VERSION ""

NS_ :

BS_:

BU_: AGSM ECM EVCU2 MCPA MCPB SGCP TCM

BO_ 125 GLIWA_SGCP_TX: 8 SGCP
 SG_ N_PDU_7D : 7|64@0+ (1,0) [0|0] ""  EVCU2

BO_ 129 GLIWA_SGCP_RX: 8 EVCU2
 SG_ N_PDU_81 : 7|64@0+ (1,0) [0|0] ""  SGCP

BO_ 126 GLIWA_MCPA_RX: 8 EVCU2
 SG_ N_PDU_7E : 7|64@0+ (1,0) [0|0] ""  MCPA

BO_ 123 GLIWA_MCPA_TX: 8 MCPA
 SG_ N_PDU_7B : 7|64@0+ (1,0) [0|0] ""  EVCU2

BO_ 127 GLIWA_MCPB_RX: 8 EVCU2
 SG_ N_PDU_7F : 7|64@0+ (1,0) [0|0] ""  MCPB

BO_ 124 GLIWA_MCPB_TX: 8 MCPB
 SG_ N_PDU_7C : 7|64@0+ (1,0) [0|0] ""  EVCU2

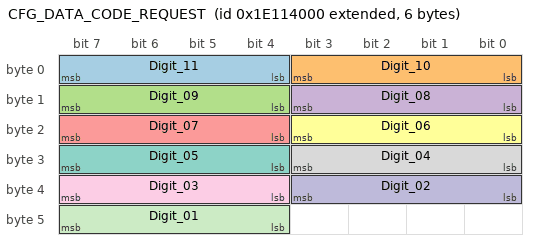
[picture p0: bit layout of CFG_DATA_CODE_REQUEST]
BO_ 2651930624 CFG_DATA_CODE_REQUEST: 6 EVCU2
 SG_ Digit_11 : 7|4@0+ (1,0) [0|15] ""  SGCP,MCPB,MCPA
 SG_ Digit_10 : 3|4@0+ (1,0) [0|15] ""  SGCP,MCPB,MCPA
 SG_ Digit_09 : 15|4@0+ (1,0) [0|15] ""  SGCP,MCPB,MCPA
 SG_ Digit_08 : 11|4@0+ (1,0) [0|15] ""  SGCP,MCPB,MCPA
 SG_ Digit_07 : 23|4@0+ (1,0) [0|15] ""  SGCP,MCPB,MCPA
 SG_ Digit_06 : 19|4@0+ (1,0) [0|15] ""  SGCP,MCPB,MCPA
 SG_ Digit_05 : 31|4@0+ (1,0) [0|15] ""  SGCP,MCPB,MCPA
 SG_ Digit_04 : 27|4@0+ (1,0) [0|15] ""  SGCP,MCPB,MCPA
 SG_ Digit_03 : 39|4@0+ (1,0) [0|15] ""  SGCP,MCPB,MCPA
 SG_ Digit_02 : 35|4@0+ (1,0) [0|15] ""  SGCP,MCPB,MCPA
 SG_ Digit_01 : 47|4@0+ (1,0) [0|15] ""  SGCP,MCPB,MCPA

BO_ 2564502513 DIAGNOSTIC_REQUEST_FUNC_OBD: 8 EVCU2
 SG_ N_PDU_18DB33F1 : 7|64@0+ (1,0) [0|0] ""  SGCP,MCPB,MCPA

BO_ 1450 TRANSM_FD_4: 32 TCM
 SG_ TxDisengaged : 126|1@0+ (1,0) [0|1] "-"  ECM
 SG_ TransmissionFailSts : 87|1@0+ (1,0) [0|1] "-"  AGSM
 SG_ ShiftLeverPosition : 111|4@0+ (1,0) [0|15] "-"  AGSM,ECM
 SG_ ShiftLeverLockReq : 101|1@0+ (1,0) [0|1] "-"  AGSM
 SG_ ShiftInProgress : 114|1@0+ (1,0) [0|1] "-"  ECM
 SG_ MIReq : 127|1@0+ (1,0) [0|1] "-"  ECM
 SG_ LimpHomeSts : 112|1@0+ (1,0) [0|1] "-"  ECM
 SG_ GearIndicationSts : 95|1@0+ (1,0) [0|1] "-"  AGSM
 SG_ GearEngaged : 107|4@0+ (1,0) [0|15] "-"  ECM
 SG_ CrankEnable : 113|1@0+ (1,0) [0|1] "-" Vector__XXX
 SG_ ShiftMapNotAchieved : 121|1@0+ (1,0) [0|1] "-" Vector__XXX
 SG_ R_SHFT_LOCK : 116|1@0+ (1,0) [0|1] "-"  AGSM
 SG_ MessageCounter_TRANSM4 : 179|4@0+ (1,0) [0|15] "-"  AGSM,ECM
 SG_ CRC_TRANSM4 : 191|8@0+ (1,0) [0|255] "-"  AGSM,ECM
 SG_ DriveModeSts : 83|4@0+ (1,0) [0|15] "-"  ECM
 SG_ TxDisengaged_Fault : 118|1@0+ (1,0) [0|1] "-"  ECM
 SG_ Lowmode_Indication_Sts : 183|2@0+ (1,0) [0|3] ""  AGSM
 SG_ Low_Mode_Sts : 181|2@0+ (1,0) [0|3] ""  AGSM

BO_ 520 TRANSM_FD_2: 32 TCM
 SG_ TurbineSpeed : 111|16@0+ (1,0) [0|65534] "RPM"  ECM
 SG_ TRNS_StpSt_FLT : 125|1@0+ (1,0) [0|1] "-"  ECM
 SG_ Trns_EMCC_Achvd : 96|1@0+ (1,0) [0|1] "-"  ECM
 SG_ TransReadyForESS : 124|1@0+ (1,0) [0|1] "-"  ECM
 SG_ TransmissionTemperature : 103|6@0+ (3,-40) [-40|149] "°C"  ECM
 SG_ OUTPUT_SPEED : 87|16@0+ (1,0) [0|65534] "RPM"  ECM
 SG_ APCM_Rq : 135|2@0+ (1,0) [0|2] "-"  AGSM,ECM
 SG_ MessageCounter_TRANSM2 : 179|4@0+ (1,0) [0|15] "-"  AGSM,ECM
 SG_ EngShutOffRq_TCM : 123|1@0+ (1,0) [0|1] "-"  ECM
 SG_ CRC_TRANSM2 : 191|8@0+ (1,0) [0|255] "-"  AGSM,ECM
 SG_ Trans_ESS_Inhibit : 2|1@0+ (1,0) [0|1] "-"  ECM
 SG_ OutputSpdPolarity : 1|2@0+ (1,0) [0|2] "-" Vector__XXX
 SG_ GearEngagedForDisplay : 15|5@0+ (1,0) [0|30] "-"  AGSM,ECM
 SG_ AirFlowRequest_TCM : 22|7@0+ (1,0) [0|100] "%"  ECM
 SG_ TrqCtrlModeReq_Prdtd : 129|2@0+ (1,0) [0|3] "-"  ECM
 SG_ TCM_TrqGradLimActive : 161|1@0+ (1,0) [0|1] "-"  ECM
 SG_ TCM_TrqGradLim_Up : 151|8@0+ (49.8,-6325) [-6325|6374] "Nm/s"  ECM
 SG_ TCM_TrqGradLim_Lo : 159|8@0+ (49.8,-6325) [-6325|6374] "Nm/s"  ECM
 SG_ TCM_EngFSO_Rq : 120|1@0+ (1,0) [0|1] "-"  ECM
 SG_ TCM_EngFSO_Allw : 62|1@0+ (1,0) [0|1] "-"  ECM
 SG_ TCC_TR : 143|8@0+ (0.125,0) [0|31.875] "Nm" Vector__XXX
 SG_ TransInputSpeedMaxReq : 57|10@0+ (16,0) [0|16368] "rpm"  ECM

BO_ 156 TELEMATIC_FD_1: 32 EVCU2
 SG_ GPS_UTC_Second : 151|16@0+ (0.01,0) [0|59.99] "s"  MCPB,MCPA
 SG_ GPS_UTC_Minute : 47|8@0+ (1,0) [0|59] "min"  MCPB,MCPA
 SG_ GPS_UTC_Hour : 55|8@0+ (1,0) [0|23] "h"  MCPB,MCPA
 SG_ GPS_Date_Year : 167|16@0+ (1,0) [0|65534] "Years"  MCPB,MCPA
 SG_ GPS_Date_Month : 71|8@0+ (1,0) [1|12] "Months"  MCPB,MCPA
 SG_ GPS_Date_Day : 63|8@0+ (1,0) [1|31] "Days"  MCPB,MCPA

BO_ 1058 OBD_CONTENT_FRAME: 32 ECM
 SG_ LoadOBD : 87|8@0+ (0.3922,0) [0|100] "%"  TCM
 SG_ InputsGDFail : 94|1@0+ (1,0) [0|1] "-"  TCM
 SG_ Inp_ICC_Fail : 117|1@0+ (1,0) [0|1] "-"  TCM
 SG_ IgnCntrTrue : 118|1@0+ (1,0) [0|1] "-"  TCM
 SG_ GenDenominator : 95|1@0+ (1,0) [0|1] "-"  TCM
 SG_ EngineOFFTime : 89|10@0+ (1,0) [0|1022] "min"  TCM
 SG_ CldStrtDenominator : 116|1@0+ (1,0) [0|1] "-" Vector__XXX
 SG_ CarbWarmUp : 93|1@0+ (1,0) [0|1] "-"  TCM
 SG_ CARB_PERM : 119|1@0+ (1,0) [0|1] "-"  TCM
 SG_ AccelPdlPosn_OBD : 111|8@0+ (0.3922,0) [0|100] "%"  TCM
 SG_ OAT_PT_EstV : 60|1@0+ (1,0) [0|0] "-"  EVCU2
 SG_ OAT_PT_Est : 55|8@0+ (1,-64) [-64|191] "°C"  EVCU2
 SG_ EngOffTmPTV : 5|1@0+ (1,0) [0|0] "-"  EVCU2
 SG_ EngOffTmPT : 3|12@0+ (0.5,0) [0.5|2047.5] "min"  EVCU2
 SG_ MessageCounter_OBDCONTENTFRAME : 179|4@0+ (1,0) [0|15] "-"  EVCU2,TCM
 SG_ CRC_OBDCONTENTFRAME : 191|8@0+ (1,0) [0|255] "-"  EVCU2,TCM

BO_ 1626 IMPACT_INFO: 32 EVCU2
 SG_ IMPACTConfirm : 81|1@0+ (1,0) [0|1] "-"  MCPB,MCPA
 SG_ IMPACTCommand : 80|1@0+ (1,0) [0|1] "-"  MCPB,MCPA

BO_ 1055 ENGINE_FD_8: 32 ECM
 SG_ MdsAct : 25|1@0+ (1,0) [0|1] "-"  TCM
 SG_ MessageCounter_ENGINE8 : 179|4@0+ (1,0) [0|15] "-"  TCM
 SG_ CRC_ENGINE8 : 191|8@0+ (1,0) [0|255] "-"  TCM

BO_ 1448 ENGINE_FD_7: 32 ECM
 SG_ CompressorSts : 85|2@0+ (1,0) [0|3] "-"  TCM
 SG_ SpStSwStat : 55|2@0+ (1,0) [0|3] "-" Vector__XXX
 SG_ SpStDispstat : 53|6@0+ (1,0) [0|63] "-"  TCM
 SG_ MessageCounter_ENGINE7 : 179|4@0+ (1,0) [0|15] "-"  TCM
 SG_ CRC_ENGINE7 : 191|8@0+ (1,0) [0|255] "-"  TCM

BO_ 751 ENGINE_FD_6: 32 ECM
 SG_ StartRelayECMFeedbackFault : 163|1@0+ (1,0) [0|1] "-" Vector__XXX
 SG_ EngineWaterTemp : 95|8@0+ (1,-40) [-40|215] "°C"  TCM
 SG_ TerrainModeStat_ECM : 61|5@0+ (1,0) [0|30] ""  TCM
 SG_ MessageCounter_ENGINE6 : 179|4@0+ (1,0) [0|15] "-"  TCM
 SG_ CRC_ENGINE6 : 191|8@0+ (1,0) [0|255] "-"  TCM
 SG_ Trns_DrvMdReq_ECM : 77|5@0+ (1,0) [0|30] "-"  TCM

BO_ 518 ENGINE_FD_5: 32 ECM
 SG_ RPMOverRev_W : 115|1@0+ (1,0) [0|1] "-"  EVCU2
 SG_ MessageCounter_ENGINE5 : 179|4@0+ (1,0) [0|15] "-"  EVCU2,TCM
 SG_ GrMin_Rq_ECM_W : 139|4@0+ (1,0) [0|15] "-"  TCM
 SG_ GrMax_Rq_ECM_W : 135|4@0+ (1,0) [0|15] "-"  TCM
 SG_ EngTrqMaxCorrFctr_W : 127|8@0+ (0.0078,0) [0|1.98] "Nm"  TCM
 SG_ EngineReadyForESS_W : 116|1@0+ (1,0) [0|1] "-"  TCM
 SG_ ECM_READINESS_RESET_W : 140|1@0+ (1,0) [0|0] "0"  TCM
 SG_ ECM_CODE_CLR_W : 141|1@0+ (1,0) [0|0] "0"  TCM
 SG_ CRC_ENGINE5 : 191|8@0+ (1,0) [0|255] "-"  EVCU2,TCM

BO_ 1054 ENGINE_FD_1: 32 ECM
 SG_ VehicleSetSpeed_W : 151|8@0+ (1,0) [0|250] "km/h(mph)"  TCM
 SG_ TransWarmUpReq : 3|1@0+ (1,0) [0|1] "-"  TCM
 SG_ TransWarmUpMin_RPM : 159|8@0+ (25,0) [0|6375] "rpm"  TCM
 SG_ ThermalManagementActive_W : 1|1@0+ (1,0) [0|1] "-"  EVCU2,TCM
 SG_ MessageCounter_ENGINE1 : 179|4@0+ (1,0) [0|15] "-"  EVCU2,TCM
 SG_ EngMaxRPM_W : 127|8@0+ (50,0) [0|10000] "-"  TCM
 SG_ CRC_ENGINE1 : 191|8@0+ (1,0) [0|255] "-"  EVCU2,TCM
 SG_ AtmosphericPressureFailSts_W : 0|1@0+ (1,0) [0|1] "-"  TCM
 SG_ AtmosphericPressure_W : 143|8@0+ (3.6,300) [300|1214.4] "mbar"  TCM

BO_ 2654817816 ECU_APPL_FD_TCM: 64 TCM
 SG_ ECU_APPL_FD_TCM : 455|64@0+ (1,0) [0|0] "" Vector__XXX

BO_ 2564554482 DIAGNOSTIC_REQUEST_FD_FUNCTIONAL: 64 EVCU2
 SG_ N_PDU_18DBFEF2 : 7|64@0+ (1,0) [0|0] ""  SGCP,MCPB,MCPA

BO_ 1155 BRAKE_FD_5: 32 EVCU2
 SG_ ESCFailSts : 83|1@0+ (1,0) [0|1] "-"  MCPB
 SG_ ABSFailSts : 87|1@0+ (1,0) [0|1] "-"  MCPB

BO_ 609 BRAKE_FD_4: 32 EVCU2
 SG_ EPBSts : 115|4@0+ (1,0) [0|14] "-"  SGCP,MCPB,MCPA

BO_ 1066 BCM_FD_9: 32 EVCU2
 SG_ ExternalTemperature : 0|9@0+ (0.5,-85) [-85|170] "°C"  SGCP,MCPB,MCPA

BO_ 1153 BCM_FD_10: 32 EVCU2
 SG_ CmdIgnSts : 138|3@0+ (1,0) [0|7] ""  MCPB,MCPA,AGSM
 SG_ MessageCounter_BCM10 : 179|4@0+ (1,0) [0|15] "-"  MCPB
 SG_ CRC_BCM10 : 191|8@0+ (1,0) [0|255] "-"  MCPB

BO_ 255 PT_TORQUE_FD_1: 48 ECM
 SG_ SumTorqueTgt_SEM : 130|11@0+ (1,-500) [-500|1546] "Nm"  TCM
 SG_ SumTorqueStatic_SEM : 114|11@0+ (1,-500) [-500|1546] "Nm"  TCM
 SG_ SumTorqueStatic : 98|11@0+ (1,-500) [-500|1546] "Nm"  TCM
 SG_ SumTorqueSel_D_TTC : 82|11@0+ (1,-500) [-500|1546] "Nm"  TCM
 SG_ SumTorqueMin : 66|11@0+ (1,-500) [-500|1546] "Nm"  TCM
 SG_ SumTorqueMax : 50|11@0+ (1,-500) [-500|1546] "Nm"  TCM
 SG_ SumTorque_DrvReqMod : 20|13@0+ (0.25,-500) [-500|1547.5] "Nm"  TCM
 SG_ MessageCounter_PT_TORQUE_FD_1 : 307|4@0+ (1,0) [0|15] "-"  TCM
 SG_ CRC_PT_TORQUE_FD_1 : 319|8@0+ (1,0) [0|255] "-"  TCM
 SG_ Accel_Pedal_Override : 37|1@0+ (1,0) [0|1] "-" Vector__XXX

BO_ 1032 HYBRID_THERMAL_COMMAND: 32 EVCU2
 SG_ MessageCounter_HYBRID_THERMAL_CO : 179|4@0+ (1,0) [0|15] "-"  SGCP,MCPB,MCPA,ECM
 SG_ CRC_HYBRID_THERMAL_COMMAND : 191|8@0+ (1,0) [0|255] "-"  SGCP,MCPB,MCPA,ECM
 SG_ SGCP_OIL_TEMP : 175|8@0+ (1,-50) [-50|205] "°C"  SGCP
 SG_ SGCP_OIL_FlwRate : 135|8@0+ (0.1,0) [0|25.4] "LPM"  SGCP
 SG_ EOPB_OIL_TEMP : 151|8@0+ (1,-50) [-50|205] "°C"  MCPB
 SG_ EOPB_OIL_FlwRate : 167|8@0+ (0.1,0) [0|25.4] "LPM"  MCPB
 SG_ EOPA_OIL_TEMP : 143|8@0+ (1,-50) [-50|205] "°C"  MCPA
 SG_ EOPA_OIL_FlwRate : 159|8@0+ (0.1,0) [0|25.4] "LPM"  MCPA

BO_ 267 HYBRID_SYSTEM_EPT1: 32 EVCU2
 SG_ WU_Timer_Value : 23|16@0+ (1,0) [0|65535] "min"  MCPB,MCPA
 SG_ PerWakeUp_Diag : 33|10@0+ (1,0) [0|1023] "-"  MCPB,MCPA

BO_ 1033 HYBRID_POWERTRAIN5: 32 EVCU2
 SG_ IdleCLoopTrq : 33|10@0+ (0.32,-163.52) [-163.52|163.52] "Nm"  ECM
 SG_ HEV_HybPwrtrnRdcdPerfCmnd : 22|1@0+ (1,0) [0|0] "-"  ECM
 SG_ HCPMaxEngRPM : 63|8@0+ (32,0) [0|8128] "rpm"  ECM
 SG_ CRC_HYBRID_POWERTRAIN5 : 191|8@0+ (1,0) [0|255] "-"  ECM
 SG_ MessageCounter_HYBRID_POWERTRAIN : 179|4@0+ (1,0) [0|15] "-"  ECM
 SG_ HCP_HoodAjar : 35|2@0+ (1,0) [0|2] ""  ECM

BO_ 1328 ENGINE_HYBD_FD_4: 32 ECM
 SG_ EngTorqCapbltyMinTorq : 51|12@0+ (0.32,-300.16) [-300.16|1008] "Nm"  EVCU2
 SG_ EngTorqCapbltyMaxTorq : 19|12@0+ (0.32,-300.16) [-300.16|1008] "Nm"  EVCU2
 SG_ EngTorqCapbltyMaxOffTorq : 3|12@0+ (0.32,-300.16) [-300.16|1008] "Nm"  EVCU2
 SG_ EngTorqCapbltyRefEngSpd : 71|8@0+ (32,0) [0|8160] "rpm"  EVCU2
 SG_ EngTorqCapbltyMinRunTorq : 35|12@0+ (0.32,-300.16) [-300.16|1008] "Nm"  EVCU2
 SG_ EngTorqCapbltyFrmCntr : 7|4@0+ (1,0) [0|15] "-"  EVCU2
 SG_ EngTorqCapbltyEngOpMd : 21|1@0+ (1,0) [0|0] "-"  EVCU2
 SG_ EngTorqACCCapability : 79|8@0+ (0.32,0) [0|81.28] "Nm"  EVCU2
 SG_ MessageCounter_ENGINE_HYBD_FD_4 : 179|4@0+ (1,0) [0|15] "-"  EVCU2
 SG_ CRC_ENGINE_HYBD_FD_4 : 191|8@0+ (1,0) [0|255] "-"  EVCU2

BO_ 1035 ENGINE_HYBD_FD_3: 32 ECM
 SG_ MaxEngSpdCap : 52|13@0+ (1,0) [0|8160] "rpm"  EVCU2
 SG_ ServiceHybSys : 55|1@0+ (1,0) [0|0] "-"  EVCU2
 SG_ MinEngSpdCap : 68|13@0+ (1,0) [0|8160] "rpm"  EVCU2
 SG_ EngSpd : 7|16@0+ (0.125,0) [0|8160] "rpm"  EVCU2
 SG_ EngCltTmpV : 69|1@0+ (1,0) [0|1] ""  EVCU2
 SG_ EngCltTmp : 167|8@0+ (1,-40) [-40|214] "°C"  EVCU2
 SG_ MessageCounter_ENGINE_HYBD_FD_3 : 179|4@0+ (1,0) [0|15] "-"  EVCU2
 SG_ CRC_ENGINE_HYBD_FD_3 : 191|8@0+ (1,0) [0|255] "-"  EVCU2

BO_ 1036 ENGINE_FD_3: 32 ECM
 SG_ CruiseControlSts : 162|1@0+ (1,0) [0|1] "-"  TCM
 SG_ CruiseControlLampSts : 164|1@0+ (1,0) [0|1] "-"  TCM
 SG_ MessageCounter_ENGINE3 : 179|4@0+ (1,0) [0|15] "-"  TCM
 SG_ CRC_ENGINE3 : 191|8@0+ (1,0) [0|255] "-"  TCM
 SG_ EngineOilTemperature : 103|8@0+ (1,-40) [-40|214] "°C"  TCM

BO_ 278 TRANSM_FD_1: 64 TCM
 SG_ TransmissionSailingSts : 119|4@0+ (1,0) [0|15] "-" Vector__XXX
 SG_ TransLosses : 241|10@0+ (1,-500) [-500|522] "Nm"  ECM
 SG_ TorqueConverterSts : 55|2@0+ (1,0) [0|3] "-"  ECM
 SG_ TorqueConverterSTO : 195|1@0+ (1,0) [0|1] "-"  ECM
 SG_ TargetGear : 151|4@0+ (1,0) [0|15] "-"  ECM
 SG_ MaxTrqDes : 162|11@0+ (1,-500) [-500|1546] "Nm"  ECM
 SG_ EngTrq_Rq_TCM : 178|11@0+ (1,-500) [-500|1546] "Nm"  ECM
 SG_ CRC_TRANSM1 : 447|8@0+ (1,0) [0|255] "-"  ECM
 SG_ REPRGD_PFC_CLR_TCM : 275|1@0+ (1,0) [0|0] "-"  ECM
 SG_ PaddleShiftRequest : 399|3@0+ (1,0) [0|6] "-"  ECM
 SG_ MessageCounter_TRANSM1 : 435|4@0+ (1,0) [0|15] "-"  ECM
 SG_ DriveLineRatio : 405|14@0+ (0.01,0) [0|163.83] "-"  ECM
 SG_ CODE_CLR_TCM : 258|1@0+ (1,0) [0|0] "-"  ECM
 SG_ TxIdleRq : 351|8@0+ (8,0) [0|2032] "rpm"  ECM
 SG_ TCASERANGESTATUS_TCM : 407|2@0+ (1,0) [0|2] "-"  ECM
 SG_ Trans_Adapt_Status : 423|4@0+ (1,0) [0|15] "-"  ECM
 SG_ TorqueAmpTransmission : 330|11@0+ (0.01,0) [0|20.46] "-"  ECM
 SG_ TrqCtrlModeReq : 23|2@0+ (1,0) [0|2] "-"  ECM
 SG_ TransIntakeTorq : 210|11@0+ (1.2,-1200) [-1200|1255.2] "Nm"  ECM
 SG_ CrankEnable_Fast : 211|1@0+ (1,0) [0|1] "-"  ECM
 SG_ EngTrq_Rq_TCM_Prdtd : 194|11@0+ (1,-500) [-500|1547] "Nm"  ECM
 SG_ PumpTrqOnImpShaft : 305|10@0+ (0.2,-102.4) [-102.4|102.2] "Nm"  ECM

BO_ 269 HYBRID_POWERTRAIN2: 64 EVCU2
 SG_ IdleSpeedActiveSts : 302|1@0+ (1,0) [0|0] "-"  ECM
 SG_ CRC_HYBRID_POWERTRAIN2 : 447|8@0+ (1,0) [0|255] "-"  ECM
 SG_ PropulsionMode : 39|3@0+ (1,0) [0|6] "-"  ECM
 SG_ HybridEngineMaxTorqAllowed : 115|12@0+ (0.32,-300.16) [-300.16|1008] "Nm"  ECM
 SG_ MessageCounter_HYBRID_POWER_0000 : 435|4@0+ (1,0) [0|15] "-"  ECM

BO_ 276 HYBRID_POWERTRAIN1: 64 EVCU2
 SG_ TransInpSpdPrfl : 68|13@0+ (1,0) [0|8191] "rpm"  ECM
 SG_ InputSpdRaw : 179|12@0+ (1,-2048) [-2048|2046] "rpm"  ECM
 SG_ Hybrid_Remedial_Stop : 290|1@0+ (1,0) [0|0] "-"  ECM
 SG_ HybFeedback_Engine : 294|1@0+ (1,0) [0|0] "-"  ECM
 SG_ HybEstEngTorqV : 280|1@0+ (1,0) [0|0] "-"  ECM
 SG_ HybEstEngTorq : 163|12@0+ (0.32,-300.16) [-300.16|1008] "Nm"  ECM
 SG_ HybCrnkAbrted : 282|1@0+ (1,0) [0|0] "-"  ECM
 SG_ HybCmndEngTorqRespTyp : 277|2@0+ (1,0) [0|0] "-"  ECM
 SG_ HybCmndEngTorqPrdtd : 147|12@0+ (0.32,-300.16) [-300.16|1008] "Nm"  ECM
 SG_ HybCmndEngTorqImmed : 131|12@0+ (0.32,-300.16) [-300.16|1008] "Nm"  ECM
 SG_ EngTrqReserveCmd : 263|8@0+ (0.32,0) [0|81.28] "Nm"  ECM
 SG_ EngCntrlMode : 283|1@0+ (1,0) [0|0] "-"  ECM
 SG_ ECMPrepIdleRes : 295|1@0+ (1,0) [0|0] "-"  ECM
 SG_ CRC_HYBRID_POWERTRAIN1 : 447|8@0+ (1,0) [0|255] "-"  ECM
 SG_ PropulsionSystemActive : 408|1@0+ (1,0) [0|1] "-"  ECM
 SG_ MessageCounter_HYBRID_POWER_0001 : 435|4@0+ (1,0) [0|15] "-"  ECM

BO_ 271 ENGINE_HYBD_FD_1: 64 ECM
 SG_ Sum_FW_ID_Slw : 327|5@0+ (1,0) [0|30] "-"  EVCU2
 SG_ Sum_FW_ID_Fst : 367|5@0+ (1,0) [0|30] "-"  EVCU2
 SG_ MinPrdtdEngRunTorqCapV : 213|1@0+ (1,0) [0|0] "-"  EVCU2
 SG_ MinPrdtdEngRunTorqCap : 243|12@0+ (0.32,-300.16) [-300.16|1008] "Nm"  EVCU2
 SG_ MinImmedEngTorqCapV : 215|1@0+ (1,0) [0|0] "-"  EVCU2,TCM
 SG_ MinImmedEngTorqCap : 227|12@0+ (0.32,-300.16) [-300.16|1008] "Nm"  EVCU2,TCM
 SG_ MinEngTorqCapV : 196|1@0+ (1,0) [0|0] "-"  EVCU2
 SG_ MinEngTorqCap : 211|12@0+ (0.32,-300.16) [-300.16|1008] "Nm"  EVCU2
 SG_ MinAirFlowMinSparkTorqCapV : 197|1@0+ (1,0) [0|0] "-"  EVCU2,TCM
 SG_ MinAirFlowMinSparkTorqCap : 195|12@0+ (0.32,-300.16) [-300.16|1008] "Nm"  EVCU2,TCM
 SG_ MessageCounter_ENGINE_HYBD_FD_1 : 435|4@0+ (1,0) [0|15] "-"  EVCU2,TCM
 SG_ MaxPrdtdEngTorqCapV : 198|1@0+ (1,0) [0|0] "-"  EVCU2,TCM
 SG_ MaxPrdtdEngTorqCap : 179|12@0+ (0.32,-300.16) [-300.16|1008] "Nm"  EVCU2,TCM
 SG_ MaxOffEngTorqCap : 163|12@0+ (0.32,-300.16) [-300.16|1008] "Nm"  EVCU2
 SG_ HybActEngTorqRespTyp : 149|2@0+ (1,0) [0|0] "-"  EVCU2
 SG_ Feedback_HCP : 293|1@0+ (1,0) [0|0] "-"  EVCU2
 SG_ ETRQ_Mode : 362|3@0+ (1,0) [0|5] "-"  EVCU2
 SG_ EngTrqReserveReq : 351|8@0+ (0.32,0) [0|81.28] "Nm"  EVCU2
 SG_ EngRunCrnkAct : 295|1@0+ (1,0) [0|0] "-"  EVCU2
 SG_ EngAirFlwStdyStTorqV : 262|1@0+ (1,0) [0|0] "-"  EVCU2,TCM
 SG_ EngAirFlwStdyStTorq : 275|12@0+ (0.32,-300.16) [-300.16|1008] "Nm"  EVCU2,TCM
 SG_ EngActuatorsStat : 133|2@0+ (1,0) [0|0] "-"  EVCU2
 SG_ EngActStdyStTorqV : 263|1@0+ (1,0) [0|0] "-"  EVCU2
 SG_ EngActStdyStTorq : 259|12@0+ (0.32,-300.16) [-300.16|1008] "Nm"  EVCU2
 SG_ CRC_ENGINE_HYBD_FD_1 : 447|8@0+ (1,0) [0|255] "-"  EVCU2,TCM
 SG_ MAP_4_BAR_PHEV : 392|9@0+ (0.8,0) [0|408] "kPa"  EVCU2
 SG_ RedSpkAuthorityAvbl : 308|1@0+ (1,0) [0|1] ""  EVCU2
 SG_ EngMinSparkNomCurrAirTorqCap : 82|11@0+ (1,-500) [-500|1547] "Nm"  EVCU2
 SG_ EngTrqFSO_CurrAir : 391|12@0+ (0.32,-300.16) [-300.16|1008] "Nm"  TCM

CM_ "Project_WS25_ProjectStandard_FD-CAN16 [CS00155_FD]";
CM_ SG_ 2564502513 N_PDU_18DB33F1 "This signal is used for diagnostic purposes";
CM_ SG_ 1450 TxDisengaged "Transmission is disengaged";
CM_ SG_ 1450 TransmissionFailSts "This signal indicates if the TCM currently detects the failure or not (for TCM)";
CM_ SG_ 1450 ShiftLeverPosition "This signal indicates the executed shift lever position.";
CM_ SG_ 1450 ShiftLeverLockReq "-";
CM_ SG_ 1450 ShiftInProgress "Transmission shift in progress";
CM_ SG_ 1450 MIReq "This signal indicates that the gearbox has any EOBD errors.";
CM_ SG_ 1450 LimpHomeSts "This signal is used in case of those gearbox faults that limit the higher usable gear.";
CM_ SG_ 1450 GearIndicationSts "-";
CM_ SG_ 1450 GearEngaged "Current engaged gear.";
CM_ SG_ 1450 CrankEnable "This signal is used to enable the cranking in safety condition";
CM_ SG_ 1450 ShiftMapNotAchieved "Transmission shift in progress";
CM_ SG_ 1450 R_SHFT_LOCK "Shiftlock for reverse; locked = [1]";
CM_ SG_ 1450 MessageCounter_TRANSM4 "This signal is a counter used for safety checks strategies. This counter is incremented of 1 (one) unit at each frame transmission.";
CM_ SG_ 1450 CRC_TRANSM4 "CRC according to SAE J1850 standard at each frame transmission.";
CM_ SG_ 1450 DriveModeSts "-";
CM_ SG_ 1450 TxDisengaged_Fault "Transmission is disengaged";
CM_ SG_ 1450 Lowmode_Indication_Sts "Signal Indicating L Mode Indication Status";
CM_ SG_ 1450 Low_Mode_Sts "Signal Indicating L Mode Status";
CM_ SG_ 520 TurbineSpeed "-";
CM_ SG_ 520 TRNS_StpSt_FLT "-";
CM_ SG_ 520 Trns_EMCC_Achvd "-";
CM_ SG_ 520 TransReadyForESS "-";
CM_ SG_ 520 TransmissionTemperature "-";
CM_ SG_ 520 OUTPUT_SPEED "Activation request flag for P2 speed  profile";
CM_ SG_ 520 APCM_Rq "Auto position correction mode request";
CM_ SG_ 520 MessageCounter_TRANSM2 "This signal is a counter used for safety checks strategies. This counter is incremented of 1 (one) unit at each frame transmission.";
CM_ SG_ 520 EngShutOffRq_TCM "TCM request engine shut off";
CM_ SG_ 520 CRC_TRANSM2 "CRC according to SAE J1850 standard at each frame transmission.";
CM_ SG_ 520 Trans_ESS_Inhibit "ESS inhibit flag from transmission related to temperature warnings.";
CM_ SG_ 520 OutputSpdPolarity "Output shaft speed polarity";
CM_ SG_ 520 GearEngagedForDisplay "Transmission Gear engaged signal for Display on cluster.";
CM_ SG_ 520 AirFlowRequest_TCM "Request from TCM to activate AGS,Rad Fan";
CM_ SG_ 520 TrqCtrlModeReq_Prdtd "Predicted Torque Control Mode";
CM_ SG_ 520 TCM_TrqGradLimActive "Trans input torque gradient limit is active";
CM_ SG_ 520 TCM_TrqGradLim_Up "Trans input torque gradient upper limit";
CM_ SG_ 520 TCM_TrqGradLim_Lo "Trans input torque gradient lower limit";
CM_ SG_ 520 TCM_EngFSO_Rq "Fuel Shutoff request by ransmission";
CM_ SG_ 520 TCM_EngFSO_Allw "Signal indicating fuel shutoff allowed for transmission torque request.";
CM_ SG_ 520 TCC_TR "TCC torque multiplication ratio which is a function of current speed ratio across the TCC";
CM_ SG_ 520 TransInputSpeedMaxReq "Transmission request for maximum input speed limit";
CM_ SG_ 156 GPS_UTC_Second "GPS UTC second";
CM_ SG_ 156 GPS_UTC_Minute "GPS UTC minute";
CM_ SG_ 156 GPS_UTC_Hour "GPS UTC hour";
CM_ SG_ 156 GPS_Date_Year "GPS date year";
CM_ SG_ 156 GPS_Date_Month "GPS date month";
CM_ SG_ 156 GPS_Date_Day "GPS date day";
CM_ SG_ 1058 LoadOBD "Engine calculated load value in percentage of load.";
CM_ SG_ 1058 InputsGDFail "General Denominator Requirements Achieved Validity. The engine controller sets this bit when any of the inputs to the General Denominator are in a pending or MIL fault.";
CM_ SG_ 1058 Inp_ICC_Fail "Inputs to the Ign Cycle Cntr are in a Pend or MIL cond.";
CM_ SG_ 1058 IgnCntrTrue "Ignition cycle counter is true [1]";
CM_ SG_ 1058 GenDenominator "General denominator conditions are met.  The engine controller will set this bit when the conditions for setting the General Denominator are met for rate based diagnostics.";
CM_ SG_ 1058 EngineOFFTime "The number of minutes the engine was off.";
CM_ SG_ 1058 CldStrtDenominator "Cold start denominator conditions are met [1]";
CM_ SG_ 1058 CarbWarmUp "CARB warmup criteria true.  The engine controller will set this bit when the engine coolant temp achieves the CARB warm-up criteria.";
CM_ SG_ 1058 CARB_PERM "Fault code for diagnostics.";
CM_ SG_ 1058 AccelPdlPosn_OBD "Pedal value for OBD (ISO 15031-5.4 PID 49)";
CM_ SG_ 1058 OAT_PT_EstV "Outside air temperature powertrain estimated validity; Invalid = [1]";
CM_ SG_ 1058 OAT_PT_Est "Outside air temperature powertrain estimated";
CM_ SG_ 1058 EngOffTmPTV "Engine off time powertrain validity (1=invalid)";
CM_ SG_ 1058 EngOffTmPT "Engine off time powertrain";
CM_ SG_ 1058 MessageCounter_OBDCONTENTFRAME "This signal is a counter used for safety checks strategies. This counter is incremented of 1 (one) unit at each frame transmission.";
CM_ SG_ 1058 CRC_OBDCONTENTFRAME "CRC according to SAE J1850 standard at each frame transmission.";
CM_ SG_ 1626 IMPACTConfirm "This signal is used to confirm that a crash happened";
CM_ SG_ 1626 IMPACTCommand "This signal is used to indicate that a crash happened";
CM_ SG_ 1055 MdsAct "MDS Active";
CM_ SG_ 1055 MessageCounter_ENGINE8 "This signal is a counter used for safety checks strategies. This counter is incremented of 1 (one) unit at each frame transmission.";
CM_ SG_ 1055 CRC_ENGINE8 "CRC according to SAE J1850 standard at each frame transmission.";
CM_ SG_ 1448 CompressorSts "This signal gives information about the present status of A/C external request and actual A/C activation by ECM.";
CM_ SG_ 1448 SpStSwStat "Stop start switch status";
CM_ SG_ 1448 SpStDispstat "Stop start display status";
CM_ SG_ 1448 MessageCounter_ENGINE7 "This signal is a counter used for safety checks strategies. This counter is incremented of 1 (one) unit at each frame transmission.";
CM_ SG_ 1448 CRC_ENGINE7 "CRC according to SAE J1850 standard at each frame transmission.";
CM_ SG_ 751 StartRelayECMFeedbackFault "-";
CM_ SG_ 751 EngineWaterTemp "-";
CM_ SG_ 751 TerrainModeStat_ECM "Used to require a vehicle modality";
CM_ SG_ 751 MessageCounter_ENGINE6 "This signal is a counter used for safety checks strategies. This counter is incremented of 1 (one) unit at each frame transmission.";
CM_ SG_ 751 CRC_ENGINE6 "CRC according to SAE J1850 standard at each frame transmission.";
CM_ SG_ 751 Trns_DrvMdReq_ECM "The requested state of the drive mode feature";
CM_ SG_ 518 RPMOverRev_W "-";
CM_ SG_ 518 MessageCounter_ENGINE5 "This signal is a counter used for safety checks strategies. This counter is incremented of 1 (one) unit at each frame transmission.";
CM_ SG_ 518 GrMin_Rq_ECM_W "Target gear lower limit (ECM requested limit)";
CM_ SG_ 518 GrMax_Rq_ECM_W "Target gear upper limit (ECM requested limit)";
CM_ SG_ 518 EngTrqMaxCorrFctr_W "Factor of reduction from max torque based on ambient conditions";
CM_ SG_ 518 EngineReadyForESS_W "ESS request HIS charget (1=do charge)";
CM_ SG_ 518 ECM_READINESS_RESET_W "Handshake for not to send";
CM_ SG_ 518 ECM_CODE_CLR_W "Handshake for not to send";
CM_ SG_ 518 CRC_ENGINE5 "CRC according to SAE J1850 standard at each frame transmission.";
CM_ SG_ 1054 VehicleSetSpeed_W "-";
CM_ SG_ 1054 TransWarmUpReq "ECM enable flag for transmission warm-up strategy.";
CM_ SG_ 1054 TransWarmUpMin_RPM "Minimum engine speed for transmission warm-up strategy.";
CM_ SG_ 1054 ThermalManagementActive_W "-";
CM_ SG_ 1054 MessageCounter_ENGINE1 "This signal is a counter used for safety checks strategies. This counter is incremented of 1 (one) unit at each frame transmission.";
CM_ SG_ 1054 EngMaxRPM_W "-";
CM_ SG_ 1054 CRC_ENGINE1 "CRC according to SAE J1850 standard at each frame transmission.";
CM_ SG_ 1054 AtmosphericPressureFailSts_W "-";
CM_ SG_ 1054 AtmosphericPressure_W "-";
CM_ SG_ 2654817816 ECU_APPL_FD_TCM "ECU to external application";
CM_ SG_ 2564554482 N_PDU_18DBFEF2 "This signal is used for diagnostic purposes";
CM_ SG_ 1155 ESCFailSts "0";
CM_ SG_ 1155 ABSFailSts "0";
CM_ SG_ 609 EPBSts "0";
CM_ SG_ 1153 CmdIgnSts "Used to give information about the key selector position";
CM_ SG_ 1153 MessageCounter_BCM10 "This signal is a counter used for safety checks strategies. This counter is incremented of 1 (one) unit at each frame transmission.";
CM_ SG_ 1153 CRC_BCM10 "CRC according to SAE J1850 standard at each frame transmission.";
CM_ SG_ 255 SumTorqueTgt_SEM "Target torque (transmission torque request)";
CM_ SG_ 255 SumTorqueStatic_SEM "Static sum torque (transmission torque request)";
CM_ SG_ 255 SumTorqueStatic "Static sum torque (effective sum torque)";
CM_ SG_ 255 SumTorqueSel_D_TTC "Corrected (substitute) driver torque demand";
CM_ SG_ 255 SumTorqueMin "Minimum sum torque";
CM_ SG_ 255 SumTorqueMax "Maximum sum torque";
CM_ SG_ 255 SumTorque_DrvReqMod "Driver requested sum torque modified";
CM_ SG_ 255 MessageCounter_PT_TORQUE_FD_1 "This signal is a counter used for safety checks strategies. This counter is incremented of 1 (one) unit at each frame transmission.";
CM_ SG_ 255 CRC_PT_TORQUE_FD_1 "CRC according to SAE J1850 standard at each frame transmission.";
CM_ SG_ 255 Accel_Pedal_Override "Driver Accelerator Pedal Override. True =[1]";
CM_ SG_ 1032 MessageCounter_HYBRID_THERMAL_CO "This signal is a counter used for safety checks strategies. This counter is incremented of 1 (one) unit at each frame transmission.";
CM_ SG_ 1032 CRC_HYBRID_THERMAL_COMMAND "CRC according to SAE J1850 standard at each frame transmission.";
CM_ SG_ 1032 SGCP_OIL_TEMP "SGCP Oil Temperature in generator";
CM_ SG_ 1032 SGCP_OIL_FlwRate "SGCP Oil Flow Rate through generator";
CM_ SG_ 1032 EOPB_OIL_TEMP "EOPB Oil Temperature in EDM B";
CM_ SG_ 1032 EOPB_OIL_FlwRate "EOPB Oil Flow Rate through EDM B";
CM_ SG_ 1032 EOPA_OIL_TEMP "EOPA Oil Temperature in EDM A";
CM_ SG_ 1032 EOPA_OIL_FlwRate "EOPA Oil Flow Rate through EDM A";
CM_ SG_ 267 WU_Timer_Value "HCP wake-up timer value";
CM_ SG_ 267 PerWakeUp_Diag "Periodic wakeup diagnostics";
CM_ SG_ 1033 IdleCLoopTrq "Electric motor PID torque to maintain idle speed.";
CM_ SG_ 1033 HEV_HybPwrtrnRdcdPerfCmnd "Driver torque request modifier due to system remedial acion";
CM_ SG_ 1033 HCPMaxEngRPM "Engine rev limit due to HCP/MGU limits";
CM_ SG_ 1033 CRC_HYBRID_POWERTRAIN5 "CRC according to SAE J1850 standard at each frame transmission.";
CM_ SG_ 1033 MessageCounter_HYBRID_POWERTRAIN "This signal is a counter used for safety checks strategies. This counter is incremented of 1 (one) unit at each frame transmission.";
CM_ SG_ 1033 HCP_HoodAjar "Diagnosed hood status for HVIL";
CM_ SG_ 1328 EngTorqCapbltyMinTorq "Engine torque capability: minimum torque (fuel off)";
CM_ SG_ 1328 EngTorqCapbltyMaxTorq "Engine torque capability: maximum torque";
CM_ SG_ 1328 EngTorqCapbltyMaxOffTorq "Capability Max-off";
CM_ SG_ 1328 EngTorqCapbltyRefEngSpd "Engine torque capability: reference engine speed";
CM_ SG_ 1328 EngTorqCapbltyMinRunTorq "Engine torque capability: minimum run torque (fuel on)";
CM_ SG_ 1328 EngTorqCapbltyFrmCntr "Engine Torque Capability: Frame Counter (4 bit)";
CM_ SG_ 1328 EngTorqCapbltyEngOpMd "Engine operating mode [0] = non-MDS, [1] = MDS";
CM_ SG_ 1328 EngTorqACCCapability "Eng Trq to be subtracted from the entire capability curve on the HCP side";
CM_ SG_ 1328 MessageCounter_ENGINE_HYBD_FD_4 "This signal is a counter used for safety checks strategies. This counter is incremented of 1 (one) unit at each frame transmission.";
CM_ SG_ 1328 CRC_ENGINE_HYBD_FD_4 "CRC according to SAE J1850 standard at each frame transmission.";
CM_ SG_ 1035 MaxEngSpdCap "Maximum Engine Speed Capacity";
CM_ SG_ 1035 ServiceHybSys "Service Hybrid system; True = [1]";
CM_ SG_ 1035 MinEngSpdCap "Minimum Engine Speed Capacity";
CM_ SG_ 1035 EngSpd "Engine speed";
CM_ SG_ 1035 EngCltTmpV "Engine Coolant Temperature Validity";
CM_ SG_ 1035 EngCltTmp "Engine Coolant Temp";
CM_ SG_ 1035 MessageCounter_ENGINE_HYBD_FD_3 "This signal is a counter used for safety checks strategies. This counter is incremented of 1 (one) unit at each frame transmission.";
CM_ SG_ 1035 CRC_ENGINE_HYBD_FD_3 "CRC according to SAE J1850 standard at each frame transmission.";
CM_ SG_ 1036 CruiseControlSts "It gives information  on C-CAN network about the actual status of cruise control function.";
CM_ SG_ 1036 CruiseControlLampSts "It is the cruise control light command";
CM_ SG_ 1036 MessageCounter_ENGINE3 "This signal is a counter used for safety checks strategies. This counter is incremented of 1 (one) unit at each frame transmission.";
CM_ SG_ 1036 CRC_ENGINE3 "CRC according to SAE J1850 standard at each frame transmission.";
CM_ SG_ 1036 EngineOilTemperature "Engine Oil Temperature";
CM_ SG_ 278 TransmissionSailingSts "This signal indicates the status of the Sailing functionality";
CM_ SG_ 278 TransLosses "Transmission drag torques";
CM_ SG_ 278 TorqueConverterSts "This signal indicates the control phase of lockup clutch.";
CM_ SG_ 278 TorqueConverterSTO "Conf. (torque converter lock-up) Starts to open";
CM_ SG_ 278 TargetGear "Tells of the intended target gear that the transmission will be shifting to. Also includes an cancel shift that the DASM uses for better control.";
CM_ SG_ 278 MaxTrqDes "Maximum engine torque desired";
CM_ SG_ 278 EngTrq_Rq_TCM "Requested engine torque";
CM_ SG_ 278 CRC_TRANSM1 "CRC according to SAE J1850 standard at each frame transmission.";
CM_ SG_ 278 REPRGD_PFC_CLR_TCM "Set readiness to incomplete";
CM_ SG_ 278 PaddleShiftRequest "Paddle shifter request by driver";
CM_ SG_ 278 MessageCounter_TRANSM1 "This signal is a counter used for safety checks strategies. This counter is incremented of 1 (one) unit at each frame transmission.";
CM_ SG_ 278 DriveLineRatio "Drive Line Ratio";
CM_ SG_ 278 CODE_CLR_TCM "Clear emission related faults";
CM_ SG_ 278 TxIdleRq "-";
CM_ SG_ 278 TCASERANGESTATUS_TCM "Transfer case Range status from Transmission";
CM_ SG_ 278 Trans_Adapt_Status "Transmission clutch adaptation status";
CM_ SG_ 278 TorqueAmpTransmission "It is the torque transmission ratio from gearbox primary to wheels, calculated by gearbox . It is only used in Automatic Transmission application";
CM_ SG_ 278 TrqCtrlModeReq "Torque control mode request";
CM_ SG_ 278 TransIntakeTorq "Transmission intake torque";
CM_ SG_ 278 CrankEnable_Fast "This signal is used to enable the cranking in safety condition";
CM_ SG_ 278 EngTrq_Rq_TCM_Prdtd "Predicted Transmission Torque Request";
CM_ SG_ 278 PumpTrqOnImpShaft "Torque on Impeller shaft for transmission pump";
CM_ SG_ 269 IdleSpeedActiveSts "Flag to indicate idle speed target [1] = TRUE";
CM_ SG_ 269 CRC_HYBRID_POWERTRAIN2 "CRC according to SAE J1850 standard at each frame transmission.";
CM_ SG_ 269 PropulsionMode "Propulsion mode of the vehicle";
CM_ SG_ 269 HybridEngineMaxTorqAllowed "HCP maximum torque limit";
CM_ SG_ 269 MessageCounter_HYBRID_POWER_0000 "This signal is a counter used for safety checks strategies. This counter is incremented of 1 (one) unit at each frame transmission.";
CM_ SG_ 276 TransInpSpdPrfl "Transmission Input Speed Profile";
CM_ SG_ 276 InputSpdRaw "Trans input speed from HCP.";
CM_ SG_ 276 Hybrid_Remedial_Stop "Engine Start Allowed.0 = ENG_ON_ALLOWED, 1 = ENG_ON_NOT_ALLOW";
CM_ SG_ 276 HybFeedback_Engine "Indication that the HCP is receiving valid data from the ECM. 0 - False; 1 - True.";
CM_ SG_ 276 HybEstEngTorqV "Hybrid estimated engine torque validity. 0 = Valid, 1 = Invalid";
CM_ SG_ 276 HybEstEngTorq "Hybrid estimated engine torque";
CM_ SG_ 276 HybCrnkAbrted "Hybrid Crank Aborted";
CM_ SG_ 276 HybCmndEngTorqRespTyp "Hybrid Commanded Engine Torque Response Type";
CM_ SG_ 276 HybCmndEngTorqPrdtd "Hybrid commanded engine torque predicted torque (slow path).";
CM_ SG_ 276 HybCmndEngTorqImmed "Hybrid commanded engine torque immediate torque (fast path)";
CM_ SG_ 276 EngTrqReserveCmd "Engine torque reserve command";
CM_ SG_ 276 EngCntrlMode "EngCntrlMode, [0] = Torque Mode, [1] = Speed Mode";
CM_ SG_ 276 ECMPrepIdleRes "ECM to prep for rolling idle reserve";
CM_ SG_ 276 CRC_HYBRID_POWERTRAIN1 "CRC according to SAE J1850 standard at each frame transmission.";
CM_ SG_ 276 PropulsionSystemActive "Propulsion system active, [1] = active";
CM_ SG_ 276 MessageCounter_HYBRID_POWER_0001 "This signal is a counter used for safety checks strategies. This counter is incremented of 1 (one) unit at each frame transmission.";
CM_ SG_ 271 Sum_FW_ID_Slw "Enumeration of system controlling combustion slow path";
CM_ SG_ 271 Sum_FW_ID_Fst "Enumeration of system controlling combustion fast path";
CM_ SG_ 271 MinPrdtdEngRunTorqCapV "Minimum predicted engine run torque capacity validity; Invalid = [1]";
CM_ SG_ 271 MinPrdtdEngRunTorqCap "Minimum predicted engine run torque capacity (minimum air flow, MBT spark)";
CM_ SG_ 271 MinImmedEngTorqCapV "Minimum immediate engine torque capacity validity; Invalid = [1]";
CM_ SG_ 271 MinImmedEngTorqCap "Minimum immediate engine torque capacity (current air flow, minimum spark)";
CM_ SG_ 271 MinEngTorqCapV "Minimum engine torque capacity validity; Invalid = [1]";
CM_ SG_ 271 MinEngTorqCap "Minimum engine torque capacity (min air flow, fuel off)";
CM_ SG_ 271 MinAirFlowMinSparkTorqCapV "Engine Torque capacity at minimum air flow and  minimum spark validity; Invalid = [1]";
CM_ SG_ 271 MinAirFlowMinSparkTorqCap "Engine Torque capacity at minimum air flow and  minimum spark";
CM_ SG_ 271 MessageCounter_ENGINE_HYBD_FD_1 "This signal is a counter used for safety checks strategies. This counter is incremented of 1 (one) unit at each frame transmission.";
CM_ SG_ 271 MaxPrdtdEngTorqCapV "Maximum predicted engine torque capacity validity; Invalid = [1]";
CM_ SG_ 271 MaxPrdtdEngTorqCap "Maximum predicted engine torque capacity";
CM_ SG_ 271 MaxOffEngTorqCap "Capacity Max-off";
CM_ SG_ 271 HybActEngTorqRespTyp "Hybrid Actual Engine Torque Response Type";
CM_ SG_ 271 Feedback_HCP "Indication that the ECM is receiving valid data from the HCP. 0 - False; 1 - True.";
CM_ SG_ 271 ETRQ_Mode "Enumeration of combustion torque mode";
CM_ SG_ 271 EngTrqReserveReq "Engine Torque Reserve Request";
CM_ SG_ 271 EngRunCrnkAct "ECM run crank terminal status, 1=active";
CM_ SG_ 271 EngAirFlwStdyStTorqV "Engine airflow steady state torque validity; Invalid = [1]";
CM_ SG_ 271 EngAirFlwStdyStTorq "Engine airflow steady state torque (potential)";
CM_ SG_ 271 EngActuatorsStat "Engine Actuator Status for Autostop";
CM_ SG_ 271 EngActStdyStTorqV "Engine actual steady state torque validity; Invalid = [1]";
CM_ SG_ 271 EngActStdyStTorq "Engine actual steady state torque (current conditions)";
CM_ SG_ 271 CRC_ENGINE_HYBD_FD_1 "CRC according to SAE J1850 standard at each frame transmission.";
CM_ SG_ 271 MAP_4_BAR_PHEV "Engine manifold pressure (4 bar range) 10ms cyclic";
CM_ SG_ 271 RedSpkAuthorityAvbl "Reduced Spark Availability Warning";
CM_ SG_ 271 EngMinSparkNomCurrAirTorqCap "Engine Torque capacity at current airflow  min and  nominal spark advance.";
CM_ SG_ 271 EngTrqFSO_CurrAir "Engine torque at current air at with all cylinders in fuel shut off";
BA_DEF_ BU_  "NwmNodeType" ENUM  "+15_NotWakeable","+30_Wakeable","+30_NotWakeable","kMaster","kSlave15","kSlave30","none";
BA_DEF_ BU_  "NmNodeType" ENUM  "+15_NotWakeable","+30_Wakeable","+30_NotWakeable","kMaster","kSlave15","kSlave30","none";
BA_DEF_ BU_  "NmAsrCanMsgReducedTime" INT 1 65535;
BA_DEF_ BU_  "NmAsrNodeIdentifier" HEX 0 255;
BA_DEF_ BU_  "NmAsrNode" ENUM  "No","Yes";
BA_DEF_ BU_  "NmNode" ENUM  "No","Yes";
BA_DEF_ BU_  "NmStationAddress" HEX 0 255;
BA_DEF_ BU_  "Description" STRING ;
BA_DEF_  "VersionYear" INT 0 99;
BA_DEF_  "VersionWeek" INT 0 53;
BA_DEF_  "Version" HEX 0 255;
BA_DEF_  "NmAsrCanMsgCycleTime" INT 1 65535;
BA_DEF_  "NmAsrBaseAddress" HEX 235487232 2147483647;
BA_DEF_  "NmAsrMessageCount" INT 1 256;
BA_DEF_  "NmAsrRepeatMessageTime" INT 1 65535;
BA_DEF_  "NmAsrWaitBusSleepTime" INT 1 65535;
BA_DEF_  "NmAsrTimeoutTime" INT 1 65535;
BA_DEF_  "DBName" STRING ;
BA_DEF_  "Baudrate" INT 0 1000000;
BA_DEF_  "BusType" STRING ;
BA_DEF_  "NmType" STRING ;
BA_DEF_  "Manufacturer" ENUM  "DBAG","VAG","BWVAG","PAG","GM";
BA_DEF_ BO_  "CANFD_BRS" ENUM  "0","1";
BA_DEF_ BO_  "VFrameFormat" ENUM  "StandardCAN","ExtendedCAN","reserved","reserved","reserved","reserved","reserved","reserved","reserved","reserved","reserved","reserved","reserved","reserved","StandardCAN_FD","ExtendedCAN_FD";
BA_DEF_ BO_  "DiagConnection" HEX 0 65535;
BA_DEF_ BO_  "DiagState" ENUM  "No","Yes";
BA_DEF_ BO_  "NmAsrMessage" ENUM  "No","Yes";
BA_DEF_ BO_  "GenMsgDelayTime" INT 0 65535;
BA_DEF_ BO_  "GenMsgCycleTime" INT 0 65535;
BA_DEF_ BO_  "GenMsgCycleTimeFast" INT 0 65535;
BA_DEF_ BO_  "GenMsgStartDelayTime" INT 0 65535;
BA_DEF_ BO_  "GenMsgILSupport" ENUM  "No","Yes";
BA_DEF_ BO_  "GenMsgNrOfRepetition" INT 0 255;
BA_DEF_ BO_  "GenMsgSendType" ENUM  "Cyclic","NotUsed","NotUsed","NotUsed","NotUsed","NotUsed","NotUsed","NotUsed","NoMsgSendType";
BA_DEF_ BO_  "NmMessage" ENUM  "No","Yes";
BA_DEF_ BO_  "DiagResponse" ENUM  "No","Yes";
BA_DEF_ BO_  "Type" ENUM  "P","C","PE","COC","PE_Cntrl","E","E_Cntrl","OC","S","BAF","DC","EM","MM","ISO-TP","-";
BA_DEF_ BO_  "DiagRequest" ENUM  "No","Yes";
BA_DEF_ SG_  "GenSigTimeoutTime_TCM" INT 0 65535;
BA_DEF_ SG_  "GenSigTimeoutTime_SGCP" INT 0 65535;
BA_DEF_ SG_  "GenSigTimeoutTime_MCPB" INT 0 65535;
BA_DEF_ SG_  "GenSigTimeoutTime_MCPA" INT 0 65535;
BA_DEF_ SG_  "GenSigTimeoutTime_EVCU2" INT 0 65535;
BA_DEF_ SG_  "GenSigTimeoutTime_ECM" INT 0 65535;
BA_DEF_ SG_  "GenSigTimeoutTime_AGSM" INT 0 65535;
BA_DEF_ SG_  "GenSigSendType" ENUM  "NotUsed","OnWrite","OnWriteWithRepetition","OnChange","OnChangeWithRepetition","IfActive","IfActiveWithRepetition","NoSigSendType";
BA_DEF_ SG_  "GenSigInactiveValue" INT 0 2147483647;
BA_DEF_ SG_  "GenSigStartValue" INT 0 2147483647;
BA_DEF_ SG_  "SystemSignalLongSymbol" STRING ;
BA_DEF_DEF_  "NwmNodeType" "none";
BA_DEF_DEF_  "NmNodeType" "none";
BA_DEF_DEF_  "NmAsrCanMsgReducedTime" 100;
BA_DEF_DEF_  "NmAsrNodeIdentifier" 0;
BA_DEF_DEF_  "NmAsrNode" "Yes";
BA_DEF_DEF_  "NmNode" "Yes";
BA_DEF_DEF_  "NmStationAddress" 0;
BA_DEF_DEF_  "Description" "";
BA_DEF_DEF_  "VersionYear" 23;
BA_DEF_DEF_  "VersionWeek" 17;
BA_DEF_DEF_  "Version" 160;
BA_DEF_DEF_  "NmAsrCanMsgCycleTime" 200;
BA_DEF_DEF_  "NmAsrBaseAddress" 506724352;
BA_DEF_DEF_  "NmAsrMessageCount" 256;
BA_DEF_DEF_  "NmAsrRepeatMessageTime" 800;
BA_DEF_DEF_  "NmAsrWaitBusSleepTime" 750;
BA_DEF_DEF_  "NmAsrTimeoutTime" 1000;
BA_DEF_DEF_  "DBName" "CAN";
BA_DEF_DEF_  "Baudrate" 500000;
BA_DEF_DEF_  "BusType" "CAN";
BA_DEF_DEF_  "NmType" "";
BA_DEF_DEF_  "Manufacturer" "DBAG";
BA_DEF_DEF_  "CANFD_BRS" "0";
BA_DEF_DEF_  "VFrameFormat" "StandardCAN_FD";
BA_DEF_DEF_  "DiagConnection" 0;
BA_DEF_DEF_  "DiagState" "No";
BA_DEF_DEF_  "NmAsrMessage" "No";
BA_DEF_DEF_  "GenMsgDelayTime" 0;
BA_DEF_DEF_  "GenMsgCycleTime" 0;
BA_DEF_DEF_  "GenMsgCycleTimeFast" 0;
BA_DEF_DEF_  "GenMsgStartDelayTime" 0;
BA_DEF_DEF_  "GenMsgILSupport" "No";
BA_DEF_DEF_  "GenMsgNrOfRepetition" 0;
BA_DEF_DEF_  "GenMsgSendType" "NoMsgSendType";
BA_DEF_DEF_  "NmMessage" "No";
BA_DEF_DEF_  "DiagResponse" "No";
BA_DEF_DEF_  "Type" "-";
BA_DEF_DEF_  "DiagRequest" "No";
BA_DEF_DEF_  "GenSigTimeoutTime_TCM" 2500;
BA_DEF_DEF_  "GenSigTimeoutTime_SGCP" 2500;
BA_DEF_DEF_  "GenSigTimeoutTime_MCPB" 2500;
BA_DEF_DEF_  "GenSigTimeoutTime_MCPA" 2500;
BA_DEF_DEF_  "GenSigTimeoutTime_EVCU2" 2500;
BA_DEF_DEF_  "GenSigTimeoutTime_ECM" 2500;
BA_DEF_DEF_  "GenSigTimeoutTime_AGSM" 2500;
BA_DEF_DEF_  "GenSigSendType" "NoSigSendType";
BA_DEF_DEF_  "GenSigInactiveValue" 0;
BA_DEF_DEF_  "GenSigStartValue" 0;
BA_DEF_DEF_  "SystemSignalLongSymbol" "";
BA_ "NmType" "NmAsr";
BA_ "NmAsrTimeoutTime" 8000;
BA_ "NmAsrWaitBusSleepTime" 1000;
BA_ "NmAsrRepeatMessageTime" 5000;
BA_ "NmAsrBaseAddress" 507002880;
BA_ "NmAsrCanMsgCycleTime" 1000;
BA_ "BusType" "CAN FD";
BA_ "DBName" "FDCAN16";
BA_ "Description" BU_ AGSM "Automatic Gearbox Shifter Module";
BA_ "NmStationAddress" BU_ AGSM 22;
BA_ "NmNode" BU_ AGSM 0;
BA_ "NmAsrNode" BU_ AGSM 0;
BA_ "NmAsrNodeIdentifier" BU_ AGSM 22;
BA_ "NmNodeType" BU_ AGSM 0;
BA_ "NwmNodeType" BU_ AGSM 0;
BA_ "Description" BU_ ECM "Engine Control Module";
BA_ "NmStationAddress" BU_ ECM 1;
BA_ "NmNode" BU_ ECM 0;
BA_ "NmAsrNode" BU_ ECM 0;
BA_ "NmAsrNodeIdentifier" BU_ ECM 1;
BA_ "NmNodeType" BU_ ECM 0;
BA_ "NwmNodeType" BU_ ECM 0;
BA_ "Description" BU_ EVCU2 "Electric Vehicle Control Unit 2";
BA_ "NmStationAddress" BU_ EVCU2 64;
BA_ "NmAsrNodeIdentifier" BU_ EVCU2 64;
BA_ "NmAsrCanMsgReducedTime" BU_ EVCU2 950;
BA_ "NmNodeType" BU_ EVCU2 1;
BA_ "NwmNodeType" BU_ EVCU2 1;
BA_ "Description" BU_ MCPA "Motor Control Processor A";
BA_ "NmStationAddress" BU_ MCPA 88;
BA_ "NmAsrNodeIdentifier" BU_ MCPA 88;
BA_ "NmAsrCanMsgReducedTime" BU_ MCPA 625;
BA_ "NmNodeType" BU_ MCPA 1;
BA_ "NwmNodeType" BU_ MCPA 1;
BA_ "Description" BU_ MCPB "Motor Control Processor B";
BA_ "NmStationAddress" BU_ MCPB 89;
BA_ "NmAsrNodeIdentifier" BU_ MCPB 89;
BA_ "NmAsrCanMsgReducedTime" BU_ MCPB 650;
BA_ "NmNodeType" BU_ MCPB 1;
BA_ "NwmNodeType" BU_ MCPB 1;
BA_ "Description" BU_ SGCP "Starter Generator Control Processor";
BA_ "NmStationAddress" BU_ SGCP 201;
BA_ "NmAsrNodeIdentifier" BU_ SGCP 201;
BA_ "NmAsrCanMsgReducedTime" BU_ SGCP 675;
BA_ "NmNodeType" BU_ SGCP 1;
BA_ "NwmNodeType" BU_ SGCP 1;
BA_ "Description" BU_ TCM "Transmission Control Module";
BA_ "NmStationAddress" BU_ TCM 11;
BA_ "NmNode" BU_ TCM 0;
BA_ "NmAsrNode" BU_ TCM 0;
BA_ "NmAsrNodeIdentifier" BU_ TCM 11;
BA_ "NmNodeType" BU_ TCM 0;
BA_ "NwmNodeType" BU_ TCM 0;
BA_ "GenMsgCycleTime" BO_ 125 100;
BA_ "VFrameFormat" BO_ 125 0;
BA_ "GenMsgCycleTime" BO_ 129 100;
BA_ "VFrameFormat" BO_ 129 0;
BA_ "GenMsgCycleTime" BO_ 126 100;
BA_ "VFrameFormat" BO_ 126 0;
BA_ "GenMsgCycleTime" BO_ 123 100;
BA_ "VFrameFormat" BO_ 123 0;
BA_ "GenMsgCycleTime" BO_ 127 100;
BA_ "VFrameFormat" BO_ 127 0;
BA_ "GenMsgCycleTime" BO_ 124 100;
BA_ "Type" BO_ 2651930624 8;
BA_ "GenMsgILSupport" BO_ 2651930624 1;
BA_ "GenMsgDelayTime" BO_ 2651930624 10;
BA_ "CANFD_BRS" BO_ 2651930624 1;
BA_ "VFrameFormat" BO_ 2651930624 15;
BA_ "Type" BO_ 2564502513 8;
BA_ "DiagState" BO_ 2564502513 1;
BA_ "DiagConnection" BO_ 2564502513 61747;
BA_ "VFrameFormat" BO_ 2564502513 1;
BA_ "Type" BO_ 1450 3;
BA_ "GenMsgSendType" BO_ 1450 0;
BA_ "GenMsgNrOfRepetition" BO_ 1450 2;
BA_ "GenMsgILSupport" BO_ 1450 1;
BA_ "GenMsgCycleTimeFast" BO_ 1450 20;
BA_ "GenMsgCycleTime" BO_ 1450 1000;
BA_ "GenMsgDelayTime" BO_ 1450 20;
BA_ "CANFD_BRS" BO_ 1450 1;
BA_ "Type" BO_ 520 1;
BA_ "GenMsgSendType" BO_ 520 0;
BA_ "GenMsgILSupport" BO_ 520 1;
BA_ "GenMsgCycleTime" BO_ 520 20;
BA_ "CANFD_BRS" BO_ 520 1;
BA_ "Type" BO_ 156 8;
BA_ "GenMsgILSupport" BO_ 156 1;
BA_ "CANFD_BRS" BO_ 156 1;
BA_ "Type" BO_ 1058 1;
BA_ "GenMsgSendType" BO_ 1058 0;
BA_ "GenMsgILSupport" BO_ 1058 1;
BA_ "GenMsgCycleTime" BO_ 1058 100;
BA_ "CANFD_BRS" BO_ 1058 1;
BA_ "Type" BO_ 1626 10;
BA_ "GenMsgSendType" BO_ 1626 0;
BA_ "GenMsgILSupport" BO_ 1626 1;
BA_ "GenMsgCycleTimeFast" BO_ 1626 10;
BA_ "GenMsgCycleTime" BO_ 1626 500;
BA_ "CANFD_BRS" BO_ 1626 1;
BA_ "Type" BO_ 1055 1;
BA_ "GenMsgSendType" BO_ 1055 0;
BA_ "GenMsgILSupport" BO_ 1055 1;
BA_ "GenMsgCycleTime" BO_ 1055 100;
BA_ "CANFD_BRS" BO_ 1055 1;
BA_ "Type" BO_ 1448 3;
BA_ "GenMsgSendType" BO_ 1448 0;
BA_ "GenMsgNrOfRepetition" BO_ 1448 2;
BA_ "GenMsgILSupport" BO_ 1448 1;
BA_ "GenMsgCycleTimeFast" BO_ 1448 20;
BA_ "GenMsgCycleTime" BO_ 1448 1000;
BA_ "GenMsgDelayTime" BO_ 1448 20;
BA_ "CANFD_BRS" BO_ 1448 1;
BA_ "Type" BO_ 751 1;
BA_ "GenMsgSendType" BO_ 751 0;
BA_ "GenMsgILSupport" BO_ 751 1;
BA_ "GenMsgCycleTime" BO_ 751 50;
BA_ "CANFD_BRS" BO_ 751 1;
BA_ "Type" BO_ 518 1;
BA_ "GenMsgSendType" BO_ 518 0;
BA_ "GenMsgILSupport" BO_ 518 1;
BA_ "GenMsgCycleTime" BO_ 518 20;
BA_ "CANFD_BRS" BO_ 518 1;
BA_ "Type" BO_ 1054 1;
BA_ "GenMsgSendType" BO_ 1054 0;
BA_ "GenMsgILSupport" BO_ 1054 1;
BA_ "GenMsgCycleTime" BO_ 1054 100;
BA_ "CANFD_BRS" BO_ 1054 1;
BA_ "Type" BO_ 2654817816 8;
BA_ "CANFD_BRS" BO_ 2654817816 1;
BA_ "VFrameFormat" BO_ 2654817816 15;
BA_ "Type" BO_ 2564554482 8;
BA_ "DiagState" BO_ 2564554482 1;
BA_ "DiagConnection" BO_ 2564554482 62206;
BA_ "CANFD_BRS" BO_ 2564554482 1;
BA_ "VFrameFormat" BO_ 2564554482 15;
BA_ "Type" BO_ 1155 3;
BA_ "GenMsgSendType" BO_ 1155 0;
BA_ "GenMsgNrOfRepetition" BO_ 1155 2;
BA_ "GenMsgILSupport" BO_ 1155 1;
BA_ "GenMsgCycleTimeFast" BO_ 1155 20;
BA_ "GenMsgCycleTime" BO_ 1155 500;
BA_ "GenMsgDelayTime" BO_ 1155 20;
BA_ "CANFD_BRS" BO_ 1155 1;
BA_ "Type" BO_ 609 3;
BA_ "GenMsgSendType" BO_ 609 0;
BA_ "GenMsgNrOfRepetition" BO_ 609 2;
BA_ "GenMsgILSupport" BO_ 609 1;
BA_ "GenMsgStartDelayTime" BO_ 609 50;
BA_ "GenMsgCycleTimeFast" BO_ 609 20;
BA_ "GenMsgCycleTime" BO_ 609 100;
BA_ "CANFD_BRS" BO_ 609 1;
BA_ "Type" BO_ 1066 3;
BA_ "GenMsgSendType" BO_ 1066 0;
BA_ "GenMsgNrOfRepetition" BO_ 1066 2;
BA_ "GenMsgILSupport" BO_ 1066 1;
BA_ "GenMsgCycleTimeFast" BO_ 1066 20;
BA_ "GenMsgCycleTime" BO_ 1066 250;
BA_ "GenMsgDelayTime" BO_ 1066 20;
BA_ "CANFD_BRS" BO_ 1066 1;
BA_ "Type" BO_ 1153 3;
BA_ "GenMsgSendType" BO_ 1153 0;
BA_ "GenMsgNrOfRepetition" BO_ 1153 2;
BA_ "GenMsgILSupport" BO_ 1153 1;
BA_ "GenMsgCycleTimeFast" BO_ 1153 20;
BA_ "GenMsgCycleTime" BO_ 1153 500;
BA_ "GenMsgDelayTime" BO_ 1153 20;
BA_ "CANFD_BRS" BO_ 1153 1;
BA_ "Type" BO_ 255 1;
BA_ "GenMsgSendType" BO_ 255 0;
BA_ "GenMsgILSupport" BO_ 255 1;
BA_ "GenMsgCycleTime" BO_ 255 10;
BA_ "CANFD_BRS" BO_ 255 1;
BA_ "Type" BO_ 1032 1;
BA_ "GenMsgSendType" BO_ 1032 0;
BA_ "GenMsgILSupport" BO_ 1032 1;
BA_ "GenMsgCycleTime" BO_ 1032 100;
BA_ "CANFD_BRS" BO_ 1032 1;
BA_ "Type" BO_ 267 1;
BA_ "GenMsgSendType" BO_ 267 0;
BA_ "GenMsgILSupport" BO_ 267 1;
BA_ "GenMsgCycleTime" BO_ 267 10;
BA_ "CANFD_BRS" BO_ 267 1;
BA_ "Type" BO_ 1033 1;
BA_ "GenMsgSendType" BO_ 1033 0;
BA_ "GenMsgILSupport" BO_ 1033 1;
BA_ "GenMsgCycleTime" BO_ 1033 100;
BA_ "CANFD_BRS" BO_ 1033 1;
BA_ "Type" BO_ 1328 1;
BA_ "GenMsgSendType" BO_ 1328 0;
BA_ "GenMsgILSupport" BO_ 1328 1;
BA_ "GenMsgCycleTime" BO_ 1328 200;
BA_ "CANFD_BRS" BO_ 1328 1;
BA_ "Type" BO_ 1035 1;
BA_ "GenMsgSendType" BO_ 1035 0;
BA_ "GenMsgILSupport" BO_ 1035 1;
BA_ "GenMsgCycleTime" BO_ 1035 100;
BA_ "CANFD_BRS" BO_ 1035 1;
BA_ "Type" BO_ 1036 3;
BA_ "GenMsgSendType" BO_ 1036 0;
BA_ "GenMsgNrOfRepetition" BO_ 1036 2;
BA_ "GenMsgILSupport" BO_ 1036 1;
BA_ "GenMsgCycleTimeFast" BO_ 1036 20;
BA_ "GenMsgCycleTime" BO_ 1036 100;
BA_ "GenMsgDelayTime" BO_ 1036 20;
BA_ "CANFD_BRS" BO_ 1036 1;
BA_ "Type" BO_ 278 1;
BA_ "GenMsgSendType" BO_ 278 0;
BA_ "GenMsgILSupport" BO_ 278 1;
BA_ "GenMsgCycleTime" BO_ 278 10;
BA_ "CANFD_BRS" BO_ 278 1;
BA_ "Type" BO_ 269 1;
BA_ "GenMsgSendType" BO_ 269 0;
BA_ "GenMsgILSupport" BO_ 269 1;
BA_ "GenMsgCycleTime" BO_ 269 10;
BA_ "CANFD_BRS" BO_ 269 1;
BA_ "Type" BO_ 276 1;
BA_ "GenMsgSendType" BO_ 276 0;
BA_ "GenMsgILSupport" BO_ 276 1;
BA_ "GenMsgCycleTime" BO_ 276 10;
BA_ "CANFD_BRS" BO_ 276 1;
BA_ "Type" BO_ 271 1;
BA_ "GenMsgSendType" BO_ 271 0;
BA_ "GenMsgILSupport" BO_ 271 1;
BA_ "GenMsgCycleTime" BO_ 271 10;
BA_ "CANFD_BRS" BO_ 271 1;
BA_ "GenSigTimeoutTime_AGSM" SG_ 2651930624 Digit_11 0;
BA_ "GenSigTimeoutTime_ECM" SG_ 2651930624 Digit_11 0;
BA_ "GenSigTimeoutTime_EVCU2" SG_ 2651930624 Digit_11 0;
BA_ "GenSigTimeoutTime_TCM" SG_ 2651930624 Digit_11 0;
BA_ "GenSigTimeoutTime_AGSM" SG_ 2651930624 Digit_10 0;
BA_ "GenSigTimeoutTime_ECM" SG_ 2651930624 Digit_10 0;
BA_ "GenSigTimeoutTime_EVCU2" SG_ 2651930624 Digit_10 0;
BA_ "GenSigTimeoutTime_TCM" SG_ 2651930624 Digit_10 0;
BA_ "GenSigTimeoutTime_AGSM" SG_ 2651930624 Digit_09 0;
BA_ "GenSigTimeoutTime_ECM" SG_ 2651930624 Digit_09 0;
BA_ "GenSigTimeoutTime_EVCU2" SG_ 2651930624 Digit_09 0;
BA_ "GenSigTimeoutTime_TCM" SG_ 2651930624 Digit_09 0;
BA_ "GenSigTimeoutTime_AGSM" SG_ 2651930624 Digit_08 0;
BA_ "GenSigTimeoutTime_ECM" SG_ 2651930624 Digit_08 0;
BA_ "GenSigTimeoutTime_EVCU2" SG_ 2651930624 Digit_08 0;
BA_ "GenSigTimeoutTime_TCM" SG_ 2651930624 Digit_08 0;
BA_ "GenSigTimeoutTime_AGSM" SG_ 2651930624 Digit_07 0;
BA_ "GenSigTimeoutTime_ECM" SG_ 2651930624 Digit_07 0;
BA_ "GenSigTimeoutTime_EVCU2" SG_ 2651930624 Digit_07 0;
BA_ "GenSigTimeoutTime_TCM" SG_ 2651930624 Digit_07 0;
BA_ "GenSigTimeoutTime_AGSM" SG_ 2651930624 Digit_06 0;
BA_ "GenSigTimeoutTime_ECM" SG_ 2651930624 Digit_06 0;
BA_ "GenSigTimeoutTime_EVCU2" SG_ 2651930624 Digit_06 0;
BA_ "GenSigTimeoutTime_TCM" SG_ 2651930624 Digit_06 0;
BA_ "GenSigTimeoutTime_AGSM" SG_ 2651930624 Digit_05 0;
BA_ "GenSigTimeoutTime_ECM" SG_ 2651930624 Digit_05 0;
BA_ "GenSigTimeoutTime_EVCU2" SG_ 2651930624 Digit_05 0;
BA_ "GenSigTimeoutTime_TCM" SG_ 2651930624 Digit_05 0;
BA_ "GenSigTimeoutTime_AGSM" SG_ 2651930624 Digit_04 0;
BA_ "GenSigTimeoutTime_ECM" SG_ 2651930624 Digit_04 0;
BA_ "GenSigTimeoutTime_EVCU2" SG_ 2651930624 Digit_04 0;
BA_ "GenSigTimeoutTime_TCM" SG_ 2651930624 Digit_04 0;
BA_ "GenSigTimeoutTime_AGSM" SG_ 2651930624 Digit_03 0;
BA_ "GenSigTimeoutTime_ECM" SG_ 2651930624 Digit_03 0;
BA_ "GenSigTimeoutTime_EVCU2" SG_ 2651930624 Digit_03 0;
BA_ "GenSigTimeoutTime_TCM" SG_ 2651930624 Digit_03 0;
BA_ "GenSigTimeoutTime_AGSM" SG_ 2651930624 Digit_02 0;
BA_ "GenSigTimeoutTime_ECM" SG_ 2651930624 Digit_02 0;
BA_ "GenSigTimeoutTime_EVCU2" SG_ 2651930624 Digit_02 0;
BA_ "GenSigTimeoutTime_TCM" SG_ 2651930624 Digit_02 0;
BA_ "GenSigTimeoutTime_AGSM" SG_ 2651930624 Digit_01 0;
BA_ "GenSigTimeoutTime_ECM" SG_ 2651930624 Digit_01 0;
BA_ "GenSigTimeoutTime_EVCU2" SG_ 2651930624 Digit_01 0;
BA_ "GenSigTimeoutTime_TCM" SG_ 2651930624 Digit_01 0;
BA_ "GenSigTimeoutTime_AGSM" SG_ 2564502513 N_PDU_18DB33F1 0;
BA_ "GenSigTimeoutTime_ECM" SG_ 2564502513 N_PDU_18DB33F1 0;
BA_ "GenSigTimeoutTime_EVCU2" SG_ 2564502513 N_PDU_18DB33F1 0;
BA_ "GenSigTimeoutTime_MCPA" SG_ 2564502513 N_PDU_18DB33F1 0;
BA_ "GenSigTimeoutTime_MCPB" SG_ 2564502513 N_PDU_18DB33F1 0;
BA_ "GenSigTimeoutTime_SGCP" SG_ 2564502513 N_PDU_18DB33F1 0;
BA_ "GenSigSendType" SG_ 1450 TxDisengaged 3;
BA_ "GenSigTimeoutTime_AGSM" SG_ 1450 TxDisengaged 0;
BA_ "GenSigTimeoutTime_EVCU2" SG_ 1450 TxDisengaged 0;
BA_ "GenSigTimeoutTime_MCPA" SG_ 1450 TxDisengaged 0;
BA_ "GenSigTimeoutTime_MCPB" SG_ 1450 TxDisengaged 0;
BA_ "GenSigTimeoutTime_SGCP" SG_ 1450 TxDisengaged 0;
BA_ "GenSigTimeoutTime_TCM" SG_ 1450 TxDisengaged 0;
BA_ "GenSigSendType" SG_ 1450 TransmissionFailSts 3;
BA_ "GenSigTimeoutTime_ECM" SG_ 1450 TransmissionFailSts 0;
BA_ "GenSigTimeoutTime_EVCU2" SG_ 1450 TransmissionFailSts 0;
BA_ "GenSigTimeoutTime_MCPA" SG_ 1450 TransmissionFailSts 0;
BA_ "GenSigTimeoutTime_MCPB" SG_ 1450 TransmissionFailSts 0;
BA_ "GenSigTimeoutTime_SGCP" SG_ 1450 TransmissionFailSts 0;
BA_ "GenSigTimeoutTime_TCM" SG_ 1450 TransmissionFailSts 0;
BA_ "GenSigTimeoutTime_ECM" SG_ 1450 ShiftLeverPosition 0;
BA_ "GenSigSendType" SG_ 1450 ShiftLeverPosition 3;
BA_ "GenSigTimeoutTime_EVCU2" SG_ 1450 ShiftLeverPosition 0;
BA_ "GenSigTimeoutTime_MCPA" SG_ 1450 ShiftLeverPosition 0;
BA_ "GenSigTimeoutTime_MCPB" SG_ 1450 ShiftLeverPosition 0;
BA_ "GenSigTimeoutTime_SGCP" SG_ 1450 ShiftLeverPosition 0;
BA_ "GenSigTimeoutTime_TCM" SG_ 1450 ShiftLeverPosition 0;
BA_ "GenSigSendType" SG_ 1450 ShiftLeverLockReq 3;
BA_ "GenSigTimeoutTime_ECM" SG_ 1450 ShiftLeverLockReq 0;
BA_ "GenSigTimeoutTime_EVCU2" SG_ 1450 ShiftLeverLockReq 0;
BA_ "GenSigTimeoutTime_MCPA" SG_ 1450 ShiftLeverLockReq 0;
BA_ "GenSigTimeoutTime_MCPB" SG_ 1450 ShiftLeverLockReq 0;
BA_ "GenSigTimeoutTime_SGCP" SG_ 1450 ShiftLeverLockReq 0;
BA_ "GenSigTimeoutTime_TCM" SG_ 1450 ShiftLeverLockReq 0;
BA_ "GenSigSendType" SG_ 1450 ShiftInProgress 3;
BA_ "GenSigTimeoutTime_AGSM" SG_ 1450 ShiftInProgress 0;
BA_ "GenSigTimeoutTime_EVCU2" SG_ 1450 ShiftInProgress 0;
BA_ "GenSigTimeoutTime_MCPA" SG_ 1450 ShiftInProgress 0;
BA_ "GenSigTimeoutTime_MCPB" SG_ 1450 ShiftInProgress 0;
BA_ "GenSigTimeoutTime_SGCP" SG_ 1450 ShiftInProgress 0;
BA_ "GenSigTimeoutTime_TCM" SG_ 1450 ShiftInProgress 0;
BA_ "GenSigSendType" SG_ 1450 MIReq 3;
BA_ "GenSigTimeoutTime_AGSM" SG_ 1450 MIReq 0;
BA_ "GenSigTimeoutTime_EVCU2" SG_ 1450 MIReq 0;
BA_ "GenSigTimeoutTime_MCPA" SG_ 1450 MIReq 0;
BA_ "GenSigTimeoutTime_MCPB" SG_ 1450 MIReq 0;
BA_ "GenSigTimeoutTime_SGCP" SG_ 1450 MIReq 0;
BA_ "GenSigTimeoutTime_TCM" SG_ 1450 MIReq 0;
BA_ "GenSigSendType" SG_ 1450 LimpHomeSts 3;
BA_ "GenSigTimeoutTime_AGSM" SG_ 1450 LimpHomeSts 0;
BA_ "GenSigTimeoutTime_EVCU2" SG_ 1450 LimpHomeSts 0;
BA_ "GenSigTimeoutTime_MCPA" SG_ 1450 LimpHomeSts 0;
BA_ "GenSigTimeoutTime_MCPB" SG_ 1450 LimpHomeSts 0;
BA_ "GenSigTimeoutTime_SGCP" SG_ 1450 LimpHomeSts 0;
BA_ "GenSigTimeoutTime_TCM" SG_ 1450 LimpHomeSts 0;
BA_ "GenSigSendType" SG_ 1450 GearIndicationSts 3;
BA_ "GenSigTimeoutTime_ECM" SG_ 1450 GearIndicationSts 0;
BA_ "GenSigTimeoutTime_EVCU2" SG_ 1450 GearIndicationSts 0;
BA_ "GenSigTimeoutTime_MCPA" SG_ 1450 GearIndicationSts 0;
BA_ "GenSigTimeoutTime_MCPB" SG_ 1450 GearIndicationSts 0;
BA_ "GenSigTimeoutTime_SGCP" SG_ 1450 GearIndicationSts 0;
BA_ "GenSigTimeoutTime_TCM" SG_ 1450 GearIndicationSts 0;
BA_ "GenSigSendType" SG_ 1450 GearEngaged 3;
BA_ "GenSigTimeoutTime_AGSM" SG_ 1450 GearEngaged 0;
BA_ "GenSigTimeoutTime_EVCU2" SG_ 1450 GearEngaged 0;
BA_ "GenSigTimeoutTime_MCPA" SG_ 1450 GearEngaged 0;
BA_ "GenSigTimeoutTime_MCPB" SG_ 1450 GearEngaged 0;
BA_ "GenSigTimeoutTime_SGCP" SG_ 1450 GearEngaged 0;
BA_ "GenSigTimeoutTime_TCM" SG_ 1450 GearEngaged 0;
BA_ "GenSigSendType" SG_ 1450 CrankEnable 3;
BA_ "GenSigTimeoutTime_AGSM" SG_ 1450 CrankEnable 0;
BA_ "GenSigTimeoutTime_ECM" SG_ 1450 CrankEnable 0;
BA_ "GenSigTimeoutTime_EVCU2" SG_ 1450 CrankEnable 0;
BA_ "GenSigTimeoutTime_MCPA" SG_ 1450 CrankEnable 0;
BA_ "GenSigTimeoutTime_MCPB" SG_ 1450 CrankEnable 0;
BA_ "GenSigTimeoutTime_SGCP" SG_ 1450 CrankEnable 0;
BA_ "GenSigTimeoutTime_TCM" SG_ 1450 CrankEnable 0;
BA_ "GenSigSendType" SG_ 1450 ShiftMapNotAchieved 3;
BA_ "GenSigTimeoutTime_AGSM" SG_ 1450 ShiftMapNotAchieved 0;
BA_ "GenSigTimeoutTime_ECM" SG_ 1450 ShiftMapNotAchieved 0;
BA_ "GenSigTimeoutTime_EVCU2" SG_ 1450 ShiftMapNotAchieved 0;
BA_ "GenSigTimeoutTime_MCPA" SG_ 1450 ShiftMapNotAchieved 0;
BA_ "GenSigTimeoutTime_MCPB" SG_ 1450 ShiftMapNotAchieved 0;
BA_ "GenSigTimeoutTime_SGCP" SG_ 1450 ShiftMapNotAchieved 0;
BA_ "GenSigTimeoutTime_TCM" SG_ 1450 ShiftMapNotAchieved 0;
BA_ "GenSigSendType" SG_ 1450 R_SHFT_LOCK 3;
BA_ "GenSigTimeoutTime_ECM" SG_ 1450 R_SHFT_LOCK 0;
BA_ "GenSigTimeoutTime_EVCU2" SG_ 1450 R_SHFT_LOCK 0;
BA_ "GenSigTimeoutTime_MCPA" SG_ 1450 R_SHFT_LOCK 0;
BA_ "GenSigTimeoutTime_MCPB" SG_ 1450 R_SHFT_LOCK 0;
BA_ "GenSigTimeoutTime_SGCP" SG_ 1450 R_SHFT_LOCK 0;
BA_ "GenSigTimeoutTime_TCM" SG_ 1450 R_SHFT_LOCK 0;
BA_ "GenSigTimeoutTime_ECM" SG_ 1450 MessageCounter_TRANSM4 0;
BA_ "GenSigTimeoutTime_EVCU2" SG_ 1450 MessageCounter_TRANSM4 0;
BA_ "GenSigTimeoutTime_MCPA" SG_ 1450 MessageCounter_TRANSM4 0;
BA_ "GenSigTimeoutTime_MCPB" SG_ 1450 MessageCounter_TRANSM4 0;
BA_ "GenSigTimeoutTime_SGCP" SG_ 1450 MessageCounter_TRANSM4 0;
BA_ "GenSigTimeoutTime_TCM" SG_ 1450 MessageCounter_TRANSM4 0;
BA_ "GenSigTimeoutTime_ECM" SG_ 1450 CRC_TRANSM4 0;
BA_ "GenSigTimeoutTime_EVCU2" SG_ 1450 CRC_TRANSM4 0;
BA_ "GenSigTimeoutTime_MCPA" SG_ 1450 CRC_TRANSM4 0;
BA_ "GenSigTimeoutTime_MCPB" SG_ 1450 CRC_TRANSM4 0;
BA_ "GenSigTimeoutTime_SGCP" SG_ 1450 CRC_TRANSM4 0;
BA_ "GenSigTimeoutTime_TCM" SG_ 1450 CRC_TRANSM4 0;
BA_ "GenSigSendType" SG_ 1450 DriveModeSts 3;
BA_ "GenSigTimeoutTime_AGSM" SG_ 1450 DriveModeSts 0;
BA_ "GenSigTimeoutTime_EVCU2" SG_ 1450 DriveModeSts 0;
BA_ "GenSigTimeoutTime_MCPA" SG_ 1450 DriveModeSts 0;
BA_ "GenSigTimeoutTime_MCPB" SG_ 1450 DriveModeSts 0;
BA_ "GenSigTimeoutTime_SGCP" SG_ 1450 DriveModeSts 0;
BA_ "GenSigTimeoutTime_TCM" SG_ 1450 DriveModeSts 0;
BA_ "GenSigSendType" SG_ 1450 TxDisengaged_Fault 3;
BA_ "GenSigTimeoutTime_AGSM" SG_ 1450 TxDisengaged_Fault 0;
BA_ "GenSigTimeoutTime_EVCU2" SG_ 1450 TxDisengaged_Fault 0;
BA_ "GenSigTimeoutTime_MCPA" SG_ 1450 TxDisengaged_Fault 0;
BA_ "GenSigTimeoutTime_MCPB" SG_ 1450 TxDisengaged_Fault 0;
BA_ "GenSigTimeoutTime_SGCP" SG_ 1450 TxDisengaged_Fault 0;
BA_ "GenSigTimeoutTime_TCM" SG_ 1450 TxDisengaged_Fault 0;
BA_ "GenSigTimeoutTime_MCPB" SG_ 1450 Lowmode_Indication_Sts 0;
BA_ "GenSigTimeoutTime_TCM" SG_ 1450 Lowmode_Indication_Sts 0;
BA_ "GenSigSendType" SG_ 1450 Lowmode_Indication_Sts 3;
BA_ "GenSigTimeoutTime_ECM" SG_ 1450 Lowmode_Indication_Sts 0;
BA_ "GenSigTimeoutTime_EVCU2" SG_ 1450 Lowmode_Indication_Sts 0;
BA_ "GenSigTimeoutTime_MCPA" SG_ 1450 Lowmode_Indication_Sts 0;
BA_ "GenSigSendType" SG_ 1450 Low_Mode_Sts 3;
BA_ "GenSigTimeoutTime_ECM" SG_ 1450 Low_Mode_Sts 0;
BA_ "GenSigTimeoutTime_EVCU2" SG_ 1450 Low_Mode_Sts 0;
BA_ "GenSigTimeoutTime_MCPA" SG_ 1450 Low_Mode_Sts 0;
BA_ "GenSigTimeoutTime_MCPB" SG_ 1450 Low_Mode_Sts 0;
BA_ "GenSigTimeoutTime_TCM" SG_ 1450 Low_Mode_Sts 0;
BA_ "GenSigStartValue" SG_ 520 TurbineSpeed 65535;
BA_ "GenSigTimeoutTime_AGSM" SG_ 520 TurbineSpeed 0;
BA_ "GenSigTimeoutTime_EVCU2" SG_ 520 TurbineSpeed 0;
BA_ "GenSigTimeoutTime_MCPA" SG_ 520 TurbineSpeed 0;
BA_ "GenSigTimeoutTime_MCPB" SG_ 520 TurbineSpeed 0;
BA_ "GenSigTimeoutTime_SGCP" SG_ 520 TurbineSpeed 0;
BA_ "GenSigTimeoutTime_TCM" SG_ 520 TurbineSpeed 0;
BA_ "GenSigStartValue" SG_ 520 TRNS_StpSt_FLT 1;
BA_ "GenSigTimeoutTime_AGSM" SG_ 520 TRNS_StpSt_FLT 0;
BA_ "GenSigTimeoutTime_EVCU2" SG_ 520 TRNS_StpSt_FLT 0;
BA_ "GenSigTimeoutTime_MCPA" SG_ 520 TRNS_StpSt_FLT 0;
BA_ "GenSigTimeoutTime_MCPB" SG_ 520 TRNS_StpSt_FLT 0;
BA_ "GenSigTimeoutTime_SGCP" SG_ 520 TRNS_StpSt_FLT 0;
BA_ "GenSigTimeoutTime_TCM" SG_ 520 TRNS_StpSt_FLT 0;
BA_ "GenSigTimeoutTime_AGSM" SG_ 520 Trns_EMCC_Achvd 0;
BA_ "GenSigTimeoutTime_ECM" SG_ 520 Trns_EMCC_Achvd 0;
BA_ "GenSigTimeoutTime_EVCU2" SG_ 520 Trns_EMCC_Achvd 0;
BA_ "GenSigTimeoutTime_MCPA" SG_ 520 Trns_EMCC_Achvd 0;
BA_ "GenSigTimeoutTime_MCPB" SG_ 520 Trns_EMCC_Achvd 0;
BA_ "GenSigTimeoutTime_SGCP" SG_ 520 Trns_EMCC_Achvd 0;
BA_ "GenSigTimeoutTime_TCM" SG_ 520 Trns_EMCC_Achvd 0;
BA_ "GenSigTimeoutTime_AGSM" SG_ 520 TransReadyForESS 0;
BA_ "GenSigTimeoutTime_EVCU2" SG_ 520 TransReadyForESS 0;
BA_ "GenSigTimeoutTime_MCPA" SG_ 520 TransReadyForESS 0;
BA_ "GenSigTimeoutTime_MCPB" SG_ 520 TransReadyForESS 0;
BA_ "GenSigTimeoutTime_SGCP" SG_ 520 TransReadyForESS 0;
BA_ "GenSigTimeoutTime_TCM" SG_ 520 TransReadyForESS 0;
BA_ "GenSigTimeoutTime_AGSM" SG_ 520 TransmissionTemperature 0;
BA_ "GenSigTimeoutTime_EVCU2" SG_ 520 TransmissionTemperature 0;
BA_ "GenSigTimeoutTime_MCPA" SG_ 520 TransmissionTemperature 0;
BA_ "GenSigTimeoutTime_MCPB" SG_ 520 TransmissionTemperature 0;
BA_ "GenSigTimeoutTime_SGCP" SG_ 520 TransmissionTemperature 0;
BA_ "GenSigTimeoutTime_TCM" SG_ 520 TransmissionTemperature 0;
BA_ "GenSigStartValue" SG_ 520 OUTPUT_SPEED 65535;
BA_ "GenSigTimeoutTime_AGSM" SG_ 520 OUTPUT_SPEED 0;
BA_ "GenSigTimeoutTime_EVCU2" SG_ 520 OUTPUT_SPEED 0;
BA_ "GenSigTimeoutTime_MCPA" SG_ 520 OUTPUT_SPEED 0;
BA_ "GenSigTimeoutTime_MCPB" SG_ 520 OUTPUT_SPEED 0;
BA_ "GenSigTimeoutTime_SGCP" SG_ 520 OUTPUT_SPEED 0;
BA_ "GenSigTimeoutTime_TCM" SG_ 520 OUTPUT_SPEED 0;
BA_ "GenSigTimeoutTime_EVCU2" SG_ 520 APCM_Rq 0;
BA_ "GenSigTimeoutTime_MCPA" SG_ 520 APCM_Rq 0;
BA_ "GenSigTimeoutTime_MCPB" SG_ 520 APCM_Rq 0;
BA_ "GenSigTimeoutTime_SGCP" SG_ 520 APCM_Rq 0;
BA_ "GenSigTimeoutTime_TCM" SG_ 520 APCM_Rq 0;
BA_ "GenSigTimeoutTime_ECM" SG_ 520 MessageCounter_TRANSM2 0;
BA_ "GenSigTimeoutTime_EVCU2" SG_ 520 MessageCounter_TRANSM2 0;
BA_ "GenSigTimeoutTime_MCPA" SG_ 520 MessageCounter_TRANSM2 0;
BA_ "GenSigTimeoutTime_MCPB" SG_ 520 MessageCounter_TRANSM2 0;
BA_ "GenSigTimeoutTime_SGCP" SG_ 520 MessageCounter_TRANSM2 0;
BA_ "GenSigTimeoutTime_TCM" SG_ 520 MessageCounter_TRANSM2 0;
BA_ "GenSigTimeoutTime_AGSM" SG_ 520 EngShutOffRq_TCM 0;
BA_ "GenSigTimeoutTime_EVCU2" SG_ 520 EngShutOffRq_TCM 0;
BA_ "GenSigTimeoutTime_MCPA" SG_ 520 EngShutOffRq_TCM 0;
BA_ "GenSigTimeoutTime_MCPB" SG_ 520 EngShutOffRq_TCM 0;
BA_ "GenSigTimeoutTime_SGCP" SG_ 520 EngShutOffRq_TCM 0;
BA_ "GenSigTimeoutTime_TCM" SG_ 520 EngShutOffRq_TCM 0;
BA_ "GenSigTimeoutTime_ECM" SG_ 520 CRC_TRANSM2 0;
BA_ "GenSigTimeoutTime_EVCU2" SG_ 520 CRC_TRANSM2 0;
BA_ "GenSigTimeoutTime_MCPA" SG_ 520 CRC_TRANSM2 0;
BA_ "GenSigTimeoutTime_MCPB" SG_ 520 CRC_TRANSM2 0;
BA_ "GenSigTimeoutTime_SGCP" SG_ 520 CRC_TRANSM2 0;
BA_ "GenSigTimeoutTime_TCM" SG_ 520 CRC_TRANSM2 0;
BA_ "GenSigTimeoutTime_AGSM" SG_ 520 Trans_ESS_Inhibit 0;
BA_ "GenSigTimeoutTime_EVCU2" SG_ 520 Trans_ESS_Inhibit 0;
BA_ "GenSigTimeoutTime_MCPA" SG_ 520 Trans_ESS_Inhibit 0;
BA_ "GenSigTimeoutTime_MCPB" SG_ 520 Trans_ESS_Inhibit 0;
BA_ "GenSigTimeoutTime_SGCP" SG_ 520 Trans_ESS_Inhibit 0;
BA_ "GenSigTimeoutTime_TCM" SG_ 520 Trans_ESS_Inhibit 0;
BA_ "GenSigTimeoutTime_AGSM" SG_ 520 OutputSpdPolarity 0;
BA_ "GenSigTimeoutTime_ECM" SG_ 520 OutputSpdPolarity 0;
BA_ "GenSigTimeoutTime_EVCU2" SG_ 520 OutputSpdPolarity 0;
BA_ "GenSigTimeoutTime_MCPA" SG_ 520 OutputSpdPolarity 0;
BA_ "GenSigTimeoutTime_MCPB" SG_ 520 OutputSpdPolarity 0;
BA_ "GenSigTimeoutTime_SGCP" SG_ 520 OutputSpdPolarity 0;
BA_ "GenSigTimeoutTime_TCM" SG_ 520 OutputSpdPolarity 0;
BA_ "GenSigStartValue" SG_ 520 GearEngagedForDisplay 31;
BA_ "GenSigTimeoutTime_EVCU2" SG_ 520 GearEngagedForDisplay 0;
BA_ "GenSigTimeoutTime_MCPA" SG_ 520 GearEngagedForDisplay 0;
BA_ "GenSigTimeoutTime_MCPB" SG_ 520 GearEngagedForDisplay 0;
BA_ "GenSigTimeoutTime_SGCP" SG_ 520 GearEngagedForDisplay 0;
BA_ "GenSigTimeoutTime_TCM" SG_ 520 GearEngagedForDisplay 0;
BA_ "GenSigStartValue" SG_ 520 AirFlowRequest_TCM 127;
BA_ "GenSigTimeoutTime_AGSM" SG_ 520 AirFlowRequest_TCM 0;
BA_ "GenSigTimeoutTime_EVCU2" SG_ 520 AirFlowRequest_TCM 0;
BA_ "GenSigTimeoutTime_MCPA" SG_ 520 AirFlowRequest_TCM 0;
BA_ "GenSigTimeoutTime_MCPB" SG_ 520 AirFlowRequest_TCM 0;
BA_ "GenSigTimeoutTime_SGCP" SG_ 520 AirFlowRequest_TCM 0;
BA_ "GenSigTimeoutTime_TCM" SG_ 520 AirFlowRequest_TCM 0;
BA_ "GenSigTimeoutTime_AGSM" SG_ 520 TrqCtrlModeReq_Prdtd 0;
BA_ "GenSigTimeoutTime_EVCU2" SG_ 520 TrqCtrlModeReq_Prdtd 0;
BA_ "GenSigTimeoutTime_MCPA" SG_ 520 TrqCtrlModeReq_Prdtd 0;
BA_ "GenSigTimeoutTime_MCPB" SG_ 520 TrqCtrlModeReq_Prdtd 0;
BA_ "GenSigTimeoutTime_SGCP" SG_ 520 TrqCtrlModeReq_Prdtd 0;
BA_ "GenSigTimeoutTime_TCM" SG_ 520 TrqCtrlModeReq_Prdtd 0;
BA_ "GenSigTimeoutTime_AGSM" SG_ 520 TCM_TrqGradLimActive 0;
BA_ "GenSigTimeoutTime_EVCU2" SG_ 520 TCM_TrqGradLimActive 0;
BA_ "GenSigTimeoutTime_MCPA" SG_ 520 TCM_TrqGradLimActive 0;
BA_ "GenSigTimeoutTime_MCPB" SG_ 520 TCM_TrqGradLimActive 0;
BA_ "GenSigTimeoutTime_SGCP" SG_ 520 TCM_TrqGradLimActive 0;
BA_ "GenSigTimeoutTime_TCM" SG_ 520 TCM_TrqGradLimActive 0;
BA_ "GenSigTimeoutTime_AGSM" SG_ 520 TCM_TrqGradLim_Up 0;
BA_ "GenSigTimeoutTime_EVCU2" SG_ 520 TCM_TrqGradLim_Up 0;
BA_ "GenSigTimeoutTime_MCPA" SG_ 520 TCM_TrqGradLim_Up 0;
BA_ "GenSigTimeoutTime_MCPB" SG_ 520 TCM_TrqGradLim_Up 0;
BA_ "GenSigTimeoutTime_SGCP" SG_ 520 TCM_TrqGradLim_Up 0;
BA_ "GenSigTimeoutTime_TCM" SG_ 520 TCM_TrqGradLim_Up 0;
BA_ "GenSigTimeoutTime_AGSM" SG_ 520 TCM_TrqGradLim_Lo 0;
BA_ "GenSigTimeoutTime_EVCU2" SG_ 520 TCM_TrqGradLim_Lo 0;
BA_ "GenSigTimeoutTime_MCPA" SG_ 520 TCM_TrqGradLim_Lo 0;
BA_ "GenSigTimeoutTime_MCPB" SG_ 520 TCM_TrqGradLim_Lo 0;
BA_ "GenSigTimeoutTime_SGCP" SG_ 520 TCM_TrqGradLim_Lo 0;
BA_ "GenSigTimeoutTime_TCM" SG_ 520 TCM_TrqGradLim_Lo 0;
BA_ "GenSigTimeoutTime_AGSM" SG_ 520 TCM_EngFSO_Rq 0;
BA_ "GenSigTimeoutTime_EVCU2" SG_ 520 TCM_EngFSO_Rq 0;
BA_ "GenSigTimeoutTime_MCPA" SG_ 520 TCM_EngFSO_Rq 0;
BA_ "GenSigTimeoutTime_MCPB" SG_ 520 TCM_EngFSO_Rq 0;
BA_ "GenSigTimeoutTime_SGCP" SG_ 520 TCM_EngFSO_Rq 0;
BA_ "GenSigTimeoutTime_TCM" SG_ 520 TCM_EngFSO_Rq 0;
BA_ "GenSigTimeoutTime_AGSM" SG_ 520 TCM_EngFSO_Allw 0;
BA_ "GenSigTimeoutTime_EVCU2" SG_ 520 TCM_EngFSO_Allw 0;
BA_ "GenSigTimeoutTime_MCPA" SG_ 520 TCM_EngFSO_Allw 0;
BA_ "GenSigTimeoutTime_MCPB" SG_ 520 TCM_EngFSO_Allw 0;
BA_ "GenSigTimeoutTime_SGCP" SG_ 520 TCM_EngFSO_Allw 0;
BA_ "GenSigTimeoutTime_TCM" SG_ 520 TCM_EngFSO_Allw 0;
BA_ "GenSigTimeoutTime_AGSM" SG_ 520 TCC_TR 0;
BA_ "GenSigTimeoutTime_ECM" SG_ 520 TCC_TR 0;
BA_ "GenSigTimeoutTime_EVCU2" SG_ 520 TCC_TR 0;
BA_ "GenSigTimeoutTime_MCPA" SG_ 520 TCC_TR 0;
BA_ "GenSigTimeoutTime_MCPB" SG_ 520 TCC_TR 0;
BA_ "GenSigTimeoutTime_SGCP" SG_ 520 TCC_TR 0;
BA_ "GenSigTimeoutTime_TCM" SG_ 520 TCC_TR 0;
BA_ "GenSigStartValue" SG_ 520 TransInputSpeedMaxReq 1022;
BA_ "GenSigTimeoutTime_AGSM" SG_ 520 TransInputSpeedMaxReq 0;
BA_ "GenSigTimeoutTime_EVCU2" SG_ 520 TransInputSpeedMaxReq 0;
BA_ "GenSigTimeoutTime_MCPA" SG_ 520 TransInputSpeedMaxReq 0;
BA_ "GenSigTimeoutTime_MCPB" SG_ 520 TransInputSpeedMaxReq 0;
BA_ "GenSigTimeoutTime_SGCP" SG_ 520 TransInputSpeedMaxReq 0;
BA_ "GenSigTimeoutTime_TCM" SG_ 520 TransInputSpeedMaxReq 0;
BA_ "GenSigStartValue" SG_ 156 GPS_UTC_Second 65535;
BA_ "GenSigTimeoutTime_AGSM" SG_ 156 GPS_UTC_Second 0;
BA_ "GenSigTimeoutTime_ECM" SG_ 156 GPS_UTC_Second 0;
BA_ "GenSigTimeoutTime_EVCU2" SG_ 156 GPS_UTC_Second 0;
BA_ "GenSigTimeoutTime_SGCP" SG_ 156 GPS_UTC_Second 0;
BA_ "GenSigTimeoutTime_TCM" SG_ 156 GPS_UTC_Second 0;
BA_ "GenSigTimeoutTime_TCM" SG_ 156 GPS_UTC_Minute 0;
BA_ "GenSigStartValue" SG_ 156 GPS_UTC_Minute 255;
BA_ "GenSigTimeoutTime_AGSM" SG_ 156 GPS_UTC_Minute 0;
BA_ "GenSigTimeoutTime_ECM" SG_ 156 GPS_UTC_Minute 0;
BA_ "GenSigTimeoutTime_EVCU2" SG_ 156 GPS_UTC_Minute 0;
BA_ "GenSigTimeoutTime_SGCP" SG_ 156 GPS_UTC_Minute 0;
BA_ "GenSigStartValue" SG_ 156 GPS_UTC_Hour 255;
BA_ "GenSigTimeoutTime_AGSM" SG_ 156 GPS_UTC_Hour 0;
BA_ "GenSigTimeoutTime_ECM" SG_ 156 GPS_UTC_Hour 0;
BA_ "GenSigTimeoutTime_EVCU2" SG_ 156 GPS_UTC_Hour 0;
BA_ "GenSigTimeoutTime_SGCP" SG_ 156 GPS_UTC_Hour 0;
BA_ "GenSigTimeoutTime_TCM" SG_ 156 GPS_UTC_Hour 0;
BA_ "GenSigStartValue" SG_ 156 GPS_Date_Year 65535;
BA_ "GenSigTimeoutTime_AGSM" SG_ 156 GPS_Date_Year 0;
BA_ "GenSigTimeoutTime_ECM" SG_ 156 GPS_Date_Year 0;
BA_ "GenSigTimeoutTime_EVCU2" SG_ 156 GPS_Date_Year 0;
BA_ "GenSigTimeoutTime_SGCP" SG_ 156 GPS_Date_Year 0;
BA_ "GenSigTimeoutTime_TCM" SG_ 156 GPS_Date_Year 0;
BA_ "GenSigStartValue" SG_ 156 GPS_Date_Month 255;
BA_ "GenSigTimeoutTime_AGSM" SG_ 156 GPS_Date_Month 0;
BA_ "GenSigTimeoutTime_ECM" SG_ 156 GPS_Date_Month 0;
BA_ "GenSigTimeoutTime_EVCU2" SG_ 156 GPS_Date_Month 0;
BA_ "GenSigTimeoutTime_SGCP" SG_ 156 GPS_Date_Month 0;
BA_ "GenSigTimeoutTime_TCM" SG_ 156 GPS_Date_Month 0;
BA_ "GenSigStartValue" SG_ 156 GPS_Date_Day 255;
BA_ "GenSigTimeoutTime_AGSM" SG_ 156 GPS_Date_Day 0;
BA_ "GenSigTimeoutTime_ECM" SG_ 156 GPS_Date_Day 0;
BA_ "GenSigTimeoutTime_EVCU2" SG_ 156 GPS_Date_Day 0;
BA_ "GenSigTimeoutTime_SGCP" SG_ 156 GPS_Date_Day 0;
BA_ "GenSigTimeoutTime_TCM" SG_ 156 GPS_Date_Day 0;
BA_ "GenSigTimeoutTime_AGSM" SG_ 1058 LoadOBD 0;
BA_ "GenSigTimeoutTime_ECM" SG_ 1058 LoadOBD 0;
BA_ "GenSigTimeoutTime_EVCU2" SG_ 1058 LoadOBD 0;
BA_ "GenSigTimeoutTime_MCPA" SG_ 1058 LoadOBD 0;
BA_ "GenSigTimeoutTime_MCPB" SG_ 1058 LoadOBD 0;
BA_ "GenSigTimeoutTime_SGCP" SG_ 1058 LoadOBD 0;
BA_ "GenSigTimeoutTime_AGSM" SG_ 1058 InputsGDFail 0;
BA_ "GenSigTimeoutTime_ECM" SG_ 1058 InputsGDFail 0;
BA_ "GenSigTimeoutTime_EVCU2" SG_ 1058 InputsGDFail 0;
BA_ "GenSigTimeoutTime_MCPA" SG_ 1058 InputsGDFail 0;
BA_ "GenSigTimeoutTime_MCPB" SG_ 1058 InputsGDFail 0;
BA_ "GenSigTimeoutTime_SGCP" SG_ 1058 InputsGDFail 0;
BA_ "GenSigTimeoutTime_AGSM" SG_ 1058 Inp_ICC_Fail 0;
BA_ "GenSigTimeoutTime_ECM" SG_ 1058 Inp_ICC_Fail 0;
BA_ "GenSigTimeoutTime_EVCU2" SG_ 1058 Inp_ICC_Fail 0;
BA_ "GenSigTimeoutTime_MCPA" SG_ 1058 Inp_ICC_Fail 0;
BA_ "GenSigTimeoutTime_MCPB" SG_ 1058 Inp_ICC_Fail 0;
BA_ "GenSigTimeoutTime_SGCP" SG_ 1058 Inp_ICC_Fail 0;
BA_ "GenSigTimeoutTime_AGSM" SG_ 1058 IgnCntrTrue 0;
BA_ "GenSigTimeoutTime_ECM" SG_ 1058 IgnCntrTrue 0;
BA_ "GenSigTimeoutTime_EVCU2" SG_ 1058 IgnCntrTrue 0;
BA_ "GenSigTimeoutTime_MCPA" SG_ 1058 IgnCntrTrue 0;
BA_ "GenSigTimeoutTime_MCPB" SG_ 1058 IgnCntrTrue 0;
BA_ "GenSigTimeoutTime_SGCP" SG_ 1058 IgnCntrTrue 0;
BA_ "GenSigTimeoutTime_AGSM" SG_ 1058 GenDenominator 0;
BA_ "GenSigTimeoutTime_ECM" SG_ 1058 GenDenominator 0;
BA_ "GenSigTimeoutTime_EVCU2" SG_ 1058 GenDenominator 0;
BA_ "GenSigTimeoutTime_MCPA" SG_ 1058 GenDenominator 0;
BA_ "GenSigTimeoutTime_MCPB" SG_ 1058 GenDenominator 0;
BA_ "GenSigTimeoutTime_SGCP" SG_ 1058 GenDenominator 0;
BA_ "GenSigStartValue" SG_ 1058 EngineOFFTime 1023;
BA_ "GenSigTimeoutTime_AGSM" SG_ 1058 EngineOFFTime 0;
BA_ "GenSigTimeoutTime_ECM" SG_ 1058 EngineOFFTime 0;
BA_ "GenSigTimeoutTime_EVCU2" SG_ 1058 EngineOFFTime 0;
BA_ "GenSigTimeoutTime_MCPA" SG_ 1058 EngineOFFTime 0;
BA_ "GenSigTimeoutTime_MCPB" SG_ 1058 EngineOFFTime 0;
BA_ "GenSigTimeoutTime_SGCP" SG_ 1058 EngineOFFTime 0;
BA_ "GenSigTimeoutTime_AGSM" SG_ 1058 CldStrtDenominator 0;
BA_ "GenSigTimeoutTime_ECM" SG_ 1058 CldStrtDenominator 0;
BA_ "GenSigTimeoutTime_EVCU2" SG_ 1058 CldStrtDenominator 0;
BA_ "GenSigTimeoutTime_MCPA" SG_ 1058 CldStrtDenominator 0;
BA_ "GenSigTimeoutTime_MCPB" SG_ 1058 CldStrtDenominator 0;
BA_ "GenSigTimeoutTime_SGCP" SG_ 1058 CldStrtDenominator 0;
BA_ "GenSigTimeoutTime_TCM" SG_ 1058 CldStrtDenominator 0;
BA_ "GenSigTimeoutTime_AGSM" SG_ 1058 CarbWarmUp 0;
BA_ "GenSigTimeoutTime_ECM" SG_ 1058 CarbWarmUp 0;
BA_ "GenSigTimeoutTime_EVCU2" SG_ 1058 CarbWarmUp 0;
BA_ "GenSigTimeoutTime_MCPA" SG_ 1058 CarbWarmUp 0;
BA_ "GenSigTimeoutTime_MCPB" SG_ 1058 CarbWarmUp 0;
BA_ "GenSigTimeoutTime_SGCP" SG_ 1058 CarbWarmUp 0;
BA_ "GenSigTimeoutTime_AGSM" SG_ 1058 CARB_PERM 0;
BA_ "GenSigTimeoutTime_ECM" SG_ 1058 CARB_PERM 0;
BA_ "GenSigTimeoutTime_EVCU2" SG_ 1058 CARB_PERM 0;
BA_ "GenSigTimeoutTime_MCPA" SG_ 1058 CARB_PERM 0;
BA_ "GenSigTimeoutTime_MCPB" SG_ 1058 CARB_PERM 0;
BA_ "GenSigTimeoutTime_SGCP" SG_ 1058 CARB_PERM 0;
BA_ "GenSigTimeoutTime_AGSM" SG_ 1058 AccelPdlPosn_OBD 0;
BA_ "GenSigTimeoutTime_ECM" SG_ 1058 AccelPdlPosn_OBD 0;
BA_ "GenSigTimeoutTime_EVCU2" SG_ 1058 AccelPdlPosn_OBD 0;
BA_ "GenSigTimeoutTime_MCPA" SG_ 1058 AccelPdlPosn_OBD 0;
BA_ "GenSigTimeoutTime_MCPB" SG_ 1058 AccelPdlPosn_OBD 0;
BA_ "GenSigTimeoutTime_SGCP" SG_ 1058 AccelPdlPosn_OBD 0;
BA_ "GenSigTimeoutTime_AGSM" SG_ 1058 OAT_PT_EstV 0;
BA_ "GenSigTimeoutTime_ECM" SG_ 1058 OAT_PT_EstV 0;
BA_ "GenSigTimeoutTime_MCPA" SG_ 1058 OAT_PT_EstV 0;
BA_ "GenSigTimeoutTime_MCPB" SG_ 1058 OAT_PT_EstV 0;
BA_ "GenSigTimeoutTime_SGCP" SG_ 1058 OAT_PT_EstV 0;
BA_ "GenSigTimeoutTime_TCM" SG_ 1058 OAT_PT_EstV 0;
BA_ "GenSigTimeoutTime_AGSM" SG_ 1058 OAT_PT_Est 0;
BA_ "GenSigTimeoutTime_ECM" SG_ 1058 OAT_PT_Est 0;
BA_ "GenSigTimeoutTime_MCPA" SG_ 1058 OAT_PT_Est 0;
BA_ "GenSigTimeoutTime_MCPB" SG_ 1058 OAT_PT_Est 0;
BA_ "GenSigTimeoutTime_SGCP" SG_ 1058 OAT_PT_Est 0;
BA_ "GenSigTimeoutTime_TCM" SG_ 1058 OAT_PT_Est 0;
BA_ "GenSigStartValue" SG_ 1058 EngOffTmPTV 1;
BA_ "GenSigTimeoutTime_AGSM" SG_ 1058 EngOffTmPTV 0;
BA_ "GenSigTimeoutTime_ECM" SG_ 1058 EngOffTmPTV 0;
BA_ "GenSigTimeoutTime_MCPA" SG_ 1058 EngOffTmPTV 0;
BA_ "GenSigTimeoutTime_MCPB" SG_ 1058 EngOffTmPTV 0;
BA_ "GenSigTimeoutTime_SGCP" SG_ 1058 EngOffTmPTV 0;
BA_ "GenSigTimeoutTime_TCM" SG_ 1058 EngOffTmPTV 0;
BA_ "GenSigTimeoutTime_AGSM" SG_ 1058 EngOffTmPT 0;
BA_ "GenSigTimeoutTime_ECM" SG_ 1058 EngOffTmPT 0;
BA_ "GenSigTimeoutTime_MCPA" SG_ 1058 EngOffTmPT 0;
BA_ "GenSigTimeoutTime_MCPB" SG_ 1058 EngOffTmPT 0;
BA_ "GenSigTimeoutTime_SGCP" SG_ 1058 EngOffTmPT 0;
BA_ "GenSigTimeoutTime_TCM" SG_ 1058 EngOffTmPT 0;
BA_ "GenSigTimeoutTime_AGSM" SG_ 1058 MessageCounter_OBDCONTENTFRAME 0;
BA_ "GenSigTimeoutTime_ECM" SG_ 1058 MessageCounter_OBDCONTENTFRAME 0;
BA_ "GenSigTimeoutTime_MCPA" SG_ 1058 MessageCounter_OBDCONTENTFRAME 0;
BA_ "GenSigTimeoutTime_MCPB" SG_ 1058 MessageCounter_OBDCONTENTFRAME 0;
BA_ "GenSigTimeoutTime_SGCP" SG_ 1058 MessageCounter_OBDCONTENTFRAME 0;
BA_ "GenSigTimeoutTime_AGSM" SG_ 1058 CRC_OBDCONTENTFRAME 0;
BA_ "GenSigTimeoutTime_ECM" SG_ 1058 CRC_OBDCONTENTFRAME 0;
BA_ "GenSigTimeoutTime_MCPA" SG_ 1058 CRC_OBDCONTENTFRAME 0;
BA_ "GenSigTimeoutTime_MCPB" SG_ 1058 CRC_OBDCONTENTFRAME 0;
BA_ "GenSigTimeoutTime_SGCP" SG_ 1058 CRC_OBDCONTENTFRAME 0;
BA_ "GenSigStartValue" SG_ 1626 IMPACTConfirm 1;
BA_ "GenSigInactiveValue" SG_ 1626 IMPACTConfirm 1;
BA_ "GenSigSendType" SG_ 1626 IMPACTConfirm 5;
BA_ "GenSigTimeoutTime_AGSM" SG_ 1626 IMPACTConfirm 0;
BA_ "GenSigTimeoutTime_ECM" SG_ 1626 IMPACTConfirm 0;
BA_ "GenSigTimeoutTime_EVCU2" SG_ 1626 IMPACTConfirm 0;
BA_ "GenSigTimeoutTime_SGCP" SG_ 1626 IMPACTConfirm 0;
BA_ "GenSigTimeoutTime_TCM" SG_ 1626 IMPACTConfirm 0;
BA_ "GenSigSendType" SG_ 1626 IMPACTCommand 5;
BA_ "GenSigTimeoutTime_AGSM" SG_ 1626 IMPACTCommand 0;
BA_ "GenSigTimeoutTime_ECM" SG_ 1626 IMPACTCommand 0;
BA_ "GenSigTimeoutTime_EVCU2" SG_ 1626 IMPACTCommand 0;
BA_ "GenSigTimeoutTime_SGCP" SG_ 1626 IMPACTCommand 0;
BA_ "GenSigTimeoutTime_TCM" SG_ 1626 IMPACTCommand 0;
BA_ "GenSigTimeoutTime_AGSM" SG_ 1055 MdsAct 0;
BA_ "GenSigTimeoutTime_ECM" SG_ 1055 MdsAct 0;
BA_ "GenSigTimeoutTime_EVCU2" SG_ 1055 MdsAct 0;
BA_ "GenSigTimeoutTime_MCPA" SG_ 1055 MdsAct 0;
BA_ "GenSigTimeoutTime_MCPB" SG_ 1055 MdsAct 0;
BA_ "GenSigTimeoutTime_SGCP" SG_ 1055 MdsAct 0;
BA_ "GenSigTimeoutTime_AGSM" SG_ 1055 MessageCounter_ENGINE8 0;
BA_ "GenSigTimeoutTime_ECM" SG_ 1055 MessageCounter_ENGINE8 0;
BA_ "GenSigTimeoutTime_EVCU2" SG_ 1055 MessageCounter_ENGINE8 0;
BA_ "GenSigTimeoutTime_MCPA" SG_ 1055 MessageCounter_ENGINE8 0;
BA_ "GenSigTimeoutTime_MCPB" SG_ 1055 MessageCounter_ENGINE8 0;
BA_ "GenSigTimeoutTime_SGCP" SG_ 1055 MessageCounter_ENGINE8 0;
BA_ "GenSigTimeoutTime_AGSM" SG_ 1055 CRC_ENGINE8 0;
BA_ "GenSigTimeoutTime_ECM" SG_ 1055 CRC_ENGINE8 0;
BA_ "GenSigTimeoutTime_EVCU2" SG_ 1055 CRC_ENGINE8 0;
BA_ "GenSigTimeoutTime_MCPA" SG_ 1055 CRC_ENGINE8 0;
BA_ "GenSigTimeoutTime_MCPB" SG_ 1055 CRC_ENGINE8 0;
BA_ "GenSigTimeoutTime_SGCP" SG_ 1055 CRC_ENGINE8 0;
BA_ "GenSigStartValue" SG_ 1448 CompressorSts 2;
BA_ "GenSigSendType" SG_ 1448 CompressorSts 3;
BA_ "GenSigTimeoutTime_AGSM" SG_ 1448 CompressorSts 0;
BA_ "GenSigTimeoutTime_ECM" SG_ 1448 CompressorSts 0;
BA_ "GenSigTimeoutTime_EVCU2" SG_ 1448 CompressorSts 0;
BA_ "GenSigTimeoutTime_MCPA" SG_ 1448 CompressorSts 0;
BA_ "GenSigTimeoutTime_MCPB" SG_ 1448 CompressorSts 0;
BA_ "GenSigTimeoutTime_SGCP" SG_ 1448 CompressorSts 0;
BA_ "GenSigSendType" SG_ 1448 SpStSwStat 3;
BA_ "GenSigTimeoutTime_AGSM" SG_ 1448 SpStSwStat 0;
BA_ "GenSigTimeoutTime_ECM" SG_ 1448 SpStSwStat 0;
BA_ "GenSigTimeoutTime_EVCU2" SG_ 1448 SpStSwStat 0;
BA_ "GenSigTimeoutTime_MCPA" SG_ 1448 SpStSwStat 0;
BA_ "GenSigTimeoutTime_MCPB" SG_ 1448 SpStSwStat 0;
BA_ "GenSigTimeoutTime_TCM" SG_ 1448 SpStSwStat 0;
BA_ "GenSigSendType" SG_ 1448 SpStDispstat 3;
BA_ "GenSigTimeoutTime_AGSM" SG_ 1448 SpStDispstat 0;
BA_ "GenSigTimeoutTime_ECM" SG_ 1448 SpStDispstat 0;
BA_ "GenSigTimeoutTime_EVCU2" SG_ 1448 SpStDispstat 0;
BA_ "GenSigTimeoutTime_MCPA" SG_ 1448 SpStDispstat 0;
BA_ "GenSigTimeoutTime_MCPB" SG_ 1448 SpStDispstat 0;
BA_ "GenSigTimeoutTime_SGCP" SG_ 1448 SpStDispstat 0;
BA_ "GenSigTimeoutTime_AGSM" SG_ 1448 MessageCounter_ENGINE7 0;
BA_ "GenSigTimeoutTime_ECM" SG_ 1448 MessageCounter_ENGINE7 0;
BA_ "GenSigTimeoutTime_EVCU2" SG_ 1448 MessageCounter_ENGINE7 0;
BA_ "GenSigTimeoutTime_MCPA" SG_ 1448 MessageCounter_ENGINE7 0;
BA_ "GenSigTimeoutTime_MCPB" SG_ 1448 MessageCounter_ENGINE7 0;
BA_ "GenSigTimeoutTime_SGCP" SG_ 1448 MessageCounter_ENGINE7 0;
BA_ "GenSigTimeoutTime_AGSM" SG_ 1448 CRC_ENGINE7 0;
BA_ "GenSigTimeoutTime_ECM" SG_ 1448 CRC_ENGINE7 0;
BA_ "GenSigTimeoutTime_EVCU2" SG_ 1448 CRC_ENGINE7 0;
BA_ "GenSigTimeoutTime_MCPA" SG_ 1448 CRC_ENGINE7 0;
BA_ "GenSigTimeoutTime_MCPB" SG_ 1448 CRC_ENGINE7 0;
BA_ "GenSigTimeoutTime_SGCP" SG_ 1448 CRC_ENGINE7 0;
BA_ "GenSigTimeoutTime_AGSM" SG_ 751 StartRelayECMFeedbackFault 0;
BA_ "GenSigTimeoutTime_ECM" SG_ 751 StartRelayECMFeedbackFault 0;
BA_ "GenSigTimeoutTime_EVCU2" SG_ 751 StartRelayECMFeedbackFault 0;
BA_ "GenSigTimeoutTime_MCPA" SG_ 751 StartRelayECMFeedbackFault 0;
BA_ "GenSigTimeoutTime_MCPB" SG_ 751 StartRelayECMFeedbackFault 0;
BA_ "GenSigTimeoutTime_SGCP" SG_ 751 StartRelayECMFeedbackFault 0;
BA_ "GenSigTimeoutTime_TCM" SG_ 751 StartRelayECMFeedbackFault 0;
BA_ "GenSigTimeoutTime_AGSM" SG_ 751 EngineWaterTemp 0;
BA_ "GenSigTimeoutTime_ECM" SG_ 751 EngineWaterTemp 0;
BA_ "GenSigTimeoutTime_EVCU2" SG_ 751 EngineWaterTemp 0;
BA_ "GenSigTimeoutTime_MCPA" SG_ 751 EngineWaterTemp 0;
BA_ "GenSigTimeoutTime_MCPB" SG_ 751 EngineWaterTemp 0;
BA_ "GenSigTimeoutTime_SGCP" SG_ 751 EngineWaterTemp 0;
BA_ "GenSigStartValue" SG_ 751 TerrainModeStat_ECM 31;
BA_ "GenSigTimeoutTime_AGSM" SG_ 751 TerrainModeStat_ECM 0;
BA_ "GenSigTimeoutTime_ECM" SG_ 751 TerrainModeStat_ECM 0;
BA_ "GenSigTimeoutTime_EVCU2" SG_ 751 TerrainModeStat_ECM 0;
BA_ "GenSigTimeoutTime_MCPA" SG_ 751 TerrainModeStat_ECM 0;
BA_ "GenSigTimeoutTime_MCPB" SG_ 751 TerrainModeStat_ECM 0;
BA_ "GenSigTimeoutTime_SGCP" SG_ 751 TerrainModeStat_ECM 0;
BA_ "GenSigTimeoutTime_AGSM" SG_ 751 MessageCounter_ENGINE6 0;
BA_ "GenSigTimeoutTime_ECM" SG_ 751 MessageCounter_ENGINE6 0;
BA_ "GenSigTimeoutTime_EVCU2" SG_ 751 MessageCounter_ENGINE6 0;
BA_ "GenSigTimeoutTime_MCPA" SG_ 751 MessageCounter_ENGINE6 0;
BA_ "GenSigTimeoutTime_MCPB" SG_ 751 MessageCounter_ENGINE6 0;
BA_ "GenSigTimeoutTime_SGCP" SG_ 751 MessageCounter_ENGINE6 0;
BA_ "GenSigTimeoutTime_AGSM" SG_ 751 CRC_ENGINE6 0;
BA_ "GenSigTimeoutTime_ECM" SG_ 751 CRC_ENGINE6 0;
BA_ "GenSigTimeoutTime_EVCU2" SG_ 751 CRC_ENGINE6 0;
BA_ "GenSigTimeoutTime_MCPA" SG_ 751 CRC_ENGINE6 0;
BA_ "GenSigTimeoutTime_MCPB" SG_ 751 CRC_ENGINE6 0;
BA_ "GenSigTimeoutTime_SGCP" SG_ 751 CRC_ENGINE6 0;
BA_ "GenSigTimeoutTime_AGSM" SG_ 751 Trns_DrvMdReq_ECM 0;
BA_ "GenSigTimeoutTime_ECM" SG_ 751 Trns_DrvMdReq_ECM 0;
BA_ "GenSigTimeoutTime_EVCU2" SG_ 751 Trns_DrvMdReq_ECM 0;
BA_ "GenSigTimeoutTime_MCPA" SG_ 751 Trns_DrvMdReq_ECM 0;
BA_ "GenSigTimeoutTime_MCPB" SG_ 751 Trns_DrvMdReq_ECM 0;
BA_ "GenSigTimeoutTime_EVCU2" SG_ 518 RPMOverRev_W 0;
BA_ "GenSigTimeoutTime_AGSM" SG_ 518 RPMOverRev_W 0;
BA_ "GenSigTimeoutTime_ECM" SG_ 518 RPMOverRev_W 0;
BA_ "GenSigTimeoutTime_MCPA" SG_ 518 RPMOverRev_W 0;
BA_ "GenSigTimeoutTime_MCPB" SG_ 518 RPMOverRev_W 0;
BA_ "GenSigTimeoutTime_SGCP" SG_ 518 RPMOverRev_W 0;
BA_ "GenSigTimeoutTime_TCM" SG_ 518 RPMOverRev_W 0;
BA_ "GenSigTimeoutTime_AGSM" SG_ 518 MessageCounter_ENGINE5 0;
BA_ "GenSigTimeoutTime_ECM" SG_ 518 MessageCounter_ENGINE5 0;
BA_ "GenSigTimeoutTime_MCPA" SG_ 518 MessageCounter_ENGINE5 0;
BA_ "GenSigTimeoutTime_MCPB" SG_ 518 MessageCounter_ENGINE5 0;
BA_ "GenSigTimeoutTime_SGCP" SG_ 518 MessageCounter_ENGINE5 0;
BA_ "GenSigTimeoutTime_AGSM" SG_ 518 GrMin_Rq_ECM_W 0;
BA_ "GenSigTimeoutTime_ECM" SG_ 518 GrMin_Rq_ECM_W 0;
BA_ "GenSigTimeoutTime_EVCU2" SG_ 518 GrMin_Rq_ECM_W 0;
BA_ "GenSigTimeoutTime_MCPA" SG_ 518 GrMin_Rq_ECM_W 0;
BA_ "GenSigTimeoutTime_MCPB" SG_ 518 GrMin_Rq_ECM_W 0;
BA_ "GenSigTimeoutTime_SGCP" SG_ 518 GrMin_Rq_ECM_W 0;
BA_ "GenSigTimeoutTime_AGSM" SG_ 518 GrMax_Rq_ECM_W 0;
BA_ "GenSigTimeoutTime_ECM" SG_ 518 GrMax_Rq_ECM_W 0;
BA_ "GenSigTimeoutTime_EVCU2" SG_ 518 GrMax_Rq_ECM_W 0;
BA_ "GenSigTimeoutTime_MCPA" SG_ 518 GrMax_Rq_ECM_W 0;
BA_ "GenSigTimeoutTime_MCPB" SG_ 518 GrMax_Rq_ECM_W 0;
BA_ "GenSigTimeoutTime_SGCP" SG_ 518 GrMax_Rq_ECM_W 0;
BA_ "GenSigStartValue" SG_ 518 EngTrqMaxCorrFctr_W 255;
BA_ "GenSigTimeoutTime_AGSM" SG_ 518 EngTrqMaxCorrFctr_W 0;
BA_ "GenSigTimeoutTime_ECM" SG_ 518 EngTrqMaxCorrFctr_W 0;
BA_ "GenSigTimeoutTime_EVCU2" SG_ 518 EngTrqMaxCorrFctr_W 0;
BA_ "GenSigTimeoutTime_MCPA" SG_ 518 EngTrqMaxCorrFctr_W 0;
BA_ "GenSigTimeoutTime_MCPB" SG_ 518 EngTrqMaxCorrFctr_W 0;
BA_ "GenSigTimeoutTime_SGCP" SG_ 518 EngTrqMaxCorrFctr_W 0;
BA_ "GenSigTimeoutTime_AGSM" SG_ 518 EngineReadyForESS_W 0;
BA_ "GenSigTimeoutTime_ECM" SG_ 518 EngineReadyForESS_W 0;
BA_ "GenSigTimeoutTime_EVCU2" SG_ 518 EngineReadyForESS_W 0;
BA_ "GenSigTimeoutTime_MCPA" SG_ 518 EngineReadyForESS_W 0;
BA_ "GenSigTimeoutTime_MCPB" SG_ 518 EngineReadyForESS_W 0;
BA_ "GenSigTimeoutTime_SGCP" SG_ 518 EngineReadyForESS_W 0;
BA_ "GenSigTimeoutTime_AGSM" SG_ 518 ECM_READINESS_RESET_W 0;
BA_ "GenSigTimeoutTime_ECM" SG_ 518 ECM_READINESS_RESET_W 0;
BA_ "GenSigTimeoutTime_EVCU2" SG_ 518 ECM_READINESS_RESET_W 0;
BA_ "GenSigTimeoutTime_MCPA" SG_ 518 ECM_READINESS_RESET_W 0;
BA_ "GenSigTimeoutTime_MCPB" SG_ 518 ECM_READINESS_RESET_W 0;
BA_ "GenSigTimeoutTime_SGCP" SG_ 518 ECM_READINESS_RESET_W 0;
BA_ "GenSigTimeoutTime_AGSM" SG_ 518 ECM_CODE_CLR_W 0;
BA_ "GenSigTimeoutTime_ECM" SG_ 518 ECM_CODE_CLR_W 0;
BA_ "GenSigTimeoutTime_EVCU2" SG_ 518 ECM_CODE_CLR_W 0;
BA_ "GenSigTimeoutTime_MCPA" SG_ 518 ECM_CODE_CLR_W 0;
BA_ "GenSigTimeoutTime_MCPB" SG_ 518 ECM_CODE_CLR_W 0;
BA_ "GenSigTimeoutTime_SGCP" SG_ 518 ECM_CODE_CLR_W 0;
BA_ "GenSigTimeoutTime_AGSM" SG_ 518 CRC_ENGINE5 0;
BA_ "GenSigTimeoutTime_ECM" SG_ 518 CRC_ENGINE5 0;
BA_ "GenSigTimeoutTime_MCPA" SG_ 518 CRC_ENGINE5 0;
BA_ "GenSigTimeoutTime_MCPB" SG_ 518 CRC_ENGINE5 0;
BA_ "GenSigTimeoutTime_SGCP" SG_ 518 CRC_ENGINE5 0;
BA_ "GenSigTimeoutTime_AGSM" SG_ 1054 VehicleSetSpeed_W 0;
BA_ "GenSigTimeoutTime_ECM" SG_ 1054 VehicleSetSpeed_W 0;
BA_ "GenSigTimeoutTime_EVCU2" SG_ 1054 VehicleSetSpeed_W 0;
BA_ "GenSigTimeoutTime_MCPA" SG_ 1054 VehicleSetSpeed_W 0;
BA_ "GenSigTimeoutTime_MCPB" SG_ 1054 VehicleSetSpeed_W 0;
BA_ "GenSigTimeoutTime_SGCP" SG_ 1054 VehicleSetSpeed_W 0;
BA_ "GenSigTimeoutTime_AGSM" SG_ 1054 TransWarmUpReq 0;
BA_ "GenSigTimeoutTime_ECM" SG_ 1054 TransWarmUpReq 0;
BA_ "GenSigTimeoutTime_EVCU2" SG_ 1054 TransWarmUpReq 0;
BA_ "GenSigTimeoutTime_MCPA" SG_ 1054 TransWarmUpReq 0;
BA_ "GenSigTimeoutTime_MCPB" SG_ 1054 TransWarmUpReq 0;
BA_ "GenSigTimeoutTime_SGCP" SG_ 1054 TransWarmUpReq 0;
BA_ "GenSigTimeoutTime_AGSM" SG_ 1054 TransWarmUpMin_RPM 0;
BA_ "GenSigTimeoutTime_ECM" SG_ 1054 TransWarmUpMin_RPM 0;
BA_ "GenSigTimeoutTime_EVCU2" SG_ 1054 TransWarmUpMin_RPM 0;
BA_ "GenSigTimeoutTime_MCPA" SG_ 1054 TransWarmUpMin_RPM 0;
BA_ "GenSigTimeoutTime_MCPB" SG_ 1054 TransWarmUpMin_RPM 0;
BA_ "GenSigTimeoutTime_SGCP" SG_ 1054 TransWarmUpMin_RPM 0;
BA_ "GenSigTimeoutTime_EVCU2" SG_ 1054 ThermalManagementActive_W 0;
BA_ "GenSigTimeoutTime_AGSM" SG_ 1054 ThermalManagementActive_W 0;
BA_ "GenSigTimeoutTime_ECM" SG_ 1054 ThermalManagementActive_W 0;
BA_ "GenSigTimeoutTime_MCPA" SG_ 1054 ThermalManagementActive_W 0;
BA_ "GenSigTimeoutTime_MCPB" SG_ 1054 ThermalManagementActive_W 0;
BA_ "GenSigTimeoutTime_SGCP" SG_ 1054 ThermalManagementActive_W 0;
BA_ "GenSigTimeoutTime_EVCU2" SG_ 1054 MessageCounter_ENGINE1 0;
BA_ "GenSigTimeoutTime_AGSM" SG_ 1054 MessageCounter_ENGINE1 0;
BA_ "GenSigTimeoutTime_ECM" SG_ 1054 MessageCounter_ENGINE1 0;
BA_ "GenSigTimeoutTime_MCPA" SG_ 1054 MessageCounter_ENGINE1 0;
BA_ "GenSigTimeoutTime_MCPB" SG_ 1054 MessageCounter_ENGINE1 0;
BA_ "GenSigTimeoutTime_SGCP" SG_ 1054 MessageCounter_ENGINE1 0;
BA_ "GenSigStartValue" SG_ 1054 EngMaxRPM_W 255;
BA_ "GenSigTimeoutTime_AGSM" SG_ 1054 EngMaxRPM_W 0;
BA_ "GenSigTimeoutTime_ECM" SG_ 1054 EngMaxRPM_W 0;
BA_ "GenSigTimeoutTime_EVCU2" SG_ 1054 EngMaxRPM_W 0;
BA_ "GenSigTimeoutTime_MCPA" SG_ 1054 EngMaxRPM_W 0;
BA_ "GenSigTimeoutTime_MCPB" SG_ 1054 EngMaxRPM_W 0;
BA_ "GenSigTimeoutTime_SGCP" SG_ 1054 EngMaxRPM_W 0;
BA_ "GenSigTimeoutTime_EVCU2" SG_ 1054 CRC_ENGINE1 0;
BA_ "GenSigTimeoutTime_AGSM" SG_ 1054 CRC_ENGINE1 0;
BA_ "GenSigTimeoutTime_ECM" SG_ 1054 CRC_ENGINE1 0;
BA_ "GenSigTimeoutTime_MCPA" SG_ 1054 CRC_ENGINE1 0;
BA_ "GenSigTimeoutTime_MCPB" SG_ 1054 CRC_ENGINE1 0;
BA_ "GenSigTimeoutTime_SGCP" SG_ 1054 CRC_ENGINE1 0;
BA_ "GenSigTimeoutTime_AGSM" SG_ 1054 AtmosphericPressureFailSts_W 0;
BA_ "GenSigTimeoutTime_ECM" SG_ 1054 AtmosphericPressureFailSts_W 0;
BA_ "GenSigTimeoutTime_EVCU2" SG_ 1054 AtmosphericPressureFailSts_W 0;
BA_ "GenSigTimeoutTime_MCPA" SG_ 1054 AtmosphericPressureFailSts_W 0;
BA_ "GenSigTimeoutTime_MCPB" SG_ 1054 AtmosphericPressureFailSts_W 0;
BA_ "GenSigTimeoutTime_SGCP" SG_ 1054 AtmosphericPressureFailSts_W 0;
BA_ "GenSigStartValue" SG_ 1054 AtmosphericPressure_W 255;
BA_ "GenSigTimeoutTime_AGSM" SG_ 1054 AtmosphericPressure_W 0;
BA_ "GenSigTimeoutTime_ECM" SG_ 1054 AtmosphericPressure_W 0;
BA_ "GenSigTimeoutTime_EVCU2" SG_ 1054 AtmosphericPressure_W 0;
BA_ "GenSigTimeoutTime_MCPA" SG_ 1054 AtmosphericPressure_W 0;
BA_ "GenSigTimeoutTime_MCPB" SG_ 1054 AtmosphericPressure_W 0;
BA_ "GenSigTimeoutTime_SGCP" SG_ 1054 AtmosphericPressure_W 0;
BA_ "GenSigTimeoutTime_AGSM" SG_ 2654817816 ECU_APPL_FD_TCM 0;
BA_ "GenSigTimeoutTime_ECM" SG_ 2654817816 ECU_APPL_FD_TCM 0;
BA_ "GenSigTimeoutTime_EVCU2" SG_ 2654817816 ECU_APPL_FD_TCM 0;
BA_ "GenSigTimeoutTime_MCPA" SG_ 2654817816 ECU_APPL_FD_TCM 0;
BA_ "GenSigTimeoutTime_MCPB" SG_ 2654817816 ECU_APPL_FD_TCM 0;
BA_ "GenSigTimeoutTime_SGCP" SG_ 2654817816 ECU_APPL_FD_TCM 0;
BA_ "GenSigTimeoutTime_TCM" SG_ 2654817816 ECU_APPL_FD_TCM 0;
BA_ "GenSigTimeoutTime_AGSM" SG_ 2564554482 N_PDU_18DBFEF2 0;
BA_ "GenSigTimeoutTime_ECM" SG_ 2564554482 N_PDU_18DBFEF2 0;
BA_ "GenSigTimeoutTime_EVCU2" SG_ 2564554482 N_PDU_18DBFEF2 0;
BA_ "GenSigTimeoutTime_MCPA" SG_ 2564554482 N_PDU_18DBFEF2 0;
BA_ "GenSigTimeoutTime_MCPB" SG_ 2564554482 N_PDU_18DBFEF2 0;
BA_ "GenSigTimeoutTime_SGCP" SG_ 2564554482 N_PDU_18DBFEF2 0;
BA_ "GenSigSendType" SG_ 1155 ESCFailSts 3;
BA_ "GenSigTimeoutTime_AGSM" SG_ 1155 ESCFailSts 0;
BA_ "GenSigTimeoutTime_ECM" SG_ 1155 ESCFailSts 0;
BA_ "GenSigTimeoutTime_EVCU2" SG_ 1155 ESCFailSts 0;
BA_ "GenSigTimeoutTime_MCPA" SG_ 1155 ESCFailSts 0;
BA_ "GenSigTimeoutTime_SGCP" SG_ 1155 ESCFailSts 0;
BA_ "GenSigTimeoutTime_TCM" SG_ 1155 ESCFailSts 0;
BA_ "GenSigSendType" SG_ 1155 ABSFailSts 3;
BA_ "GenSigTimeoutTime_AGSM" SG_ 1155 ABSFailSts 0;
BA_ "GenSigTimeoutTime_ECM" SG_ 1155 ABSFailSts 0;
BA_ "GenSigTimeoutTime_EVCU2" SG_ 1155 ABSFailSts 0;
BA_ "GenSigTimeoutTime_MCPA" SG_ 1155 ABSFailSts 0;
BA_ "GenSigTimeoutTime_SGCP" SG_ 1155 ABSFailSts 0;
BA_ "GenSigTimeoutTime_TCM" SG_ 1155 ABSFailSts 0;
BA_ "GenSigTimeoutTime_TCM" SG_ 609 EPBSts 0;
BA_ "GenSigSendType" SG_ 609 EPBSts 3;
BA_ "GenSigTimeoutTime_AGSM" SG_ 609 EPBSts 0;
BA_ "GenSigTimeoutTime_ECM" SG_ 609 EPBSts 0;
BA_ "GenSigTimeoutTime_EVCU2" SG_ 609 EPBSts 0;
BA_ "GenSigTimeoutTime_AGSM" SG_ 1066 ExternalTemperature 0;
BA_ "GenSigTimeoutTime_ECM" SG_ 1066 ExternalTemperature 0;
BA_ "GenSigTimeoutTime_EVCU2" SG_ 1066 ExternalTemperature 0;
BA_ "GenSigTimeoutTime_SGCP" SG_ 1066 ExternalTemperature 0;
BA_ "GenSigTimeoutTime_TCM" SG_ 1066 ExternalTemperature 0;
BA_ "GenSigSendType" SG_ 1153 CmdIgnSts 3;
BA_ "GenSigTimeoutTime_AGSM" SG_ 1153 CmdIgnSts 0;
BA_ "GenSigTimeoutTime_ECM" SG_ 1153 CmdIgnSts 0;
BA_ "GenSigTimeoutTime_EVCU2" SG_ 1153 CmdIgnSts 0;
BA_ "GenSigTimeoutTime_SGCP" SG_ 1153 CmdIgnSts 0;
BA_ "GenSigTimeoutTime_TCM" SG_ 1153 CmdIgnSts 0;
BA_ "GenSigTimeoutTime_AGSM" SG_ 1153 MessageCounter_BCM10 0;
BA_ "GenSigTimeoutTime_ECM" SG_ 1153 MessageCounter_BCM10 0;
BA_ "GenSigTimeoutTime_EVCU2" SG_ 1153 MessageCounter_BCM10 0;
BA_ "GenSigTimeoutTime_MCPA" SG_ 1153 MessageCounter_BCM10 0;
BA_ "GenSigTimeoutTime_TCM" SG_ 1153 MessageCounter_BCM10 0;
BA_ "GenSigTimeoutTime_AGSM" SG_ 1153 CRC_BCM10 0;
BA_ "GenSigTimeoutTime_ECM" SG_ 1153 CRC_BCM10 0;
BA_ "GenSigTimeoutTime_EVCU2" SG_ 1153 CRC_BCM10 0;
BA_ "GenSigTimeoutTime_MCPA" SG_ 1153 CRC_BCM10 0;
BA_ "GenSigTimeoutTime_TCM" SG_ 1153 CRC_BCM10 0;
BA_ "GenSigTimeoutTime_AGSM" SG_ 255 SumTorqueTgt_SEM 0;
BA_ "GenSigTimeoutTime_ECM" SG_ 255 SumTorqueTgt_SEM 0;
BA_ "GenSigTimeoutTime_EVCU2" SG_ 255 SumTorqueTgt_SEM 0;
BA_ "GenSigTimeoutTime_MCPA" SG_ 255 SumTorqueTgt_SEM 0;
BA_ "GenSigTimeoutTime_MCPB" SG_ 255 SumTorqueTgt_SEM 0;
BA_ "GenSigTimeoutTime_SGCP" SG_ 255 SumTorqueTgt_SEM 0;
BA_ "GenSigTimeoutTime_AGSM" SG_ 255 SumTorqueStatic_SEM 0;
BA_ "GenSigTimeoutTime_ECM" SG_ 255 SumTorqueStatic_SEM 0;
BA_ "GenSigTimeoutTime_EVCU2" SG_ 255 SumTorqueStatic_SEM 0;
BA_ "GenSigTimeoutTime_MCPA" SG_ 255 SumTorqueStatic_SEM 0;
BA_ "GenSigTimeoutTime_MCPB" SG_ 255 SumTorqueStatic_SEM 0;
BA_ "GenSigTimeoutTime_SGCP" SG_ 255 SumTorqueStatic_SEM 0;
BA_ "GenSigTimeoutTime_AGSM" SG_ 255 SumTorqueStatic 0;
BA_ "GenSigTimeoutTime_ECM" SG_ 255 SumTorqueStatic 0;
BA_ "GenSigTimeoutTime_EVCU2" SG_ 255 SumTorqueStatic 0;
BA_ "GenSigTimeoutTime_MCPA" SG_ 255 SumTorqueStatic 0;
BA_ "GenSigTimeoutTime_MCPB" SG_ 255 SumTorqueStatic 0;
BA_ "GenSigTimeoutTime_SGCP" SG_ 255 SumTorqueStatic 0;
BA_ "GenSigTimeoutTime_AGSM" SG_ 255 SumTorqueSel_D_TTC 0;
BA_ "GenSigTimeoutTime_ECM" SG_ 255 SumTorqueSel_D_TTC 0;
BA_ "GenSigTimeoutTime_EVCU2" SG_ 255 SumTorqueSel_D_TTC 0;
BA_ "GenSigTimeoutTime_MCPA" SG_ 255 SumTorqueSel_D_TTC 0;
BA_ "GenSigTimeoutTime_MCPB" SG_ 255 SumTorqueSel_D_TTC 0;
BA_ "GenSigTimeoutTime_SGCP" SG_ 255 SumTorqueSel_D_TTC 0;
BA_ "GenSigTimeoutTime_AGSM" SG_ 255 SumTorqueMin 0;
BA_ "GenSigTimeoutTime_ECM" SG_ 255 SumTorqueMin 0;
BA_ "GenSigTimeoutTime_EVCU2" SG_ 255 SumTorqueMin 0;
BA_ "GenSigTimeoutTime_MCPA" SG_ 255 SumTorqueMin 0;
BA_ "GenSigTimeoutTime_MCPB" SG_ 255 SumTorqueMin 0;
BA_ "GenSigTimeoutTime_SGCP" SG_ 255 SumTorqueMin 0;
BA_ "GenSigTimeoutTime_AGSM" SG_ 255 SumTorqueMax 0;
BA_ "GenSigTimeoutTime_ECM" SG_ 255 SumTorqueMax 0;
BA_ "GenSigTimeoutTime_EVCU2" SG_ 255 SumTorqueMax 0;
BA_ "GenSigTimeoutTime_MCPA" SG_ 255 SumTorqueMax 0;
BA_ "GenSigTimeoutTime_MCPB" SG_ 255 SumTorqueMax 0;
BA_ "GenSigTimeoutTime_SGCP" SG_ 255 SumTorqueMax 0;
BA_ "GenSigTimeoutTime_AGSM" SG_ 255 SumTorque_DrvReqMod 0;
BA_ "GenSigTimeoutTime_ECM" SG_ 255 SumTorque_DrvReqMod 0;
BA_ "GenSigTimeoutTime_EVCU2" SG_ 255 SumTorque_DrvReqMod 0;
BA_ "GenSigTimeoutTime_MCPA" SG_ 255 SumTorque_DrvReqMod 0;
BA_ "GenSigTimeoutTime_MCPB" SG_ 255 SumTorque_DrvReqMod 0;
BA_ "GenSigTimeoutTime_SGCP" SG_ 255 SumTorque_DrvReqMod 0;
BA_ "GenSigTimeoutTime_AGSM" SG_ 255 MessageCounter_PT_TORQUE_FD_1 0;
BA_ "GenSigTimeoutTime_ECM" SG_ 255 MessageCounter_PT_TORQUE_FD_1 0;
BA_ "GenSigTimeoutTime_EVCU2" SG_ 255 MessageCounter_PT_TORQUE_FD_1 0;
BA_ "GenSigTimeoutTime_MCPA" SG_ 255 MessageCounter_PT_TORQUE_FD_1 0;
BA_ "GenSigTimeoutTime_MCPB" SG_ 255 MessageCounter_PT_TORQUE_FD_1 0;
BA_ "GenSigTimeoutTime_SGCP" SG_ 255 MessageCounter_PT_TORQUE_FD_1 0;
BA_ "GenSigTimeoutTime_TCM" SG_ 255 MessageCounter_PT_TORQUE_FD_1 0;
BA_ "GenSigTimeoutTime_AGSM" SG_ 255 CRC_PT_TORQUE_FD_1 0;
BA_ "GenSigTimeoutTime_ECM" SG_ 255 CRC_PT_TORQUE_FD_1 0;
BA_ "GenSigTimeoutTime_EVCU2" SG_ 255 CRC_PT_TORQUE_FD_1 0;
BA_ "GenSigTimeoutTime_MCPA" SG_ 255 CRC_PT_TORQUE_FD_1 0;
BA_ "GenSigTimeoutTime_MCPB" SG_ 255 CRC_PT_TORQUE_FD_1 0;
BA_ "GenSigTimeoutTime_SGCP" SG_ 255 CRC_PT_TORQUE_FD_1 0;
BA_ "GenSigTimeoutTime_TCM" SG_ 255 CRC_PT_TORQUE_FD_1 0;
BA_ "GenSigTimeoutTime_AGSM" SG_ 255 Accel_Pedal_Override 0;
BA_ "GenSigTimeoutTime_ECM" SG_ 255 Accel_Pedal_Override 0;
BA_ "GenSigTimeoutTime_EVCU2" SG_ 255 Accel_Pedal_Override 0;
BA_ "GenSigTimeoutTime_MCPA" SG_ 255 Accel_Pedal_Override 0;
BA_ "GenSigTimeoutTime_MCPB" SG_ 255 Accel_Pedal_Override 0;
BA_ "GenSigTimeoutTime_TCM" SG_ 255 Accel_Pedal_Override 0;
BA_ "GenSigTimeoutTime_EVCU2" SG_ 1032 MessageCounter_HYBRID_THERMAL_CO 0;
BA_ "GenSigTimeoutTime_AGSM" SG_ 1032 MessageCounter_HYBRID_THERMAL_CO 0;
BA_ "GenSigTimeoutTime_ECM" SG_ 1032 MessageCounter_HYBRID_THERMAL_CO 0;
BA_ "GenSigTimeoutTime_MCPA" SG_ 1032 MessageCounter_HYBRID_THERMAL_CO 0;
BA_ "GenSigTimeoutTime_MCPB" SG_ 1032 MessageCounter_HYBRID_THERMAL_CO 0;
BA_ "GenSigTimeoutTime_SGCP" SG_ 1032 MessageCounter_HYBRID_THERMAL_CO 0;
BA_ "GenSigTimeoutTime_TCM" SG_ 1032 MessageCounter_HYBRID_THERMAL_CO 0;
BA_ "SystemSignalLongSymbol" SG_ 1032 MessageCounter_HYBRID_THERMAL_CO "MessageCounter_HYBRID_THERMAL_COMMAND";
BA_ "GenSigTimeoutTime_EVCU2" SG_ 1032 CRC_HYBRID_THERMAL_COMMAND 0;
BA_ "GenSigTimeoutTime_AGSM" SG_ 1032 CRC_HYBRID_THERMAL_COMMAND 0;
BA_ "GenSigTimeoutTime_ECM" SG_ 1032 CRC_HYBRID_THERMAL_COMMAND 0;
BA_ "GenSigTimeoutTime_MCPA" SG_ 1032 CRC_HYBRID_THERMAL_COMMAND 0;
BA_ "GenSigTimeoutTime_MCPB" SG_ 1032 CRC_HYBRID_THERMAL_COMMAND 0;
BA_ "GenSigTimeoutTime_SGCP" SG_ 1032 CRC_HYBRID_THERMAL_COMMAND 0;
BA_ "GenSigTimeoutTime_TCM" SG_ 1032 CRC_HYBRID_THERMAL_COMMAND 0;
BA_ "GenSigTimeoutTime_AGSM" SG_ 1032 SGCP_OIL_TEMP 0;
BA_ "GenSigTimeoutTime_ECM" SG_ 1032 SGCP_OIL_TEMP 0;
BA_ "GenSigTimeoutTime_EVCU2" SG_ 1032 SGCP_OIL_TEMP 0;
BA_ "GenSigTimeoutTime_MCPA" SG_ 1032 SGCP_OIL_TEMP 0;
BA_ "GenSigTimeoutTime_MCPB" SG_ 1032 SGCP_OIL_TEMP 0;
BA_ "GenSigTimeoutTime_TCM" SG_ 1032 SGCP_OIL_TEMP 0;
BA_ "GenSigTimeoutTime_AGSM" SG_ 1032 SGCP_OIL_FlwRate 0;
BA_ "GenSigTimeoutTime_ECM" SG_ 1032 SGCP_OIL_FlwRate 0;
BA_ "GenSigTimeoutTime_EVCU2" SG_ 1032 SGCP_OIL_FlwRate 0;
BA_ "GenSigTimeoutTime_MCPA" SG_ 1032 SGCP_OIL_FlwRate 0;
BA_ "GenSigTimeoutTime_MCPB" SG_ 1032 SGCP_OIL_FlwRate 0;
BA_ "GenSigTimeoutTime_TCM" SG_ 1032 SGCP_OIL_FlwRate 0;
BA_ "GenSigTimeoutTime_AGSM" SG_ 1032 EOPB_OIL_TEMP 0;
BA_ "GenSigTimeoutTime_ECM" SG_ 1032 EOPB_OIL_TEMP 0;
BA_ "GenSigTimeoutTime_EVCU2" SG_ 1032 EOPB_OIL_TEMP 0;
BA_ "GenSigTimeoutTime_MCPA" SG_ 1032 EOPB_OIL_TEMP 0;
BA_ "GenSigTimeoutTime_SGCP" SG_ 1032 EOPB_OIL_TEMP 0;
BA_ "GenSigTimeoutTime_TCM" SG_ 1032 EOPB_OIL_TEMP 0;
BA_ "GenSigTimeoutTime_AGSM" SG_ 1032 EOPB_OIL_FlwRate 0;
BA_ "GenSigTimeoutTime_ECM" SG_ 1032 EOPB_OIL_FlwRate 0;
BA_ "GenSigTimeoutTime_EVCU2" SG_ 1032 EOPB_OIL_FlwRate 0;
BA_ "GenSigTimeoutTime_MCPA" SG_ 1032 EOPB_OIL_FlwRate 0;
BA_ "GenSigTimeoutTime_SGCP" SG_ 1032 EOPB_OIL_FlwRate 0;
BA_ "GenSigTimeoutTime_TCM" SG_ 1032 EOPB_OIL_FlwRate 0;
BA_ "GenSigTimeoutTime_AGSM" SG_ 1032 EOPA_OIL_TEMP 0;
BA_ "GenSigTimeoutTime_ECM" SG_ 1032 EOPA_OIL_TEMP 0;
BA_ "GenSigTimeoutTime_EVCU2" SG_ 1032 EOPA_OIL_TEMP 0;
BA_ "GenSigTimeoutTime_MCPB" SG_ 1032 EOPA_OIL_TEMP 0;
BA_ "GenSigTimeoutTime_SGCP" SG_ 1032 EOPA_OIL_TEMP 0;
BA_ "GenSigTimeoutTime_TCM" SG_ 1032 EOPA_OIL_TEMP 0;
BA_ "GenSigTimeoutTime_AGSM" SG_ 1032 EOPA_OIL_FlwRate 0;
BA_ "GenSigTimeoutTime_ECM" SG_ 1032 EOPA_OIL_FlwRate 0;
BA_ "GenSigTimeoutTime_EVCU2" SG_ 1032 EOPA_OIL_FlwRate 0;
BA_ "GenSigTimeoutTime_MCPB" SG_ 1032 EOPA_OIL_FlwRate 0;
BA_ "GenSigTimeoutTime_SGCP" SG_ 1032 EOPA_OIL_FlwRate 0;
BA_ "GenSigTimeoutTime_TCM" SG_ 1032 EOPA_OIL_FlwRate 0;
BA_ "GenSigTimeoutTime_AGSM" SG_ 267 WU_Timer_Value 0;
BA_ "GenSigTimeoutTime_ECM" SG_ 267 WU_Timer_Value 0;
BA_ "GenSigTimeoutTime_EVCU2" SG_ 267 WU_Timer_Value 0;
BA_ "GenSigTimeoutTime_SGCP" SG_ 267 WU_Timer_Value 0;
BA_ "GenSigTimeoutTime_TCM" SG_ 267 WU_Timer_Value 0;
BA_ "GenSigTimeoutTime_AGSM" SG_ 267 PerWakeUp_Diag 0;
BA_ "GenSigTimeoutTime_ECM" SG_ 267 PerWakeUp_Diag 0;
BA_ "GenSigTimeoutTime_EVCU2" SG_ 267 PerWakeUp_Diag 0;
BA_ "GenSigTimeoutTime_SGCP" SG_ 267 PerWakeUp_Diag 0;
BA_ "GenSigTimeoutTime_TCM" SG_ 267 PerWakeUp_Diag 0;
BA_ "GenSigStartValue" SG_ 1033 IdleCLoopTrq 511;
BA_ "GenSigTimeoutTime_AGSM" SG_ 1033 IdleCLoopTrq 0;
BA_ "GenSigTimeoutTime_EVCU2" SG_ 1033 IdleCLoopTrq 0;
BA_ "GenSigTimeoutTime_MCPA" SG_ 1033 IdleCLoopTrq 0;
BA_ "GenSigTimeoutTime_MCPB" SG_ 1033 IdleCLoopTrq 0;
BA_ "GenSigTimeoutTime_SGCP" SG_ 1033 IdleCLoopTrq 0;
BA_ "GenSigTimeoutTime_TCM" SG_ 1033 IdleCLoopTrq 0;
BA_ "GenSigTimeoutTime_AGSM" SG_ 1033 HEV_HybPwrtrnRdcdPerfCmnd 0;
BA_ "GenSigTimeoutTime_EVCU2" SG_ 1033 HEV_HybPwrtrnRdcdPerfCmnd 0;
BA_ "GenSigTimeoutTime_MCPA" SG_ 1033 HEV_HybPwrtrnRdcdPerfCmnd 0;
BA_ "GenSigTimeoutTime_MCPB" SG_ 1033 HEV_HybPwrtrnRdcdPerfCmnd 0;
BA_ "GenSigTimeoutTime_SGCP" SG_ 1033 HEV_HybPwrtrnRdcdPerfCmnd 0;
BA_ "GenSigTimeoutTime_TCM" SG_ 1033 HEV_HybPwrtrnRdcdPerfCmnd 0;
BA_ "GenSigStartValue" SG_ 1033 HCPMaxEngRPM 255;
BA_ "GenSigTimeoutTime_AGSM" SG_ 1033 HCPMaxEngRPM 0;
BA_ "GenSigTimeoutTime_EVCU2" SG_ 1033 HCPMaxEngRPM 0;
BA_ "GenSigTimeoutTime_MCPA" SG_ 1033 HCPMaxEngRPM 0;
BA_ "GenSigTimeoutTime_MCPB" SG_ 1033 HCPMaxEngRPM 0;
BA_ "GenSigTimeoutTime_SGCP" SG_ 1033 HCPMaxEngRPM 0;
BA_ "GenSigTimeoutTime_TCM" SG_ 1033 HCPMaxEngRPM 0;
BA_ "GenSigTimeoutTime_AGSM" SG_ 1033 CRC_HYBRID_POWERTRAIN5 0;
BA_ "GenSigTimeoutTime_EVCU2" SG_ 1033 CRC_HYBRID_POWERTRAIN5 0;
BA_ "GenSigTimeoutTime_MCPA" SG_ 1033 CRC_HYBRID_POWERTRAIN5 0;
BA_ "GenSigTimeoutTime_MCPB" SG_ 1033 CRC_HYBRID_POWERTRAIN5 0;
BA_ "GenSigTimeoutTime_SGCP" SG_ 1033 CRC_HYBRID_POWERTRAIN5 0;
BA_ "GenSigTimeoutTime_TCM" SG_ 1033 CRC_HYBRID_POWERTRAIN5 0;
BA_ "GenSigTimeoutTime_AGSM" SG_ 1033 MessageCounter_HYBRID_POWERTRAIN 0;
BA_ "GenSigTimeoutTime_EVCU2" SG_ 1033 MessageCounter_HYBRID_POWERTRAIN 0;
BA_ "GenSigTimeoutTime_MCPA" SG_ 1033 MessageCounter_HYBRID_POWERTRAIN 0;
BA_ "GenSigTimeoutTime_MCPB" SG_ 1033 MessageCounter_HYBRID_POWERTRAIN 0;
BA_ "GenSigTimeoutTime_SGCP" SG_ 1033 MessageCounter_HYBRID_POWERTRAIN 0;
BA_ "GenSigTimeoutTime_TCM" SG_ 1033 MessageCounter_HYBRID_POWERTRAIN 0;
BA_ "SystemSignalLongSymbol" SG_ 1033 MessageCounter_HYBRID_POWERTRAIN "MessageCounter_HYBRID_POWERTRAIN5";
BA_ "GenSigTimeoutTime_AGSM" SG_ 1033 HCP_HoodAjar 0;
BA_ "GenSigTimeoutTime_EVCU2" SG_ 1033 HCP_HoodAjar 0;
BA_ "GenSigTimeoutTime_MCPA" SG_ 1033 HCP_HoodAjar 0;
BA_ "GenSigTimeoutTime_MCPB" SG_ 1033 HCP_HoodAjar 0;
BA_ "GenSigTimeoutTime_SGCP" SG_ 1033 HCP_HoodAjar 0;
BA_ "GenSigTimeoutTime_TCM" SG_ 1033 HCP_HoodAjar 0;
BA_ "GenSigStartValue" SG_ 1328 EngTorqCapbltyMinTorq 938;
BA_ "GenSigTimeoutTime_AGSM" SG_ 1328 EngTorqCapbltyMinTorq 0;
BA_ "GenSigTimeoutTime_ECM" SG_ 1328 EngTorqCapbltyMinTorq 0;
BA_ "GenSigTimeoutTime_MCPA" SG_ 1328 EngTorqCapbltyMinTorq 0;
BA_ "GenSigTimeoutTime_MCPB" SG_ 1328 EngTorqCapbltyMinTorq 0;
BA_ "GenSigTimeoutTime_SGCP" SG_ 1328 EngTorqCapbltyMinTorq 0;
BA_ "GenSigTimeoutTime_TCM" SG_ 1328 EngTorqCapbltyMinTorq 0;
BA_ "GenSigStartValue" SG_ 1328 EngTorqCapbltyMaxTorq 938;
BA_ "GenSigTimeoutTime_AGSM" SG_ 1328 EngTorqCapbltyMaxTorq 0;
BA_ "GenSigTimeoutTime_ECM" SG_ 1328 EngTorqCapbltyMaxTorq 0;
BA_ "GenSigTimeoutTime_MCPA" SG_ 1328 EngTorqCapbltyMaxTorq 0;
BA_ "GenSigTimeoutTime_MCPB" SG_ 1328 EngTorqCapbltyMaxTorq 0;
BA_ "GenSigTimeoutTime_SGCP" SG_ 1328 EngTorqCapbltyMaxTorq 0;
BA_ "GenSigTimeoutTime_TCM" SG_ 1328 EngTorqCapbltyMaxTorq 0;
BA_ "GenSigTimeoutTime_AGSM" SG_ 1328 EngTorqCapbltyMaxOffTorq 0;
BA_ "GenSigTimeoutTime_ECM" SG_ 1328 EngTorqCapbltyMaxOffTorq 0;
BA_ "GenSigTimeoutTime_MCPA" SG_ 1328 EngTorqCapbltyMaxOffTorq 0;
BA_ "GenSigTimeoutTime_MCPB" SG_ 1328 EngTorqCapbltyMaxOffTorq 0;
BA_ "GenSigTimeoutTime_SGCP" SG_ 1328 EngTorqCapbltyMaxOffTorq 0;
BA_ "GenSigTimeoutTime_TCM" SG_ 1328 EngTorqCapbltyMaxOffTorq 0;
BA_ "GenSigTimeoutTime_AGSM" SG_ 1328 EngTorqCapbltyRefEngSpd 0;
BA_ "GenSigTimeoutTime_ECM" SG_ 1328 EngTorqCapbltyRefEngSpd 0;
BA_ "GenSigTimeoutTime_MCPA" SG_ 1328 EngTorqCapbltyRefEngSpd 0;
BA_ "GenSigTimeoutTime_MCPB" SG_ 1328 EngTorqCapbltyRefEngSpd 0;
BA_ "GenSigTimeoutTime_SGCP" SG_ 1328 EngTorqCapbltyRefEngSpd 0;
BA_ "GenSigTimeoutTime_TCM" SG_ 1328 EngTorqCapbltyRefEngSpd 0;
BA_ "GenSigStartValue" SG_ 1328 EngTorqCapbltyMinRunTorq 938;
BA_ "GenSigTimeoutTime_AGSM" SG_ 1328 EngTorqCapbltyMinRunTorq 0;
BA_ "GenSigTimeoutTime_ECM" SG_ 1328 EngTorqCapbltyMinRunTorq 0;
BA_ "GenSigTimeoutTime_MCPA" SG_ 1328 EngTorqCapbltyMinRunTorq 0;
BA_ "GenSigTimeoutTime_MCPB" SG_ 1328 EngTorqCapbltyMinRunTorq 0;
BA_ "GenSigTimeoutTime_SGCP" SG_ 1328 EngTorqCapbltyMinRunTorq 0;
BA_ "GenSigTimeoutTime_TCM" SG_ 1328 EngTorqCapbltyMinRunTorq 0;
BA_ "GenSigTimeoutTime_AGSM" SG_ 1328 EngTorqCapbltyFrmCntr 0;
BA_ "GenSigTimeoutTime_ECM" SG_ 1328 EngTorqCapbltyFrmCntr 0;
BA_ "GenSigTimeoutTime_MCPA" SG_ 1328 EngTorqCapbltyFrmCntr 0;
BA_ "GenSigTimeoutTime_MCPB" SG_ 1328 EngTorqCapbltyFrmCntr 0;
BA_ "GenSigTimeoutTime_SGCP" SG_ 1328 EngTorqCapbltyFrmCntr 0;
BA_ "GenSigTimeoutTime_TCM" SG_ 1328 EngTorqCapbltyFrmCntr 0;
BA_ "GenSigTimeoutTime_AGSM" SG_ 1328 EngTorqCapbltyEngOpMd 0;
BA_ "GenSigTimeoutTime_ECM" SG_ 1328 EngTorqCapbltyEngOpMd 0;
BA_ "GenSigTimeoutTime_MCPA" SG_ 1328 EngTorqCapbltyEngOpMd 0;
BA_ "GenSigTimeoutTime_MCPB" SG_ 1328 EngTorqCapbltyEngOpMd 0;
BA_ "GenSigTimeoutTime_SGCP" SG_ 1328 EngTorqCapbltyEngOpMd 0;
BA_ "GenSigTimeoutTime_TCM" SG_ 1328 EngTorqCapbltyEngOpMd 0;
BA_ "GenSigTimeoutTime_AGSM" SG_ 1328 EngTorqACCCapability 0;
BA_ "GenSigTimeoutTime_ECM" SG_ 1328 EngTorqACCCapability 0;
BA_ "GenSigTimeoutTime_MCPA" SG_ 1328 EngTorqACCCapability 0;
BA_ "GenSigTimeoutTime_MCPB" SG_ 1328 EngTorqACCCapability 0;
BA_ "GenSigTimeoutTime_SGCP" SG_ 1328 EngTorqACCCapability 0;
BA_ "GenSigTimeoutTime_TCM" SG_ 1328 EngTorqACCCapability 0;
BA_ "GenSigTimeoutTime_AGSM" SG_ 1328 MessageCounter_ENGINE_HYBD_FD_4 0;
BA_ "GenSigTimeoutTime_ECM" SG_ 1328 MessageCounter_ENGINE_HYBD_FD_4 0;
BA_ "GenSigTimeoutTime_MCPA" SG_ 1328 MessageCounter_ENGINE_HYBD_FD_4 0;
BA_ "GenSigTimeoutTime_MCPB" SG_ 1328 MessageCounter_ENGINE_HYBD_FD_4 0;
BA_ "GenSigTimeoutTime_SGCP" SG_ 1328 MessageCounter_ENGINE_HYBD_FD_4 0;
BA_ "GenSigTimeoutTime_TCM" SG_ 1328 MessageCounter_ENGINE_HYBD_FD_4 0;
BA_ "GenSigTimeoutTime_AGSM" SG_ 1328 CRC_ENGINE_HYBD_FD_4 0;
BA_ "GenSigTimeoutTime_ECM" SG_ 1328 CRC_ENGINE_HYBD_FD_4 0;
BA_ "GenSigTimeoutTime_MCPA" SG_ 1328 CRC_ENGINE_HYBD_FD_4 0;
BA_ "GenSigTimeoutTime_MCPB" SG_ 1328 CRC_ENGINE_HYBD_FD_4 0;
BA_ "GenSigTimeoutTime_SGCP" SG_ 1328 CRC_ENGINE_HYBD_FD_4 0;
BA_ "GenSigTimeoutTime_TCM" SG_ 1328 CRC_ENGINE_HYBD_FD_4 0;
BA_ "GenSigTimeoutTime_AGSM" SG_ 1035 MaxEngSpdCap 0;
BA_ "GenSigTimeoutTime_ECM" SG_ 1035 MaxEngSpdCap 0;
BA_ "GenSigTimeoutTime_MCPA" SG_ 1035 MaxEngSpdCap 0;
BA_ "GenSigTimeoutTime_MCPB" SG_ 1035 MaxEngSpdCap 0;
BA_ "GenSigTimeoutTime_SGCP" SG_ 1035 MaxEngSpdCap 0;
BA_ "GenSigTimeoutTime_TCM" SG_ 1035 MaxEngSpdCap 0;
BA_ "GenSigTimeoutTime_AGSM" SG_ 1035 ServiceHybSys 0;
BA_ "GenSigTimeoutTime_ECM" SG_ 1035 ServiceHybSys 0;
BA_ "GenSigTimeoutTime_MCPA" SG_ 1035 ServiceHybSys 0;
BA_ "GenSigTimeoutTime_MCPB" SG_ 1035 ServiceHybSys 0;
BA_ "GenSigTimeoutTime_SGCP" SG_ 1035 ServiceHybSys 0;
BA_ "GenSigTimeoutTime_TCM" SG_ 1035 ServiceHybSys 0;
BA_ "GenSigTimeoutTime_AGSM" SG_ 1035 MinEngSpdCap 0;
BA_ "GenSigTimeoutTime_ECM" SG_ 1035 MinEngSpdCap 0;
BA_ "GenSigTimeoutTime_MCPA" SG_ 1035 MinEngSpdCap 0;
BA_ "GenSigTimeoutTime_MCPB" SG_ 1035 MinEngSpdCap 0;
BA_ "GenSigTimeoutTime_SGCP" SG_ 1035 MinEngSpdCap 0;
BA_ "GenSigTimeoutTime_TCM" SG_ 1035 MinEngSpdCap 0;
BA_ "GenSigTimeoutTime_AGSM" SG_ 1035 EngSpd 0;
BA_ "GenSigTimeoutTime_ECM" SG_ 1035 EngSpd 0;
BA_ "GenSigTimeoutTime_MCPA" SG_ 1035 EngSpd 0;
BA_ "GenSigTimeoutTime_MCPB" SG_ 1035 EngSpd 0;
BA_ "GenSigTimeoutTime_SGCP" SG_ 1035 EngSpd 0;
BA_ "GenSigTimeoutTime_TCM" SG_ 1035 EngSpd 0;
BA_ "GenSigTimeoutTime_AGSM" SG_ 1035 EngCltTmpV 0;
BA_ "GenSigTimeoutTime_ECM" SG_ 1035 EngCltTmpV 0;
BA_ "GenSigTimeoutTime_MCPA" SG_ 1035 EngCltTmpV 0;
BA_ "GenSigTimeoutTime_MCPB" SG_ 1035 EngCltTmpV 0;
BA_ "GenSigTimeoutTime_SGCP" SG_ 1035 EngCltTmpV 0;
BA_ "GenSigTimeoutTime_TCM" SG_ 1035 EngCltTmpV 0;
BA_ "GenSigStartValue" SG_ 1035 EngCltTmp 255;
BA_ "GenSigTimeoutTime_AGSM" SG_ 1035 EngCltTmp 0;
BA_ "GenSigTimeoutTime_ECM" SG_ 1035 EngCltTmp 0;
BA_ "GenSigTimeoutTime_MCPA" SG_ 1035 EngCltTmp 0;
BA_ "GenSigTimeoutTime_MCPB" SG_ 1035 EngCltTmp 0;
BA_ "GenSigTimeoutTime_SGCP" SG_ 1035 EngCltTmp 0;
BA_ "GenSigTimeoutTime_TCM" SG_ 1035 EngCltTmp 0;
BA_ "GenSigTimeoutTime_AGSM" SG_ 1035 MessageCounter_ENGINE_HYBD_FD_3 0;
BA_ "GenSigTimeoutTime_ECM" SG_ 1035 MessageCounter_ENGINE_HYBD_FD_3 0;
BA_ "GenSigTimeoutTime_MCPA" SG_ 1035 MessageCounter_ENGINE_HYBD_FD_3 0;
BA_ "GenSigTimeoutTime_MCPB" SG_ 1035 MessageCounter_ENGINE_HYBD_FD_3 0;
BA_ "GenSigTimeoutTime_SGCP" SG_ 1035 MessageCounter_ENGINE_HYBD_FD_3 0;
BA_ "GenSigTimeoutTime_TCM" SG_ 1035 MessageCounter_ENGINE_HYBD_FD_3 0;
BA_ "GenSigTimeoutTime_AGSM" SG_ 1035 CRC_ENGINE_HYBD_FD_3 0;
BA_ "GenSigTimeoutTime_ECM" SG_ 1035 CRC_ENGINE_HYBD_FD_3 0;
BA_ "GenSigTimeoutTime_MCPA" SG_ 1035 CRC_ENGINE_HYBD_FD_3 0;
BA_ "GenSigTimeoutTime_MCPB" SG_ 1035 CRC_ENGINE_HYBD_FD_3 0;
BA_ "GenSigTimeoutTime_SGCP" SG_ 1035 CRC_ENGINE_HYBD_FD_3 0;
BA_ "GenSigTimeoutTime_TCM" SG_ 1035 CRC_ENGINE_HYBD_FD_3 0;
BA_ "GenSigSendType" SG_ 1036 CruiseControlSts 3;
BA_ "GenSigTimeoutTime_AGSM" SG_ 1036 CruiseControlSts 0;
BA_ "GenSigTimeoutTime_ECM" SG_ 1036 CruiseControlSts 0;
BA_ "GenSigTimeoutTime_EVCU2" SG_ 1036 CruiseControlSts 0;
BA_ "GenSigTimeoutTime_MCPA" SG_ 1036 CruiseControlSts 0;
BA_ "GenSigTimeoutTime_MCPB" SG_ 1036 CruiseControlSts 0;
BA_ "GenSigTimeoutTime_SGCP" SG_ 1036 CruiseControlSts 0;
BA_ "GenSigSendType" SG_ 1036 CruiseControlLampSts 3;
BA_ "GenSigTimeoutTime_AGSM" SG_ 1036 CruiseControlLampSts 0;
BA_ "GenSigTimeoutTime_ECM" SG_ 1036 CruiseControlLampSts 0;
BA_ "GenSigTimeoutTime_EVCU2" SG_ 1036 CruiseControlLampSts 0;
BA_ "GenSigTimeoutTime_MCPA" SG_ 1036 CruiseControlLampSts 0;
BA_ "GenSigTimeoutTime_MCPB" SG_ 1036 CruiseControlLampSts 0;
BA_ "GenSigTimeoutTime_SGCP" SG_ 1036 CruiseControlLampSts 0;
BA_ "GenSigTimeoutTime_AGSM" SG_ 1036 MessageCounter_ENGINE3 0;
BA_ "GenSigTimeoutTime_ECM" SG_ 1036 MessageCounter_ENGINE3 0;
BA_ "GenSigTimeoutTime_EVCU2" SG_ 1036 MessageCounter_ENGINE3 0;
BA_ "GenSigTimeoutTime_MCPA" SG_ 1036 MessageCounter_ENGINE3 0;
BA_ "GenSigTimeoutTime_MCPB" SG_ 1036 MessageCounter_ENGINE3 0;
BA_ "GenSigTimeoutTime_SGCP" SG_ 1036 MessageCounter_ENGINE3 0;
BA_ "GenSigTimeoutTime_AGSM" SG_ 1036 CRC_ENGINE3 0;
BA_ "GenSigTimeoutTime_ECM" SG_ 1036 CRC_ENGINE3 0;
BA_ "GenSigTimeoutTime_EVCU2" SG_ 1036 CRC_ENGINE3 0;
BA_ "GenSigTimeoutTime_MCPA" SG_ 1036 CRC_ENGINE3 0;
BA_ "GenSigTimeoutTime_MCPB" SG_ 1036 CRC_ENGINE3 0;
BA_ "GenSigTimeoutTime_SGCP" SG_ 1036 CRC_ENGINE3 0;
BA_ "GenSigStartValue" SG_ 1036 EngineOilTemperature 255;
BA_ "GenSigTimeoutTime_AGSM" SG_ 1036 EngineOilTemperature 0;
BA_ "GenSigTimeoutTime_ECM" SG_ 1036 EngineOilTemperature 0;
BA_ "GenSigTimeoutTime_EVCU2" SG_ 1036 EngineOilTemperature 0;
BA_ "GenSigTimeoutTime_MCPA" SG_ 1036 EngineOilTemperature 0;
BA_ "GenSigTimeoutTime_MCPB" SG_ 1036 EngineOilTemperature 0;
BA_ "GenSigTimeoutTime_SGCP" SG_ 1036 EngineOilTemperature 0;
BA_ "GenSigTimeoutTime_AGSM" SG_ 278 TransmissionSailingSts 0;
BA_ "GenSigTimeoutTime_ECM" SG_ 278 TransmissionSailingSts 0;
BA_ "GenSigTimeoutTime_EVCU2" SG_ 278 TransmissionSailingSts 0;
BA_ "GenSigTimeoutTime_MCPA" SG_ 278 TransmissionSailingSts 0;
BA_ "GenSigTimeoutTime_MCPB" SG_ 278 TransmissionSailingSts 0;
BA_ "GenSigTimeoutTime_TCM" SG_ 278 TransmissionSailingSts 0;
BA_ "GenSigTimeoutTime_AGSM" SG_ 278 TransLosses 0;
BA_ "GenSigTimeoutTime_EVCU2" SG_ 278 TransLosses 0;
BA_ "GenSigTimeoutTime_MCPA" SG_ 278 TransLosses 0;
BA_ "GenSigTimeoutTime_MCPB" SG_ 278 TransLosses 0;
BA_ "GenSigTimeoutTime_SGCP" SG_ 278 TransLosses 0;
BA_ "GenSigTimeoutTime_TCM" SG_ 278 TransLosses 0;
BA_ "GenSigTimeoutTime_AGSM" SG_ 278 TorqueConverterSts 0;
BA_ "GenSigTimeoutTime_EVCU2" SG_ 278 TorqueConverterSts 0;
BA_ "GenSigTimeoutTime_MCPA" SG_ 278 TorqueConverterSts 0;
BA_ "GenSigTimeoutTime_MCPB" SG_ 278 TorqueConverterSts 0;
BA_ "GenSigTimeoutTime_SGCP" SG_ 278 TorqueConverterSts 0;
BA_ "GenSigTimeoutTime_TCM" SG_ 278 TorqueConverterSts 0;
BA_ "GenSigTimeoutTime_AGSM" SG_ 278 TorqueConverterSTO 0;
BA_ "GenSigTimeoutTime_EVCU2" SG_ 278 TorqueConverterSTO 0;
BA_ "GenSigTimeoutTime_MCPA" SG_ 278 TorqueConverterSTO 0;
BA_ "GenSigTimeoutTime_MCPB" SG_ 278 TorqueConverterSTO 0;
BA_ "GenSigTimeoutTime_SGCP" SG_ 278 TorqueConverterSTO 0;
BA_ "GenSigTimeoutTime_TCM" SG_ 278 TorqueConverterSTO 0;
BA_ "GenSigStartValue" SG_ 278 TargetGear 15;
BA_ "GenSigTimeoutTime_AGSM" SG_ 278 TargetGear 0;
BA_ "GenSigTimeoutTime_EVCU2" SG_ 278 TargetGear 0;
BA_ "GenSigTimeoutTime_MCPA" SG_ 278 TargetGear 0;
BA_ "GenSigTimeoutTime_MCPB" SG_ 278 TargetGear 0;
BA_ "GenSigTimeoutTime_SGCP" SG_ 278 TargetGear 0;
BA_ "GenSigTimeoutTime_TCM" SG_ 278 TargetGear 0;
BA_ "GenSigStartValue" SG_ 278 MaxTrqDes 2047;
BA_ "GenSigTimeoutTime_AGSM" SG_ 278 MaxTrqDes 0;
BA_ "GenSigTimeoutTime_EVCU2" SG_ 278 MaxTrqDes 0;
BA_ "GenSigTimeoutTime_MCPA" SG_ 278 MaxTrqDes 0;
BA_ "GenSigTimeoutTime_MCPB" SG_ 278 MaxTrqDes 0;
BA_ "GenSigTimeoutTime_SGCP" SG_ 278 MaxTrqDes 0;
BA_ "GenSigTimeoutTime_TCM" SG_ 278 MaxTrqDes 0;
BA_ "GenSigStartValue" SG_ 278 EngTrq_Rq_TCM 2047;
BA_ "GenSigTimeoutTime_AGSM" SG_ 278 EngTrq_Rq_TCM 0;
BA_ "GenSigTimeoutTime_EVCU2" SG_ 278 EngTrq_Rq_TCM 0;
BA_ "GenSigTimeoutTime_MCPA" SG_ 278 EngTrq_Rq_TCM 0;
BA_ "GenSigTimeoutTime_MCPB" SG_ 278 EngTrq_Rq_TCM 0;
BA_ "GenSigTimeoutTime_SGCP" SG_ 278 EngTrq_Rq_TCM 0;
BA_ "GenSigTimeoutTime_TCM" SG_ 278 EngTrq_Rq_TCM 0;
BA_ "GenSigTimeoutTime_ECM" SG_ 278 CRC_TRANSM1 0;
BA_ "GenSigTimeoutTime_AGSM" SG_ 278 CRC_TRANSM1 0;
BA_ "GenSigTimeoutTime_EVCU2" SG_ 278 CRC_TRANSM1 0;
BA_ "GenSigTimeoutTime_MCPA" SG_ 278 CRC_TRANSM1 0;
BA_ "GenSigTimeoutTime_MCPB" SG_ 278 CRC_TRANSM1 0;
BA_ "GenSigTimeoutTime_SGCP" SG_ 278 CRC_TRANSM1 0;
BA_ "GenSigTimeoutTime_TCM" SG_ 278 CRC_TRANSM1 0;
BA_ "GenSigTimeoutTime_AGSM" SG_ 278 REPRGD_PFC_CLR_TCM 0;
BA_ "GenSigTimeoutTime_EVCU2" SG_ 278 REPRGD_PFC_CLR_TCM 0;
BA_ "GenSigTimeoutTime_MCPA" SG_ 278 REPRGD_PFC_CLR_TCM 0;
BA_ "GenSigTimeoutTime_MCPB" SG_ 278 REPRGD_PFC_CLR_TCM 0;
BA_ "GenSigTimeoutTime_SGCP" SG_ 278 REPRGD_PFC_CLR_TCM 0;
BA_ "GenSigTimeoutTime_TCM" SG_ 278 REPRGD_PFC_CLR_TCM 0;
BA_ "GenSigTimeoutTime_AGSM" SG_ 278 PaddleShiftRequest 0;
BA_ "GenSigTimeoutTime_EVCU2" SG_ 278 PaddleShiftRequest 0;
BA_ "GenSigTimeoutTime_MCPA" SG_ 278 PaddleShiftRequest 0;
BA_ "GenSigTimeoutTime_MCPB" SG_ 278 PaddleShiftRequest 0;
BA_ "GenSigTimeoutTime_TCM" SG_ 278 PaddleShiftRequest 0;
BA_ "GenSigTimeoutTime_ECM" SG_ 278 MessageCounter_TRANSM1 0;
BA_ "GenSigTimeoutTime_AGSM" SG_ 278 MessageCounter_TRANSM1 0;
BA_ "GenSigTimeoutTime_EVCU2" SG_ 278 MessageCounter_TRANSM1 0;
BA_ "GenSigTimeoutTime_MCPA" SG_ 278 MessageCounter_TRANSM1 0;
BA_ "GenSigTimeoutTime_MCPB" SG_ 278 MessageCounter_TRANSM1 0;
BA_ "GenSigTimeoutTime_SGCP" SG_ 278 MessageCounter_TRANSM1 0;
BA_ "GenSigTimeoutTime_TCM" SG_ 278 MessageCounter_TRANSM1 0;
BA_ "GenSigTimeoutTime_AGSM" SG_ 278 DriveLineRatio 0;
BA_ "GenSigTimeoutTime_EVCU2" SG_ 278 DriveLineRatio 0;
BA_ "GenSigTimeoutTime_MCPA" SG_ 278 DriveLineRatio 0;
BA_ "GenSigTimeoutTime_MCPB" SG_ 278 DriveLineRatio 0;
BA_ "GenSigTimeoutTime_SGCP" SG_ 278 DriveLineRatio 0;
BA_ "GenSigTimeoutTime_TCM" SG_ 278 DriveLineRatio 0;
BA_ "GenSigTimeoutTime_AGSM" SG_ 278 CODE_CLR_TCM 0;
BA_ "GenSigTimeoutTime_EVCU2" SG_ 278 CODE_CLR_TCM 0;
BA_ "GenSigTimeoutTime_MCPA" SG_ 278 CODE_CLR_TCM 0;
BA_ "GenSigTimeoutTime_MCPB" SG_ 278 CODE_CLR_TCM 0;
BA_ "GenSigTimeoutTime_SGCP" SG_ 278 CODE_CLR_TCM 0;
BA_ "GenSigTimeoutTime_TCM" SG_ 278 CODE_CLR_TCM 0;
BA_ "GenSigTimeoutTime_AGSM" SG_ 278 TxIdleRq 0;
BA_ "GenSigTimeoutTime_EVCU2" SG_ 278 TxIdleRq 0;
BA_ "GenSigTimeoutTime_MCPA" SG_ 278 TxIdleRq 0;
BA_ "GenSigTimeoutTime_MCPB" SG_ 278 TxIdleRq 0;
BA_ "GenSigTimeoutTime_SGCP" SG_ 278 TxIdleRq 0;
BA_ "GenSigTimeoutTime_TCM" SG_ 278 TxIdleRq 0;
BA_ "GenSigTimeoutTime_AGSM" SG_ 278 TCASERANGESTATUS_TCM 0;
BA_ "GenSigTimeoutTime_EVCU2" SG_ 278 TCASERANGESTATUS_TCM 0;
BA_ "GenSigTimeoutTime_MCPA" SG_ 278 TCASERANGESTATUS_TCM 0;
BA_ "GenSigTimeoutTime_MCPB" SG_ 278 TCASERANGESTATUS_TCM 0;
BA_ "GenSigTimeoutTime_SGCP" SG_ 278 TCASERANGESTATUS_TCM 0;
BA_ "GenSigTimeoutTime_TCM" SG_ 278 TCASERANGESTATUS_TCM 0;
BA_ "GenSigTimeoutTime_AGSM" SG_ 278 Trans_Adapt_Status 0;
BA_ "GenSigTimeoutTime_EVCU2" SG_ 278 Trans_Adapt_Status 0;
BA_ "GenSigTimeoutTime_MCPA" SG_ 278 Trans_Adapt_Status 0;
BA_ "GenSigTimeoutTime_MCPB" SG_ 278 Trans_Adapt_Status 0;
BA_ "GenSigTimeoutTime_SGCP" SG_ 278 Trans_Adapt_Status 0;
BA_ "GenSigTimeoutTime_TCM" SG_ 278 Trans_Adapt_Status 0;
BA_ "GenSigTimeoutTime_AGSM" SG_ 278 TorqueAmpTransmission 0;
BA_ "GenSigTimeoutTime_EVCU2" SG_ 278 TorqueAmpTransmission 0;
BA_ "GenSigTimeoutTime_MCPA" SG_ 278 TorqueAmpTransmission 0;
BA_ "GenSigTimeoutTime_MCPB" SG_ 278 TorqueAmpTransmission 0;
BA_ "GenSigTimeoutTime_SGCP" SG_ 278 TorqueAmpTransmission 0;
BA_ "GenSigTimeoutTime_TCM" SG_ 278 TorqueAmpTransmission 0;
BA_ "GenSigTimeoutTime_AGSM" SG_ 278 TrqCtrlModeReq 0;
BA_ "GenSigTimeoutTime_EVCU2" SG_ 278 TrqCtrlModeReq 0;
BA_ "GenSigTimeoutTime_MCPA" SG_ 278 TrqCtrlModeReq 0;
BA_ "GenSigTimeoutTime_MCPB" SG_ 278 TrqCtrlModeReq 0;
BA_ "GenSigTimeoutTime_SGCP" SG_ 278 TrqCtrlModeReq 0;
BA_ "GenSigTimeoutTime_TCM" SG_ 278 TrqCtrlModeReq 0;
BA_ "GenSigStartValue" SG_ 278 TransIntakeTorq 1000;
BA_ "GenSigTimeoutTime_AGSM" SG_ 278 TransIntakeTorq 0;
BA_ "GenSigTimeoutTime_EVCU2" SG_ 278 TransIntakeTorq 0;
BA_ "GenSigTimeoutTime_MCPA" SG_ 278 TransIntakeTorq 0;
BA_ "GenSigTimeoutTime_MCPB" SG_ 278 TransIntakeTorq 0;
BA_ "GenSigTimeoutTime_SGCP" SG_ 278 TransIntakeTorq 0;
BA_ "GenSigTimeoutTime_TCM" SG_ 278 TransIntakeTorq 0;
BA_ "GenSigTimeoutTime_MCPB" SG_ 278 CrankEnable_Fast 0;
BA_ "GenSigTimeoutTime_SGCP" SG_ 278 CrankEnable_Fast 0;
BA_ "GenSigTimeoutTime_TCM" SG_ 278 CrankEnable_Fast 0;
BA_ "GenSigTimeoutTime_AGSM" SG_ 278 CrankEnable_Fast 0;
BA_ "GenSigTimeoutTime_EVCU2" SG_ 278 CrankEnable_Fast 0;
BA_ "GenSigTimeoutTime_MCPA" SG_ 278 CrankEnable_Fast 0;
BA_ "GenSigStartValue" SG_ 278 EngTrq_Rq_TCM_Prdtd 2047;
BA_ "GenSigTimeoutTime_AGSM" SG_ 278 EngTrq_Rq_TCM_Prdtd 0;
BA_ "GenSigTimeoutTime_EVCU2" SG_ 278 EngTrq_Rq_TCM_Prdtd 0;
BA_ "GenSigTimeoutTime_MCPA" SG_ 278 EngTrq_Rq_TCM_Prdtd 0;
BA_ "GenSigTimeoutTime_MCPB" SG_ 278 EngTrq_Rq_TCM_Prdtd 0;
BA_ "GenSigTimeoutTime_SGCP" SG_ 278 EngTrq_Rq_TCM_Prdtd 0;
BA_ "GenSigTimeoutTime_TCM" SG_ 278 EngTrq_Rq_TCM_Prdtd 0;
BA_ "GenSigStartValue" SG_ 278 PumpTrqOnImpShaft 512;
BA_ "GenSigTimeoutTime_AGSM" SG_ 278 PumpTrqOnImpShaft 0;
BA_ "GenSigTimeoutTime_EVCU2" SG_ 278 PumpTrqOnImpShaft 0;
BA_ "GenSigTimeoutTime_MCPA" SG_ 278 PumpTrqOnImpShaft 0;
BA_ "GenSigTimeoutTime_MCPB" SG_ 278 PumpTrqOnImpShaft 0;
BA_ "GenSigTimeoutTime_SGCP" SG_ 278 PumpTrqOnImpShaft 0;
BA_ "GenSigTimeoutTime_TCM" SG_ 278 PumpTrqOnImpShaft 0;
BA_ "GenSigTimeoutTime_AGSM" SG_ 269 IdleSpeedActiveSts 0;
BA_ "GenSigTimeoutTime_EVCU2" SG_ 269 IdleSpeedActiveSts 0;
BA_ "GenSigTimeoutTime_MCPA" SG_ 269 IdleSpeedActiveSts 0;
BA_ "GenSigTimeoutTime_MCPB" SG_ 269 IdleSpeedActiveSts 0;
BA_ "GenSigTimeoutTime_SGCP" SG_ 269 IdleSpeedActiveSts 0;
BA_ "GenSigTimeoutTime_TCM" SG_ 269 IdleSpeedActiveSts 0;
BA_ "GenSigTimeoutTime_AGSM" SG_ 269 CRC_HYBRID_POWERTRAIN2 0;
BA_ "GenSigTimeoutTime_EVCU2" SG_ 269 CRC_HYBRID_POWERTRAIN2 0;
BA_ "GenSigTimeoutTime_MCPA" SG_ 269 CRC_HYBRID_POWERTRAIN2 0;
BA_ "GenSigTimeoutTime_MCPB" SG_ 269 CRC_HYBRID_POWERTRAIN2 0;
BA_ "GenSigTimeoutTime_SGCP" SG_ 269 CRC_HYBRID_POWERTRAIN2 0;
BA_ "GenSigTimeoutTime_TCM" SG_ 269 CRC_HYBRID_POWERTRAIN2 0;
BA_ "GenSigTimeoutTime_AGSM" SG_ 269 PropulsionMode 0;
BA_ "GenSigTimeoutTime_EVCU2" SG_ 269 PropulsionMode 0;
BA_ "GenSigTimeoutTime_MCPA" SG_ 269 PropulsionMode 0;
BA_ "GenSigTimeoutTime_MCPB" SG_ 269 PropulsionMode 0;
BA_ "GenSigTimeoutTime_SGCP" SG_ 269 PropulsionMode 0;
BA_ "GenSigTimeoutTime_TCM" SG_ 269 PropulsionMode 0;
BA_ "GenSigStartValue" SG_ 269 HybridEngineMaxTorqAllowed 938;
BA_ "GenSigTimeoutTime_AGSM" SG_ 269 HybridEngineMaxTorqAllowed 0;
BA_ "GenSigTimeoutTime_EVCU2" SG_ 269 HybridEngineMaxTorqAllowed 0;
BA_ "GenSigTimeoutTime_MCPA" SG_ 269 HybridEngineMaxTorqAllowed 0;
BA_ "GenSigTimeoutTime_MCPB" SG_ 269 HybridEngineMaxTorqAllowed 0;
BA_ "GenSigTimeoutTime_SGCP" SG_ 269 HybridEngineMaxTorqAllowed 0;
BA_ "GenSigTimeoutTime_TCM" SG_ 269 HybridEngineMaxTorqAllowed 0;
BA_ "GenSigTimeoutTime_AGSM" SG_ 269 MessageCounter_HYBRID_POWER_0000 0;
BA_ "GenSigTimeoutTime_EVCU2" SG_ 269 MessageCounter_HYBRID_POWER_0000 0;
BA_ "GenSigTimeoutTime_MCPA" SG_ 269 MessageCounter_HYBRID_POWER_0000 0;
BA_ "GenSigTimeoutTime_MCPB" SG_ 269 MessageCounter_HYBRID_POWER_0000 0;
BA_ "GenSigTimeoutTime_SGCP" SG_ 269 MessageCounter_HYBRID_POWER_0000 0;
BA_ "GenSigTimeoutTime_TCM" SG_ 269 MessageCounter_HYBRID_POWER_0000 0;
BA_ "SystemSignalLongSymbol" SG_ 269 MessageCounter_HYBRID_POWER_0000 "MessageCounter_HYBRID_POWERTRAIN2";
BA_ "GenSigTimeoutTime_AGSM" SG_ 276 TransInpSpdPrfl 0;
BA_ "GenSigTimeoutTime_EVCU2" SG_ 276 TransInpSpdPrfl 0;
BA_ "GenSigTimeoutTime_MCPA" SG_ 276 TransInpSpdPrfl 0;
BA_ "GenSigTimeoutTime_MCPB" SG_ 276 TransInpSpdPrfl 0;
BA_ "GenSigTimeoutTime_SGCP" SG_ 276 TransInpSpdPrfl 0;
BA_ "GenSigTimeoutTime_TCM" SG_ 276 TransInpSpdPrfl 0;
BA_ "GenSigTimeoutTime_AGSM" SG_ 276 InputSpdRaw 0;
BA_ "GenSigTimeoutTime_EVCU2" SG_ 276 InputSpdRaw 0;
BA_ "GenSigTimeoutTime_MCPA" SG_ 276 InputSpdRaw 0;
BA_ "GenSigTimeoutTime_MCPB" SG_ 276 InputSpdRaw 0;
BA_ "GenSigTimeoutTime_SGCP" SG_ 276 InputSpdRaw 0;
BA_ "GenSigTimeoutTime_TCM" SG_ 276 InputSpdRaw 0;
BA_ "GenSigTimeoutTime_AGSM" SG_ 276 Hybrid_Remedial_Stop 0;
BA_ "GenSigTimeoutTime_EVCU2" SG_ 276 Hybrid_Remedial_Stop 0;
BA_ "GenSigTimeoutTime_MCPA" SG_ 276 Hybrid_Remedial_Stop 0;
BA_ "GenSigTimeoutTime_MCPB" SG_ 276 Hybrid_Remedial_Stop 0;
BA_ "GenSigTimeoutTime_SGCP" SG_ 276 Hybrid_Remedial_Stop 0;
BA_ "GenSigTimeoutTime_TCM" SG_ 276 Hybrid_Remedial_Stop 0;
BA_ "GenSigTimeoutTime_AGSM" SG_ 276 HybFeedback_Engine 0;
BA_ "GenSigTimeoutTime_EVCU2" SG_ 276 HybFeedback_Engine 0;
BA_ "GenSigTimeoutTime_MCPA" SG_ 276 HybFeedback_Engine 0;
BA_ "GenSigTimeoutTime_MCPB" SG_ 276 HybFeedback_Engine 0;
BA_ "GenSigTimeoutTime_SGCP" SG_ 276 HybFeedback_Engine 0;
BA_ "GenSigTimeoutTime_TCM" SG_ 276 HybFeedback_Engine 0;
BA_ "GenSigTimeoutTime_AGSM" SG_ 276 HybEstEngTorqV 0;
BA_ "GenSigTimeoutTime_MCPA" SG_ 276 HybEstEngTorqV 0;
BA_ "GenSigTimeoutTime_MCPB" SG_ 276 HybEstEngTorqV 0;
BA_ "GenSigTimeoutTime_SGCP" SG_ 276 HybEstEngTorqV 0;
BA_ "GenSigTimeoutTime_TCM" SG_ 276 HybEstEngTorqV 0;
BA_ "GenSigStartValue" SG_ 276 HybEstEngTorq 938;
BA_ "GenSigTimeoutTime_AGSM" SG_ 276 HybEstEngTorq 0;
BA_ "GenSigTimeoutTime_MCPA" SG_ 276 HybEstEngTorq 0;
BA_ "GenSigTimeoutTime_MCPB" SG_ 276 HybEstEngTorq 0;
BA_ "GenSigTimeoutTime_SGCP" SG_ 276 HybEstEngTorq 0;
BA_ "GenSigTimeoutTime_TCM" SG_ 276 HybEstEngTorq 0;
BA_ "GenSigTimeoutTime_AGSM" SG_ 276 HybCrnkAbrted 0;
BA_ "GenSigTimeoutTime_EVCU2" SG_ 276 HybCrnkAbrted 0;
BA_ "GenSigTimeoutTime_MCPA" SG_ 276 HybCrnkAbrted 0;
BA_ "GenSigTimeoutTime_MCPB" SG_ 276 HybCrnkAbrted 0;
BA_ "GenSigTimeoutTime_SGCP" SG_ 276 HybCrnkAbrted 0;
BA_ "GenSigTimeoutTime_TCM" SG_ 276 HybCrnkAbrted 0;
BA_ "GenSigTimeoutTime_AGSM" SG_ 276 HybCmndEngTorqRespTyp 0;
BA_ "GenSigTimeoutTime_EVCU2" SG_ 276 HybCmndEngTorqRespTyp 0;
BA_ "GenSigTimeoutTime_MCPA" SG_ 276 HybCmndEngTorqRespTyp 0;
BA_ "GenSigTimeoutTime_MCPB" SG_ 276 HybCmndEngTorqRespTyp 0;
BA_ "GenSigTimeoutTime_SGCP" SG_ 276 HybCmndEngTorqRespTyp 0;
BA_ "GenSigTimeoutTime_TCM" SG_ 276 HybCmndEngTorqRespTyp 0;
BA_ "GenSigStartValue" SG_ 276 HybCmndEngTorqPrdtd 938;
BA_ "GenSigTimeoutTime_AGSM" SG_ 276 HybCmndEngTorqPrdtd 0;
BA_ "GenSigTimeoutTime_EVCU2" SG_ 276 HybCmndEngTorqPrdtd 0;
BA_ "GenSigTimeoutTime_MCPA" SG_ 276 HybCmndEngTorqPrdtd 0;
BA_ "GenSigTimeoutTime_MCPB" SG_ 276 HybCmndEngTorqPrdtd 0;
BA_ "GenSigTimeoutTime_SGCP" SG_ 276 HybCmndEngTorqPrdtd 0;
BA_ "GenSigTimeoutTime_TCM" SG_ 276 HybCmndEngTorqPrdtd 0;
BA_ "GenSigTimeoutTime_AGSM" SG_ 276 HybCmndEngTorqImmed 0;
BA_ "GenSigTimeoutTime_EVCU2" SG_ 276 HybCmndEngTorqImmed 0;
BA_ "GenSigTimeoutTime_MCPA" SG_ 276 HybCmndEngTorqImmed 0;
BA_ "GenSigTimeoutTime_MCPB" SG_ 276 HybCmndEngTorqImmed 0;
BA_ "GenSigTimeoutTime_SGCP" SG_ 276 HybCmndEngTorqImmed 0;
BA_ "GenSigTimeoutTime_TCM" SG_ 276 HybCmndEngTorqImmed 0;
BA_ "GenSigStartValue" SG_ 276 HybCmndEngTorqImmed 938;
BA_ "GenSigTimeoutTime_AGSM" SG_ 276 EngTrqReserveCmd 0;
BA_ "GenSigTimeoutTime_EVCU2" SG_ 276 EngTrqReserveCmd 0;
BA_ "GenSigTimeoutTime_MCPA" SG_ 276 EngTrqReserveCmd 0;
BA_ "GenSigTimeoutTime_MCPB" SG_ 276 EngTrqReserveCmd 0;
BA_ "GenSigTimeoutTime_SGCP" SG_ 276 EngTrqReserveCmd 0;
BA_ "GenSigTimeoutTime_TCM" SG_ 276 EngTrqReserveCmd 0;
BA_ "GenSigTimeoutTime_AGSM" SG_ 276 EngCntrlMode 0;
BA_ "GenSigTimeoutTime_EVCU2" SG_ 276 EngCntrlMode 0;
BA_ "GenSigTimeoutTime_MCPA" SG_ 276 EngCntrlMode 0;
BA_ "GenSigTimeoutTime_MCPB" SG_ 276 EngCntrlMode 0;
BA_ "GenSigTimeoutTime_SGCP" SG_ 276 EngCntrlMode 0;
BA_ "GenSigTimeoutTime_TCM" SG_ 276 EngCntrlMode 0;
BA_ "GenSigTimeoutTime_AGSM" SG_ 276 ECMPrepIdleRes 0;
BA_ "GenSigTimeoutTime_EVCU2" SG_ 276 ECMPrepIdleRes 0;
BA_ "GenSigTimeoutTime_MCPA" SG_ 276 ECMPrepIdleRes 0;
BA_ "GenSigTimeoutTime_MCPB" SG_ 276 ECMPrepIdleRes 0;
BA_ "GenSigTimeoutTime_SGCP" SG_ 276 ECMPrepIdleRes 0;
BA_ "GenSigTimeoutTime_TCM" SG_ 276 ECMPrepIdleRes 0;
BA_ "GenSigTimeoutTime_AGSM" SG_ 276 CRC_HYBRID_POWERTRAIN1 0;
BA_ "GenSigTimeoutTime_EVCU2" SG_ 276 CRC_HYBRID_POWERTRAIN1 0;
BA_ "GenSigTimeoutTime_MCPA" SG_ 276 CRC_HYBRID_POWERTRAIN1 0;
BA_ "GenSigTimeoutTime_MCPB" SG_ 276 CRC_HYBRID_POWERTRAIN1 0;
BA_ "GenSigTimeoutTime_SGCP" SG_ 276 CRC_HYBRID_POWERTRAIN1 0;
BA_ "GenSigTimeoutTime_TCM" SG_ 276 CRC_HYBRID_POWERTRAIN1 0;
BA_ "GenSigTimeoutTime_AGSM" SG_ 276 PropulsionSystemActive 0;
BA_ "GenSigTimeoutTime_EVCU2" SG_ 276 PropulsionSystemActive 0;
BA_ "GenSigTimeoutTime_MCPA" SG_ 276 PropulsionSystemActive 0;
BA_ "GenSigTimeoutTime_MCPB" SG_ 276 PropulsionSystemActive 0;
BA_ "GenSigTimeoutTime_SGCP" SG_ 276 PropulsionSystemActive 0;
BA_ "GenSigTimeoutTime_TCM" SG_ 276 PropulsionSystemActive 0;
BA_ "GenSigTimeoutTime_AGSM" SG_ 276 MessageCounter_HYBRID_POWER_0001 0;
BA_ "GenSigTimeoutTime_EVCU2" SG_ 276 MessageCounter_HYBRID_POWER_0001 0;
BA_ "GenSigTimeoutTime_MCPA" SG_ 276 MessageCounter_HYBRID_POWER_0001 0;
BA_ "GenSigTimeoutTime_MCPB" SG_ 276 MessageCounter_HYBRID_POWER_0001 0;
BA_ "GenSigTimeoutTime_SGCP" SG_ 276 MessageCounter_HYBRID_POWER_0001 0;
BA_ "GenSigTimeoutTime_TCM" SG_ 276 MessageCounter_HYBRID_POWER_0001 0;
BA_ "SystemSignalLongSymbol" SG_ 276 MessageCounter_HYBRID_POWER_0001 "MessageCounter_HYBRID_POWERTRAIN1";
BA_ "GenSigStartValue" SG_ 271 Sum_FW_ID_Slw 1;
BA_ "GenSigTimeoutTime_AGSM" SG_ 271 Sum_FW_ID_Slw 0;
BA_ "GenSigTimeoutTime_ECM" SG_ 271 Sum_FW_ID_Slw 0;
BA_ "GenSigTimeoutTime_MCPA" SG_ 271 Sum_FW_ID_Slw 0;
BA_ "GenSigTimeoutTime_MCPB" SG_ 271 Sum_FW_ID_Slw 0;
BA_ "GenSigTimeoutTime_SGCP" SG_ 271 Sum_FW_ID_Slw 0;
BA_ "GenSigTimeoutTime_TCM" SG_ 271 Sum_FW_ID_Slw 0;
BA_ "GenSigStartValue" SG_ 271 Sum_FW_ID_Fst 1;
BA_ "GenSigTimeoutTime_AGSM" SG_ 271 Sum_FW_ID_Fst 0;
BA_ "GenSigTimeoutTime_ECM" SG_ 271 Sum_FW_ID_Fst 0;
BA_ "GenSigTimeoutTime_MCPA" SG_ 271 Sum_FW_ID_Fst 0;
BA_ "GenSigTimeoutTime_MCPB" SG_ 271 Sum_FW_ID_Fst 0;
BA_ "GenSigTimeoutTime_SGCP" SG_ 271 Sum_FW_ID_Fst 0;
BA_ "GenSigTimeoutTime_TCM" SG_ 271 Sum_FW_ID_Fst 0;
BA_ "GenSigTimeoutTime_AGSM" SG_ 271 MinPrdtdEngRunTorqCapV 0;
BA_ "GenSigTimeoutTime_ECM" SG_ 271 MinPrdtdEngRunTorqCapV 0;
BA_ "GenSigTimeoutTime_MCPA" SG_ 271 MinPrdtdEngRunTorqCapV 0;
BA_ "GenSigTimeoutTime_MCPB" SG_ 271 MinPrdtdEngRunTorqCapV 0;
BA_ "GenSigTimeoutTime_SGCP" SG_ 271 MinPrdtdEngRunTorqCapV 0;
BA_ "GenSigTimeoutTime_TCM" SG_ 271 MinPrdtdEngRunTorqCapV 0;
BA_ "GenSigStartValue" SG_ 271 MinPrdtdEngRunTorqCap 938;
BA_ "GenSigTimeoutTime_AGSM" SG_ 271 MinPrdtdEngRunTorqCap 0;
BA_ "GenSigTimeoutTime_ECM" SG_ 271 MinPrdtdEngRunTorqCap 0;
BA_ "GenSigTimeoutTime_MCPA" SG_ 271 MinPrdtdEngRunTorqCap 0;
BA_ "GenSigTimeoutTime_MCPB" SG_ 271 MinPrdtdEngRunTorqCap 0;
BA_ "GenSigTimeoutTime_SGCP" SG_ 271 MinPrdtdEngRunTorqCap 0;
BA_ "GenSigTimeoutTime_TCM" SG_ 271 MinPrdtdEngRunTorqCap 0;
BA_ "GenSigTimeoutTime_EVCU2" SG_ 271 MinImmedEngTorqCapV 0;
BA_ "GenSigTimeoutTime_AGSM" SG_ 271 MinImmedEngTorqCapV 0;
BA_ "GenSigTimeoutTime_ECM" SG_ 271 MinImmedEngTorqCapV 0;
BA_ "GenSigTimeoutTime_MCPA" SG_ 271 MinImmedEngTorqCapV 0;
BA_ "GenSigTimeoutTime_MCPB" SG_ 271 MinImmedEngTorqCapV 0;
BA_ "GenSigTimeoutTime_SGCP" SG_ 271 MinImmedEngTorqCapV 0;
BA_ "GenSigTimeoutTime_EVCU2" SG_ 271 MinImmedEngTorqCap 0;
BA_ "GenSigStartValue" SG_ 271 MinImmedEngTorqCap 938;
BA_ "GenSigTimeoutTime_AGSM" SG_ 271 MinImmedEngTorqCap 0;
BA_ "GenSigTimeoutTime_ECM" SG_ 271 MinImmedEngTorqCap 0;
BA_ "GenSigTimeoutTime_MCPA" SG_ 271 MinImmedEngTorqCap 0;
BA_ "GenSigTimeoutTime_MCPB" SG_ 271 MinImmedEngTorqCap 0;
BA_ "GenSigTimeoutTime_SGCP" SG_ 271 MinImmedEngTorqCap 0;
BA_ "GenSigTimeoutTime_AGSM" SG_ 271 MinEngTorqCapV 0;
BA_ "GenSigTimeoutTime_ECM" SG_ 271 MinEngTorqCapV 0;
BA_ "GenSigTimeoutTime_MCPA" SG_ 271 MinEngTorqCapV 0;
BA_ "GenSigTimeoutTime_MCPB" SG_ 271 MinEngTorqCapV 0;
BA_ "GenSigTimeoutTime_SGCP" SG_ 271 MinEngTorqCapV 0;
BA_ "GenSigTimeoutTime_TCM" SG_ 271 MinEngTorqCapV 0;
BA_ "GenSigStartValue" SG_ 271 MinEngTorqCap 938;
BA_ "GenSigTimeoutTime_AGSM" SG_ 271 MinEngTorqCap 0;
BA_ "GenSigTimeoutTime_ECM" SG_ 271 MinEngTorqCap 0;
BA_ "GenSigTimeoutTime_MCPA" SG_ 271 MinEngTorqCap 0;
BA_ "GenSigTimeoutTime_MCPB" SG_ 271 MinEngTorqCap 0;
BA_ "GenSigTimeoutTime_SGCP" SG_ 271 MinEngTorqCap 0;
BA_ "GenSigTimeoutTime_TCM" SG_ 271 MinEngTorqCap 0;
BA_ "GenSigTimeoutTime_EVCU2" SG_ 271 MinAirFlowMinSparkTorqCapV 0;
BA_ "GenSigTimeoutTime_AGSM" SG_ 271 MinAirFlowMinSparkTorqCapV 0;
BA_ "GenSigTimeoutTime_ECM" SG_ 271 MinAirFlowMinSparkTorqCapV 0;
BA_ "GenSigTimeoutTime_MCPA" SG_ 271 MinAirFlowMinSparkTorqCapV 0;
BA_ "GenSigTimeoutTime_MCPB" SG_ 271 MinAirFlowMinSparkTorqCapV 0;
BA_ "GenSigTimeoutTime_SGCP" SG_ 271 MinAirFlowMinSparkTorqCapV 0;
BA_ "GenSigTimeoutTime_EVCU2" SG_ 271 MinAirFlowMinSparkTorqCap 0;
BA_ "GenSigStartValue" SG_ 271 MinAirFlowMinSparkTorqCap 938;
BA_ "GenSigTimeoutTime_AGSM" SG_ 271 MinAirFlowMinSparkTorqCap 0;
BA_ "GenSigTimeoutTime_ECM" SG_ 271 MinAirFlowMinSparkTorqCap 0;
BA_ "GenSigTimeoutTime_MCPA" SG_ 271 MinAirFlowMinSparkTorqCap 0;
BA_ "GenSigTimeoutTime_MCPB" SG_ 271 MinAirFlowMinSparkTorqCap 0;
BA_ "GenSigTimeoutTime_SGCP" SG_ 271 MinAirFlowMinSparkTorqCap 0;
BA_ "GenSigTimeoutTime_EVCU2" SG_ 271 MessageCounter_ENGINE_HYBD_FD_1 0;
BA_ "GenSigTimeoutTime_AGSM" SG_ 271 MessageCounter_ENGINE_HYBD_FD_1 0;
BA_ "GenSigTimeoutTime_ECM" SG_ 271 MessageCounter_ENGINE_HYBD_FD_1 0;
BA_ "GenSigTimeoutTime_MCPA" SG_ 271 MessageCounter_ENGINE_HYBD_FD_1 0;
BA_ "GenSigTimeoutTime_MCPB" SG_ 271 MessageCounter_ENGINE_HYBD_FD_1 0;
BA_ "GenSigTimeoutTime_SGCP" SG_ 271 MessageCounter_ENGINE_HYBD_FD_1 0;
BA_ "GenSigTimeoutTime_EVCU2" SG_ 271 MaxPrdtdEngTorqCapV 0;
BA_ "GenSigTimeoutTime_AGSM" SG_ 271 MaxPrdtdEngTorqCapV 0;
BA_ "GenSigTimeoutTime_ECM" SG_ 271 MaxPrdtdEngTorqCapV 0;
BA_ "GenSigTimeoutTime_MCPA" SG_ 271 MaxPrdtdEngTorqCapV 0;
BA_ "GenSigTimeoutTime_MCPB" SG_ 271 MaxPrdtdEngTorqCapV 0;
BA_ "GenSigTimeoutTime_SGCP" SG_ 271 MaxPrdtdEngTorqCapV 0;
BA_ "GenSigTimeoutTime_EVCU2" SG_ 271 MaxPrdtdEngTorqCap 0;
BA_ "GenSigStartValue" SG_ 271 MaxPrdtdEngTorqCap 938;
BA_ "GenSigTimeoutTime_AGSM" SG_ 271 MaxPrdtdEngTorqCap 0;
BA_ "GenSigTimeoutTime_ECM" SG_ 271 MaxPrdtdEngTorqCap 0;
BA_ "GenSigTimeoutTime_MCPA" SG_ 271 MaxPrdtdEngTorqCap 0;
BA_ "GenSigTimeoutTime_MCPB" SG_ 271 MaxPrdtdEngTorqCap 0;
BA_ "GenSigTimeoutTime_SGCP" SG_ 271 MaxPrdtdEngTorqCap 0;
BA_ "GenSigStartValue" SG_ 271 MaxOffEngTorqCap 938;
BA_ "GenSigTimeoutTime_AGSM" SG_ 271 MaxOffEngTorqCap 0;
BA_ "GenSigTimeoutTime_ECM" SG_ 271 MaxOffEngTorqCap 0;
BA_ "GenSigTimeoutTime_MCPA" SG_ 271 MaxOffEngTorqCap 0;
BA_ "GenSigTimeoutTime_MCPB" SG_ 271 MaxOffEngTorqCap 0;
BA_ "GenSigTimeoutTime_SGCP" SG_ 271 MaxOffEngTorqCap 0;
BA_ "GenSigTimeoutTime_TCM" SG_ 271 MaxOffEngTorqCap 0;
BA_ "GenSigTimeoutTime_AGSM" SG_ 271 HybActEngTorqRespTyp 0;
BA_ "GenSigTimeoutTime_ECM" SG_ 271 HybActEngTorqRespTyp 0;
BA_ "GenSigTimeoutTime_MCPA" SG_ 271 HybActEngTorqRespTyp 0;
BA_ "GenSigTimeoutTime_MCPB" SG_ 271 HybActEngTorqRespTyp 0;
BA_ "GenSigTimeoutTime_SGCP" SG_ 271 HybActEngTorqRespTyp 0;
BA_ "GenSigTimeoutTime_TCM" SG_ 271 HybActEngTorqRespTyp 0;
BA_ "GenSigTimeoutTime_AGSM" SG_ 271 Feedback_HCP 0;
BA_ "GenSigTimeoutTime_ECM" SG_ 271 Feedback_HCP 0;
BA_ "GenSigTimeoutTime_MCPA" SG_ 271 Feedback_HCP 0;
BA_ "GenSigTimeoutTime_MCPB" SG_ 271 Feedback_HCP 0;
BA_ "GenSigTimeoutTime_SGCP" SG_ 271 Feedback_HCP 0;
BA_ "GenSigTimeoutTime_TCM" SG_ 271 Feedback_HCP 0;
BA_ "GenSigTimeoutTime_AGSM" SG_ 271 ETRQ_Mode 0;
BA_ "GenSigTimeoutTime_ECM" SG_ 271 ETRQ_Mode 0;
BA_ "GenSigTimeoutTime_MCPA" SG_ 271 ETRQ_Mode 0;
BA_ "GenSigTimeoutTime_MCPB" SG_ 271 ETRQ_Mode 0;
BA_ "GenSigTimeoutTime_SGCP" SG_ 271 ETRQ_Mode 0;
BA_ "GenSigTimeoutTime_TCM" SG_ 271 ETRQ_Mode 0;
BA_ "GenSigTimeoutTime_AGSM" SG_ 271 EngTrqReserveReq 0;
BA_ "GenSigTimeoutTime_ECM" SG_ 271 EngTrqReserveReq 0;
BA_ "GenSigTimeoutTime_MCPA" SG_ 271 EngTrqReserveReq 0;
BA_ "GenSigTimeoutTime_MCPB" SG_ 271 EngTrqReserveReq 0;
BA_ "GenSigTimeoutTime_SGCP" SG_ 271 EngTrqReserveReq 0;
BA_ "GenSigTimeoutTime_TCM" SG_ 271 EngTrqReserveReq 0;
BA_ "GenSigTimeoutTime_AGSM" SG_ 271 EngRunCrnkAct 0;
BA_ "GenSigTimeoutTime_ECM" SG_ 271 EngRunCrnkAct 0;
BA_ "GenSigTimeoutTime_MCPA" SG_ 271 EngRunCrnkAct 0;
BA_ "GenSigTimeoutTime_MCPB" SG_ 271 EngRunCrnkAct 0;
BA_ "GenSigTimeoutTime_SGCP" SG_ 271 EngRunCrnkAct 0;
BA_ "GenSigTimeoutTime_TCM" SG_ 271 EngRunCrnkAct 0;
BA_ "GenSigTimeoutTime_EVCU2" SG_ 271 EngAirFlwStdyStTorqV 0;
BA_ "GenSigTimeoutTime_AGSM" SG_ 271 EngAirFlwStdyStTorqV 0;
BA_ "GenSigTimeoutTime_ECM" SG_ 271 EngAirFlwStdyStTorqV 0;
BA_ "GenSigTimeoutTime_MCPA" SG_ 271 EngAirFlwStdyStTorqV 0;
BA_ "GenSigTimeoutTime_MCPB" SG_ 271 EngAirFlwStdyStTorqV 0;
BA_ "GenSigTimeoutTime_SGCP" SG_ 271 EngAirFlwStdyStTorqV 0;
BA_ "GenSigTimeoutTime_EVCU2" SG_ 271 EngAirFlwStdyStTorq 0;
BA_ "GenSigStartValue" SG_ 271 EngAirFlwStdyStTorq 938;
BA_ "GenSigTimeoutTime_AGSM" SG_ 271 EngAirFlwStdyStTorq 0;
BA_ "GenSigTimeoutTime_ECM" SG_ 271 EngAirFlwStdyStTorq 0;
BA_ "GenSigTimeoutTime_MCPA" SG_ 271 EngAirFlwStdyStTorq 0;
BA_ "GenSigTimeoutTime_MCPB" SG_ 271 EngAirFlwStdyStTorq 0;
BA_ "GenSigTimeoutTime_SGCP" SG_ 271 EngAirFlwStdyStTorq 0;
BA_ "GenSigTimeoutTime_AGSM" SG_ 271 EngActuatorsStat 0;
BA_ "GenSigTimeoutTime_ECM" SG_ 271 EngActuatorsStat 0;
BA_ "GenSigTimeoutTime_MCPA" SG_ 271 EngActuatorsStat 0;
BA_ "GenSigTimeoutTime_MCPB" SG_ 271 EngActuatorsStat 0;
BA_ "GenSigTimeoutTime_SGCP" SG_ 271 EngActuatorsStat 0;
BA_ "GenSigTimeoutTime_TCM" SG_ 271 EngActuatorsStat 0;
BA_ "GenSigTimeoutTime_AGSM" SG_ 271 EngActStdyStTorqV 0;
BA_ "GenSigTimeoutTime_ECM" SG_ 271 EngActStdyStTorqV 0;
BA_ "GenSigTimeoutTime_MCPA" SG_ 271 EngActStdyStTorqV 0;
BA_ "GenSigTimeoutTime_MCPB" SG_ 271 EngActStdyStTorqV 0;
BA_ "GenSigTimeoutTime_SGCP" SG_ 271 EngActStdyStTorqV 0;
BA_ "GenSigTimeoutTime_TCM" SG_ 271 EngActStdyStTorqV 0;
BA_ "GenSigStartValue" SG_ 271 EngActStdyStTorq 938;
BA_ "GenSigTimeoutTime_AGSM" SG_ 271 EngActStdyStTorq 0;
BA_ "GenSigTimeoutTime_ECM" SG_ 271 EngActStdyStTorq 0;
BA_ "GenSigTimeoutTime_MCPA" SG_ 271 EngActStdyStTorq 0;
BA_ "GenSigTimeoutTime_MCPB" SG_ 271 EngActStdyStTorq 0;
BA_ "GenSigTimeoutTime_SGCP" SG_ 271 EngActStdyStTorq 0;
BA_ "GenSigTimeoutTime_TCM" SG_ 271 EngActStdyStTorq 0;
BA_ "GenSigTimeoutTime_EVCU2" SG_ 271 CRC_ENGINE_HYBD_FD_1 0;
BA_ "GenSigTimeoutTime_AGSM" SG_ 271 CRC_ENGINE_HYBD_FD_1 0;
BA_ "GenSigTimeoutTime_ECM" SG_ 271 CRC_ENGINE_HYBD_FD_1 0;
BA_ "GenSigTimeoutTime_MCPA" SG_ 271 CRC_ENGINE_HYBD_FD_1 0;
BA_ "GenSigTimeoutTime_MCPB" SG_ 271 CRC_ENGINE_HYBD_FD_1 0;
BA_ "GenSigTimeoutTime_SGCP" SG_ 271 CRC_ENGINE_HYBD_FD_1 0;
BA_ "GenSigStartValue" SG_ 271 MAP_4_BAR_PHEV 511;
BA_ "GenSigTimeoutTime_AGSM" SG_ 271 MAP_4_BAR_PHEV 0;
BA_ "GenSigTimeoutTime_ECM" SG_ 271 MAP_4_BAR_PHEV 0;
BA_ "GenSigTimeoutTime_MCPA" SG_ 271 MAP_4_BAR_PHEV 0;
BA_ "GenSigTimeoutTime_MCPB" SG_ 271 MAP_4_BAR_PHEV 0;
BA_ "GenSigTimeoutTime_SGCP" SG_ 271 MAP_4_BAR_PHEV 0;
BA_ "GenSigTimeoutTime_TCM" SG_ 271 MAP_4_BAR_PHEV 0;
BA_ "GenSigTimeoutTime_AGSM" SG_ 271 RedSpkAuthorityAvbl 0;
BA_ "GenSigTimeoutTime_ECM" SG_ 271 RedSpkAuthorityAvbl 0;
BA_ "GenSigTimeoutTime_MCPA" SG_ 271 RedSpkAuthorityAvbl 0;
BA_ "GenSigTimeoutTime_MCPB" SG_ 271 RedSpkAuthorityAvbl 0;
BA_ "GenSigTimeoutTime_SGCP" SG_ 271 RedSpkAuthorityAvbl 0;
BA_ "GenSigTimeoutTime_TCM" SG_ 271 RedSpkAuthorityAvbl 0;
BA_ "GenSigTimeoutTime_AGSM" SG_ 271 EngMinSparkNomCurrAirTorqCap 0;
BA_ "GenSigTimeoutTime_ECM" SG_ 271 EngMinSparkNomCurrAirTorqCap 0;
BA_ "GenSigTimeoutTime_MCPA" SG_ 271 EngMinSparkNomCurrAirTorqCap 0;
BA_ "GenSigTimeoutTime_MCPB" SG_ 271 EngMinSparkNomCurrAirTorqCap 0;
BA_ "GenSigTimeoutTime_SGCP" SG_ 271 EngMinSparkNomCurrAirTorqCap 0;
BA_ "GenSigTimeoutTime_TCM" SG_ 271 EngMinSparkNomCurrAirTorqCap 0;
BA_ "GenSigTimeoutTime_AGSM" SG_ 271 EngTrqFSO_CurrAir 0;
BA_ "GenSigTimeoutTime_ECM" SG_ 271 EngTrqFSO_CurrAir 0;
BA_ "GenSigTimeoutTime_EVCU2" SG_ 271 EngTrqFSO_CurrAir 0;
BA_ "GenSigTimeoutTime_MCPA" SG_ 271 EngTrqFSO_CurrAir 0;
BA_ "GenSigTimeoutTime_MCPB" SG_ 271 EngTrqFSO_CurrAir 0;
BA_ "GenSigTimeoutTime_SGCP" SG_ 271 EngTrqFSO_CurrAir 0;
VAL_ 1450 TxDisengaged 0 "Engaged" 1 "Disengaged" ;
VAL_ 1450 TransmissionFailSts 0 "Fail_not_present" 1 "Fail_present" ;
VAL_ 1450 ShiftLeverPosition 0 "No_Selection_Active_Or_Available" 1 "P" 2 "R" 3 "N" 4 "D" 5 "L" 6 "TIP_Autostick" 7 "Plus" 8 "Minus" 9 "Sport" 10 "Not_Used" 11 "Not_Used" 12 "Not_Used" 13 "Not_Used" 14 "Not_Used" 15 "SNA" ;
VAL_ 1450 ShiftLeverLockReq 0 "Not_Active" 1 "Active" ;
VAL_ 1450 ShiftInProgress 0 "No Shift in progress" 1 "Shift in progress" ;
VAL_ 1450 MIReq 0 "No_EOBD_error" 1 "EOBD_error" ;
VAL_ 1450 LimpHomeSts 0 "NotActive" 1 "Active" ;
VAL_ 1450 GearIndicationSts 0 "Normal" 1 "Blinking" ;
VAL_ 1450 GearEngaged 0 "Neutral" 1 "ForwardGear_1" 2 "ForwardGear_2" 3 "ForwardGear_3" 4 "ForwardGear_4" 5 "ForwardGear_5" 6 "ForwardGear_6" 7 "ForwardGear_7" 8 "ForwardGear_8" 9 "ForwardGear_9" 13 "Parking" 14 "ReverseGear" 15 "SNA" ;
VAL_ 1450 CrankEnable 0 "Disabled" 1 "Enabled" ;
VAL_ 1450 ShiftMapNotAchieved 0 "Achieved" 1 "Not_Achieved" ;
VAL_ 1450 R_SHFT_LOCK 0 "Unlocked" 1 "Locked" ;
VAL_ 1450 DriveModeSts 0 "No_programs_available_selected" 1 "Eco" 2 "Sport" 3 "Valet" 4 "Ice_Winter" 5 "Tow_Haul" 6 "Track" 7 "4LowMode" 8 "HDC/SSC" 9 "Rock" 10 "Sand" 11 "Mud" 12 "Normal" 13 "Mud_Sand" 14 "RRCC" 15 "Drag" ;
VAL_ 1450 TxDisengaged_Fault 0 "No_Fault" 1 "Fault" ;
VAL_ 1450 Lowmode_Indication_Sts 0 "OFF" 1 "Normal" 2 "Blinking" 3 "SNA" ;
VAL_ 1450 Low_Mode_Sts 0 "Not_Active" 1 "Active" 3 "SNA" ;
VAL_ 520 TurbineSpeed 65535 "SNA" ;
VAL_ 520 TRNS_StpSt_FLT 0 "Not_Present" 1 "Present" ;
VAL_ 520 Trns_EMCC_Achvd 0 "False" 1 "True" ;
VAL_ 520 TransReadyForESS 0 "Not_Ready" 1 "Ready" ;
VAL_ 520 TransmissionTemperature 63 "SNA" ;
VAL_ 520 OUTPUT_SPEED 65535 "SNA" ;
VAL_ 520 APCM_Rq 0 "OFF" 1 "ON" 2 "PENDING" 3 "SNA" ;
VAL_ 520 EngShutOffRq_TCM 0 "FALSE" 1 "TRUE" ;
VAL_ 520 Trans_ESS_Inhibit 0 "False" 1 "True" ;
VAL_ 520 OutputSpdPolarity 0 "DND" 1 "DF" 2 "DB" 3 "SNA" ;
VAL_ 520 GearEngagedForDisplay 0 "Initialize" 1 "1st_gear" 2 "2nd_gear" 3 "3rd_gear" 4 "4th_gear" 5 "5th_gear" 6 "6th_gear" 7 "7th_gear" 8 "8th_gear " 9 "9th_gear" 10 "Not_used1" 11 "Not_Used2" 12 "P" 13 "N" 14 "R" 15 "D" 16 "L" 17 "M" 18 "S" 31 "SNA" ;
VAL_ 520 AirFlowRequest_TCM 127 "SNA" ;
VAL_ 520 TrqCtrlModeReq_Prdtd 0 "None" 1 "TRQ_INC" 2 "TRQ_DEC" 3 "SNA" ;
VAL_ 520 TCM_TrqGradLimActive 0 "Not_Active" 1 "Active" ;
VAL_ 520 TCM_TrqGradLim_Up 255 "SNA" ;
VAL_ 520 TCM_TrqGradLim_Lo 255 "SNA" ;
VAL_ 520 TCM_EngFSO_Rq 0 "FSO_Not_Requested" 1 "FSO_Requested" ;
VAL_ 520 TCM_EngFSO_Allw 0 "FSO_Not_Allowed" 1 "Normal_FSO_Allowed" ;
VAL_ 520 TransInputSpeedMaxReq 1023 "SNA" ;
VAL_ 156 GPS_UTC_Second 65535 "SNA" ;
VAL_ 156 GPS_UTC_Minute 255 "SNA" ;
VAL_ 156 GPS_UTC_Hour 255 "SNA" ;
VAL_ 156 GPS_Date_Year 65535 "SNA" ;
VAL_ 156 GPS_Date_Month 255 "SNA" ;
VAL_ 156 GPS_Date_Day 255 "SNA" ;
VAL_ 1058 InputsGDFail 0 "False" 1 "True" ;
VAL_ 1058 Inp_ICC_Fail 0 "Fail_Not_Present" 1 "Fail_Present" ;
VAL_ 1058 IgnCntrTrue 0 "False" 1 "True" ;
VAL_ 1058 GenDenominator 0 "False" 1 "True" ;
VAL_ 1058 EngineOFFTime 1023 "SNA" ;
VAL_ 1058 CldStrtDenominator 0 "Not_Active" 1 "Active" ;
VAL_ 1058 CarbWarmUp 0 "False" 1 "True" ;
VAL_ 1058 CARB_PERM 0 "False" 1 "True" ;
VAL_ 1058 OAT_PT_EstV 0 "Valid" 1 "Not_Valid" ;
VAL_ 1058 EngOffTmPTV 1 "SNA" ;
VAL_ 1058 EngOffTmPT 0 "SNA" ;
VAL_ 1626 IMPACTConfirm 0 "Actuate" 1 "Do_Not_Actuate" ;
VAL_ 1626 IMPACTCommand 0 "Do_Not_Actuate" 1 "Actuate" ;
VAL_ 1055 MdsAct 0 "Not Active" 1 "Active" ;
VAL_ 1448 CompressorSts 0 "Not_Used" 1 "Not_inserted_by_NCM" 2 "Not_insrtd_by_driver_or_security" 3 "Inserted" ;
VAL_ 1448 SpStSwStat 0 "OFF" 1 "CONT" 2 "BLINK" 3 "SNA" ;
VAL_ 1448 SpStDispstat 0 "NONE" 1 "PCR_OPENS" 3 "ACTIVE" 4 "D_OR_SB" 5 "NR_DRV_NOT_DET" 6 "DR_INHIB" 7 "TX_INHIB" 8 "KEY" 9 "BATT" 10 "SYSFLT" 11 "NR" 12 "READY" 13 "OFF" 14 "HOOD" 15 "PEDAL" 16 "BATT_CHG" 17 "TM" 18 "T4WD_L" 20 "INCLINE" 21 "AMB_TEMP" 23 "SB" 24 "DR_AJAR" 25 "CABIN" 26 "MAX_HVAC" 27 "FT_DEFROST" 29 "ST_WHEEL" 30 "Eng_Temp_Hi" 31 "Eng_Temp_Lo" 32 "Prk_Brk_Inhib" 33 "Park_Inhib" 34 "Hood_Inhib" 35 "DPF_Regen" 38 "BATT_HIGH" 63 "SNA" ;
VAL_ 751 StartRelayECMFeedbackFault 0 "False" 1 "True" ;
VAL_ 751 EngineWaterTemp 255 "SNA" ;
VAL_ 751 TerrainModeStat_ECM 0 "Auto" 1 "Auto_Fault" 2 "Rock" 3 "Track" 4 "Snow" 5 "Offroad" 6 "Eco" 7 "Corsa" 8 "Sport" 9 "Mud_Sand" 10 "Mud" 11 "Sand" 12 "Valet" 13 "Custom" 14 "Tow" 15 "DRAG" 16 "BAJA" 31 "SNA" ;
VAL_ 751 Trns_DrvMdReq_ECM 0 "NP" 1 "STREET" 2 "VALET" 3 "SPORT" 4 "S_PLUS" 5 "TRACK" 6 "ECO" 7 "SNOW" 8 "ROCK " 9 "TOW" 10 "DRAG" 11 "MUD" 12 "SAND" 13 "BAJA" 14 "OFFROAD" 31 "SNA" ;
VAL_ 518 RPMOverRev_W 0 "FALSE" 1 "TRUE" ;
VAL_ 518 GrMin_Rq_ECM_W 0 "Passive" 1 "G1" 2 "G2" 3 "G3" 4 "G4" 5 "G5" 6 "G6" 7 "G7" 8 "G8" 9 "G9" ;
VAL_ 518 GrMax_Rq_ECM_W 0 "Passive" 1 "G1" 2 "G2" 3 "G3" 4 "G4" 5 "G5" 6 "G6" 7 "G7" 8 "G8" 9 "G9" ;
VAL_ 518 EngTrqMaxCorrFctr_W 255 "SNA" ;
VAL_ 518 EngineReadyForESS_W 0 "Not_Active" 1 "Active" ;
VAL_ 518 ECM_READINESS_RESET_W 0 "Not Set" 1 "Set" ;
VAL_ 518 ECM_CODE_CLR_W 0 "Not Cleared" 1 "Cleared" ;
VAL_ 1054 VehicleSetSpeed_W 255 "SNA" ;
VAL_ 1054 TransWarmUpReq 0 "WarmUp_Not_Enabled" 1 "WarmUp_Enabled" ;
VAL_ 1054 TransWarmUpMin_RPM 255 "SNA" ;
VAL_ 1054 ThermalManagementActive_W 0 "Not_active" 1 "Active" ;
VAL_ 1054 EngMaxRPM_W 255 "SNA" ;
VAL_ 1054 AtmosphericPressureFailSts_W 0 "Fail_Not_Present" 1 "Fail_Present" ;
VAL_ 1054 AtmosphericPressure_W 255 "SNA" ;
VAL_ 1155 ESCFailSts 0 "Fail_Not_Present" 1 "Fail_Present" ;
VAL_ 1155 ABSFailSts 0 "Fail_Not_Present" 1 "Fail_Present" ;
VAL_ 609 EPBSts 0 "Released" 1 "Applied" 2 "DynamicBrkESC" 3 "DynamicBrkEPB" 4 "Emergency_Braking" 5 "Applying" 6 "Maintenance_Mode" 7 "Assembly_Check" 8 "Inspection_Mode" 9 "Re_Clamping" 10 "Adjuste_Mode" 11 "Releasing" 12 "Fault_EPB_Released" 13 "Fault_EPB_Applied" 14 "Fault_Present" 15 "SNA" ;
VAL_ 1066 ExternalTemperature 511 "SNA" ;
VAL_ 1153 CmdIgnSts 0 "Initialization" 1 "IGN_LK" 3 "ACC" 4 "RUN" 5 "START" 7 "SNA" ;
VAL_ 255 SumTorqueTgt_SEM 2047 "SNA" ;
VAL_ 255 SumTorqueStatic_SEM 2047 "SNA" ;
VAL_ 255 SumTorqueStatic 2047 "SNA" ;
VAL_ 255 SumTorqueSel_D_TTC 2047 "SNA" ;
VAL_ 255 SumTorqueMin 2047 "SNA" ;
VAL_ 255 SumTorqueMax 2047 "SNA" ;
VAL_ 255 SumTorque_DrvReqMod 8191 "SNA" ;
VAL_ 255 Accel_Pedal_Override 0 "FALSE" 1 "TRUE" ;
VAL_ 1032 SGCP_OIL_TEMP 255 "SNA" ;
VAL_ 1032 SGCP_OIL_FlwRate 255 "SNA" ;
VAL_ 1032 EOPB_OIL_TEMP 255 "SNA" ;
VAL_ 1032 EOPB_OIL_FlwRate 255 "SNA" ;
VAL_ 1032 EOPA_OIL_TEMP 255 "SNA" ;
VAL_ 1032 EOPA_OIL_FlwRate 255 "SNA" ;
VAL_ 1033 IdleCLoopTrq 1023 "SNA" ;
VAL_ 1033 HCPMaxEngRPM 255 "SNA" ;
VAL_ 1033 HCP_HoodAjar 0 "Closed" 1 "Ajar" 2 "Faulted" 3 "SNA" ;
VAL_ 1328 EngTorqCapbltyMinTorq 4095 "SNA" ;
VAL_ 1328 EngTorqCapbltyMaxTorq 4095 "SNA" ;
VAL_ 1328 EngTorqCapbltyMaxOffTorq 4095 "SNA" ;
VAL_ 1328 EngTorqCapbltyMinRunTorq 4095 "SNA" ;
VAL_ 1328 EngTorqACCCapability 255 "SNA" ;
VAL_ 1035 EngCltTmpV 0 "False" 1 "True" ;
VAL_ 1035 EngCltTmp 255 "SNA" ;
VAL_ 1036 CruiseControlSts 0 "Not_inserted" 1 "Inserted" ;
VAL_ 1036 CruiseControlLampSts 0 "Not_inserted" 1 "Inserted" ;
VAL_ 1036 EngineOilTemperature 255 "SNA" ;
VAL_ 278 TransmissionSailingSts 0 "Sailing_Not Possible" 1 "Sailing_Possible_Passive" 2 "Transition_To_Sailing" 3 "Sailing_Active" 4 "Transition_Out_Of_Sailing" 5 "Sailing_Not_Available" 15 "SNA" ;
VAL_ 278 TransLosses 1023 "SNA" ;
VAL_ 278 TorqueConverterSts 0 "Lock_up_clutch_opened" 1 "Lock_up_clutch_is_slipping" 2 "Lock_up_clutch_closed" 3 "SNA" ;
VAL_ 278 TorqueConverterSTO 0 "Not_Active" 1 "Active" ;
VAL_ 278 TargetGear 0 "Neutral" 1 "ForwardGear_1" 2 "ForwardGear_2" 3 "ForwardGear_3" 4 "ForwardGear_4" 5 "ForwardGear_5" 6 "ForwardGear_6" 7 "ForwardGear_7" 8 "ForwardGear_8" 9 "ForwardGear_9" 13 "Parking" 14 "ReverseGear" 15 "SNA" ;
VAL_ 278 MaxTrqDes 2047 "SNA" ;
VAL_ 278 EngTrq_Rq_TCM 2047 "SNA" ;
VAL_ 278 REPRGD_PFC_CLR_TCM 0 "Do Nothing" 1 "Set Incomplete" ;
VAL_ 278 PaddleShiftRequest 0 "PS_OFF" 1 "PS_RIGHT" 2 "PS_LEFT" 3 "PS_BOTH" 7 "SNA" ;
VAL_ 278 DriveLineRatio 16383 "SNA" ;
VAL_ 278 CODE_CLR_TCM 0 "Not Clear" 1 "Clear" ;
VAL_ 278 TxIdleRq 255 "SNA" ;
VAL_ 278 TCASERANGESTATUS_TCM 0 "High" 1 "Neutral" 2 "Low" 3 "SNA" ;
VAL_ 278 Trans_Adapt_Status 0 "No_Routine_Running" 1 "Shift_Clutches_Pulse_Adapt_Eng_On" 2 "Shift_Clutches_Pulse_Adapt_EV_Md" 3 "K0_Pulse_Adapt" 4 "ILE_Adapt" 5 "STADA_Shift_Clutches_Adapt" 6 "STADA_K0_Adapt" 7 "STADA_ILE_Adapt" 8 "EOLAD_Shift_Clutches_Adapt" 9 "EOLAD_K0_Adapt" 10 "Start_Adapt" ;
VAL_ 278 TorqueAmpTransmission 2047 "SNA" ;
VAL_ 278 TrqCtrlModeReq 0 "None" 1 "TRQ_INC" 2 "TRQ_DEC" 3 "SNA" ;
VAL_ 278 TransIntakeTorq 2047 "SNA" ;
VAL_ 278 CrankEnable_Fast 0 "Disabled" 1 "Enabled" ;
VAL_ 278 EngTrq_Rq_TCM_Prdtd 2047 "SNA" ;
VAL_ 278 PumpTrqOnImpShaft 1023 "SNA" ;
VAL_ 269 PropulsionMode 0 "Hybrid_Parallel" 1 "EV_Only" 2 "Hybrid_Series" 7 "SNA" ;
VAL_ 269 HybridEngineMaxTorqAllowed 4095 "SNA" ;
VAL_ 276 InputSpdRaw 4095 "SNA" ;
VAL_ 276 HybEstEngTorq 4095 "SNA" ;
VAL_ 276 HybCmndEngTorqRespTyp 0 "Inactive" 1 "PL" 2 "MR" 3 "SNA" ;
VAL_ 276 HybCmndEngTorqPrdtd 4095 "SNA" ;
VAL_ 276 HybCmndEngTorqImmed 4095 "SNA" ;
VAL_ 276 EngTrqReserveCmd 255 "SNA" ;
VAL_ 276 PropulsionSystemActive 0 "Not_Active" 1 "Active" ;
VAL_ 271 Sum_FW_ID_Slw 31 "SNA" ;
VAL_ 271 Sum_FW_ID_Fst 31 "SNA" ;
VAL_ 271 MinPrdtdEngRunTorqCapV 0 "Valid" 1 "Not_Valid" ;
VAL_ 271 MinPrdtdEngRunTorqCap 4095 "SNA" ;
VAL_ 271 MinImmedEngTorqCapV 0 "Valid" 1 "Not_Valid" ;
VAL_ 271 MinImmedEngTorqCap 4095 "SNA" ;
VAL_ 271 MinEngTorqCapV 0 "Valid" 1 "Not_Valid" ;
VAL_ 271 MinEngTorqCap 4095 "SNA" ;
VAL_ 271 MinAirFlowMinSparkTorqCap 4095 "SNA" ;
VAL_ 271 MaxPrdtdEngTorqCapV 0 "Valid" 1 "Not_Valid" ;
VAL_ 271 MaxPrdtdEngTorqCap 4095 "SNA" ;
VAL_ 271 MaxOffEngTorqCap 4095 "SNA" ;
VAL_ 271 HybActEngTorqRespTyp 0 "Inactive" 1 "Pleasability_Limited" 2 "Maximum_Range" ;
VAL_ 271 ETRQ_Mode 7 "SNA" ;
VAL_ 271 EngTrqReserveReq 255 "SNA" ;
VAL_ 271 EngAirFlwStdyStTorqV 0 "Valid" 1 "Not_Valid" ;
VAL_ 271 EngAirFlwStdyStTorq 4095 "SNA" ;
VAL_ 271 EngActuatorsStat 0 "ACPP" 1 "SCPP" 2 "ACPA" ;
VAL_ 271 EngActStdyStTorqV 0 "Valid" 1 "Not_Valid" ;
VAL_ 271 EngActStdyStTorq 4095 "SNA" ;
VAL_ 271 MAP_4_BAR_PHEV 511 "SNA" ;
VAL_ 271 RedSpkAuthorityAvbl 0 "Not_Available" 1 "Available" ;
VAL_ 271 EngMinSparkNomCurrAirTorqCap 2047 "SNA" ;
VAL_ 271 EngTrqFSO_CurrAir 4095 "SNA" ;
SIG_GROUP_ 1450 TRANSM_FD_4_Pkt 1 : TxDisengaged TransmissionFailSts ShiftLeverPosition ShiftLeverLockReq ShiftInProgress MIReq LimpHomeSts GearIndicationSts GearEngaged CrankEnable ShiftMapNotAchieved R_SHFT_LOCK MessageCounter_TRANSM4 CRC_TRANSM4 DriveModeSts TxDisengaged_Fault Lowmode_Indication_Sts Low_Mode_Sts;
SIG_GROUP_ 520 TRANSM_FD_2_Pkt 1 : TurbineSpeed TRNS_StpSt_FLT Trns_EMCC_Achvd TransReadyForESS TransmissionTemperature OUTPUT_SPEED APCM_Rq MessageCounter_TRANSM2 EngShutOffRq_TCM CRC_TRANSM2 Trans_ESS_Inhibit OutputSpdPolarity GearEngagedForDisplay AirFlowRequest_TCM TrqCtrlModeReq_Prdtd TCM_TrqGradLimActive TCM_TrqGradLim_Up TCM_TrqGradLim_Lo TCM_EngFSO_Rq TCM_EngFSO_Allw TCC_TR TransInputSpeedMaxReq;
SIG_GROUP_ 1058 OBD_CONTENT_FRAME_Pkt 1 : LoadOBD InputsGDFail Inp_ICC_Fail IgnCntrTrue GenDenominator EngineOFFTime CldStrtDenominator CarbWarmUp CARB_PERM AccelPdlPosn_OBD OAT_PT_EstV OAT_PT_Est EngOffTmPTV EngOffTmPT MessageCounter_OBDCONTENTFRAME CRC_OBDCONTENTFRAME;
SIG_GROUP_ 1055 ENGINE_FD_8_Pkt 1 : MdsAct MessageCounter_ENGINE8 CRC_ENGINE8;
SIG_GROUP_ 1448 ENGINE_FD_7_Pkt 1 : CompressorSts SpStSwStat SpStDispstat MessageCounter_ENGINE7 CRC_ENGINE7;
SIG_GROUP_ 751 ENGINE_FD_6_Pkt 1 : StartRelayECMFeedbackFault EngineWaterTemp TerrainModeStat_ECM MessageCounter_ENGINE6 CRC_ENGINE6 Trns_DrvMdReq_ECM;
SIG_GROUP_ 518 ENGINE_FD_5_Pkt 1 : RPMOverRev_W MessageCounter_ENGINE5 GrMin_Rq_ECM_W GrMax_Rq_ECM_W EngTrqMaxCorrFctr_W EngineReadyForESS_W ECM_READINESS_RESET_W ECM_CODE_CLR_W CRC_ENGINE5;
SIG_GROUP_ 1054 ENGINE_FD_1_Pkt 1 : VehicleSetSpeed_W TransWarmUpReq TransWarmUpMin_RPM ThermalManagementActive_W MessageCounter_ENGINE1 EngMaxRPM_W CRC_ENGINE1 AtmosphericPressureFailSts_W AtmosphericPressure_W;
SIG_GROUP_ 255 PT_TORQUE_FD_1_Pkt 1 : SumTorqueTgt_SEM SumTorqueStatic_SEM SumTorqueStatic SumTorqueSel_D_TTC SumTorqueMin SumTorqueMax SumTorque_DrvReqMod MessageCounter_PT_TORQUE_FD_1 CRC_PT_TORQUE_FD_1 Accel_Pedal_Override;
SIG_GROUP_ 1033 HYBRID_POWERTRAIN5_Pkt 1 : IdleCLoopTrq HEV_HybPwrtrnRdcdPerfCmnd HCPMaxEngRPM CRC_HYBRID_POWERTRAIN5 MessageCounter_HYBRID_POWERTRAIN HCP_HoodAjar;
SIG_GROUP_ 1328 ENGINE_HYBD_FD_4_Pkt 1 : EngTorqCapbltyMinTorq EngTorqCapbltyMaxTorq EngTorqCapbltyMaxOffTorq EngTorqCapbltyRefEngSpd EngTorqCapbltyMinRunTorq EngTorqCapbltyFrmCntr EngTorqCapbltyEngOpMd EngTorqACCCapability MessageCounter_ENGINE_HYBD_FD_4 CRC_ENGINE_HYBD_FD_4;
SIG_GROUP_ 1035 ENGINE_HYBD_FD_3_Pkt 1 : MaxEngSpdCap ServiceHybSys MinEngSpdCap EngSpd EngCltTmpV EngCltTmp MessageCounter_ENGINE_HYBD_FD_3 CRC_ENGINE_HYBD_FD_3;
SIG_GROUP_ 1036 ENGINE_FD_3_Pkt 1 : CruiseControlSts CruiseControlLampSts MessageCounter_ENGINE3 CRC_ENGINE3 EngineOilTemperature;
SIG_GROUP_ 278 TRANSM_FD_1_Pkt 1 : TransmissionSailingSts TransLosses TorqueConverterSts TorqueConverterSTO TargetGear MaxTrqDes EngTrq_Rq_TCM CRC_TRANSM1 REPRGD_PFC_CLR_TCM PaddleShiftRequest MessageCounter_TRANSM1 DriveLineRatio CODE_CLR_TCM TxIdleRq TCASERANGESTATUS_TCM Trans_Adapt_Status TorqueAmpTransmission TrqCtrlModeReq TransIntakeTorq CrankEnable_Fast EngTrq_Rq_TCM_Prdtd PumpTrqOnImpShaft;
SIG_GROUP_ 269 HYBRID_POWERTRAIN2_Pkt 1 : IdleSpeedActiveSts CRC_HYBRID_POWERTRAIN2 PropulsionMode HybridEngineMaxTorqAllowed MessageCounter_HYBRID_POWER_0000;
SIG_GROUP_ 276 HYBRID_POWERTRAIN1_Pkt 1 : TransInpSpdPrfl InputSpdRaw Hybrid_Remedial_Stop HybFeedback_Engine HybEstEngTorqV HybEstEngTorq HybCrnkAbrted HybCmndEngTorqRespTyp HybCmndEngTorqPrdtd HybCmndEngTorqImmed EngTrqReserveCmd EngCntrlMode ECMPrepIdleRes CRC_HYBRID_POWERTRAIN1 PropulsionSystemActive MessageCounter_HYBRID_POWER_0001;
SIG_GROUP_ 271 ENGINE_HYBD_FD_1_Pkt 1 : Sum_FW_ID_Slw Sum_FW_ID_Fst MinPrdtdEngRunTorqCapV MinPrdtdEngRunTorqCap MinImmedEngTorqCapV MinImmedEngTorqCap MinEngTorqCapV MinEngTorqCap MinAirFlowMinSparkTorqCapV MinAirFlowMinSparkTorqCap MessageCounter_ENGINE_HYBD_FD_1 MaxPrdtdEngTorqCapV MaxPrdtdEngTorqCap MaxOffEngTorqCap HybActEngTorqRespTyp Feedback_HCP ETRQ_Mode EngTrqReserveReq EngRunCrnkAct EngAirFlwStdyStTorqV EngAirFlwStdyStTorq EngActuatorsStat EngActStdyStTorqV EngActStdyStTorq CRC_ENGINE_HYBD_FD_1 MAP_4_BAR_PHEV RedSpkAuthorityAvbl EngMinSparkNomCurrAirTorqCap EngTrqFSO_CurrAir;
